VERSION ""

NS_ :

BS_:

BU_: RAD_RR RAD_RL RAD_FR RAD_FL RAD_FC CGW APA ADC

BO_ 425 APA_ECHO_DIRECT: 8 APA
 SG_ sens05De3Distance_APA m4 : 23|8@0+ (2,0) [0|500] "cm"  ADC
 SG_ sens08De2Quality_APA m7 : 35|4@0+ (10,0) [0|100] "%"  ADC
 SG_ deMsgChecksum_APA : 63|8@0+ (1,0) [0|255] ""  ADC
 SG_ sens03De2Quality_APA m2 : 35|4@0+ (10,0) [0|100] "%"  ADC
 SG_ sens12De2Distance_APA m11 : 15|8@0+ (2,0) [0|500] "cm"  ADC
 SG_ sens01De3Distance_APA m0 : 23|8@0+ (2,0) [0|500] "cm"  ADC
 SG_ sens02De1Quality_APA m1 : 39|4@0+ (10,0) [0|100] "%"  ADC
 SG_ sens07De3Quality_APA m6 : 47|4@0+ (10,0) [0|100] "%"  ADC
 SG_ sens05De1Quality_APA m4 : 39|4@0+ (10,0) [0|100] "%"  ADC
 SG_ sens10De2Distance_APA m9 : 15|8@0+ (2,0) [0|500] "cm"  ADC
 SG_ sens08De1Quality_APA m7 : 39|4@0+ (10,0) [0|100] "%"  ADC
 SG_ sens06De1Quality_APA m5 : 39|4@0+ (10,0) [0|100] "%"  ADC
 SG_ sens10De3Quality_APA m9 : 47|4@0+ (10,0) [0|100] "%"  ADC
 SG_ sens12De1Distance_APA m11 : 7|8@0+ (2,0) [0|500] "cm"  ADC
 SG_ sens11De1Quality_APA m10 : 39|4@0+ (10,0) [0|100] "%"  ADC
 SG_ sens11De2Distance_APA m10 : 15|8@0+ (2,0) [0|500] "cm"  ADC
 SG_ sens03De2Distance_APA m2 : 15|8@0+ (2,0) [0|500] "cm"  ADC
 SG_ sens12De3Distance_APA m11 : 23|8@0+ (2,0) [0|500] "cm"  ADC
 SG_ sens09De1Distance_APA m8 : 7|8@0+ (2,0) [0|500] "cm"  ADC
 SG_ sens04De1Quality_APA m3 : 39|4@0+ (10,0) [0|100] "%"  ADC
 SG_ sens01De2Distance_APA m0 : 15|8@0+ (2,0) [0|500] "cm"  ADC
 SG_ sens07De3Distance_APA m6 : 23|8@0+ (2,0) [0|500] "cm"  ADC
 SG_ sens07De2Quality_APA m6 : 35|4@0+ (10,0) [0|100] "%"  ADC
 SG_ sens04De1Distance_APA m3 : 7|8@0+ (2,0) [0|500] "cm"  ADC
 SG_ sens04De3Distance_APA m3 : 23|8@0+ (2,0) [0|500] "cm"  ADC
 SG_ sens04De2Distance_APA m3 : 15|8@0+ (2,0) [0|500] "cm"  ADC
 SG_ sens08De3Quality_APA m7 : 47|4@0+ (10,0) [0|100] "%"  ADC
 SG_ sens07De1Quality_APA m6 : 39|4@0+ (10,0) [0|100] "%"  ADC
 SG_ sens10De2Quality_APA m9 : 35|4@0+ (10,0) [0|100] "%"  ADC
 SG_ sens01De2Quality_APA m0 : 35|4@0+ (10,0) [0|100] "%"  ADC
 SG_ sens09De2Quality_APA m8 : 35|4@0+ (10,0) [0|100] "%"  ADC
 SG_ sens06De3Distance_APA m5 : 23|8@0+ (2,0) [0|500] "cm"  ADC
 SG_ sens09De1Quality_APA m8 : 39|4@0+ (10,0) [0|100] "%"  ADC
 SG_ sens06De1Distance_APA m5 : 7|8@0+ (2,0) [0|500] "cm"  ADC
 SG_ deMsgCounter_APA : 51|4@0+ (1,0) [0|15] ""  ADC
 SG_ sens07De2Distance_APA m6 : 15|8@0+ (2,0) [0|500] "cm"  ADC
 SG_ deMsgSensorIdx_APA M : 55|4@0+ (1,0) [0|11] ""  ADC
 SG_ sens12De2Quality_APA m11 : 35|4@0+ (10,0) [0|100] "%"  ADC
 SG_ sens10De1Quality_APA m9 : 39|4@0+ (10,0) [0|100] "%"  ADC
 SG_ sens04De3Quality_APA m3 : 47|4@0+ (10,0) [0|100] "%"  ADC
 SG_ sens11De3Quality_APA m10 : 47|4@0+ (10,0) [0|100] "%"  ADC
 SG_ sens03De1Quality_APA m2 : 39|4@0+ (10,0) [0|100] "%"  ADC
 SG_ sens12De1Quality_APA m11 : 39|4@0+ (10,0) [0|100] "%"  ADC
 SG_ sens09De3Quality_APA m8 : 47|4@0+ (10,0) [0|100] "%"  ADC
 SG_ sens05De2Quality_APA m4 : 35|4@0+ (10,0) [0|100] "%"  ADC
 SG_ sens06De3Quality_APA m5 : 47|4@0+ (10,0) [0|100] "%"  ADC
 SG_ sens01De3Quality_APA m0 : 47|4@0+ (10,0) [0|100] "%"  ADC
 SG_ sens09De2Distance_APA m8 : 15|8@0+ (2,0) [0|500] "cm"  ADC
 SG_ sens11De3Distance_APA m10 : 23|8@0+ (2,0) [0|500] "cm"  ADC
 SG_ sens02De2Distance_APA m1 : 15|8@0+ (2,0) [0|500] "cm"  ADC
 SG_ sens02De2Quality_APA m1 : 35|4@0+ (10,0) [0|100] "%"  ADC
 SG_ sens11De1Distance_APA m10 : 7|8@0+ (2,0) [0|500] "cm"  ADC
 SG_ sens02De1Distance_APA m1 : 7|8@0+ (2,0) [0|500] "cm"  ADC
 SG_ sens05De1Distance_APA m4 : 7|8@0+ (2,0) [0|500] "cm"  ADC
 SG_ sens03De3Quality_APA m2 : 47|4@0+ (10,0) [0|100] "%"  ADC
 SG_ sens08De2Distance_APA m7 : 15|8@0+ (2,0) [0|500] "cm"  ADC
 SG_ sens05De2Distance_APA m4 : 15|8@0+ (2,0) [0|500] "cm"  ADC
 SG_ sens06De2Distance_APA m5 : 15|8@0+ (2,0) [0|500] "cm"  ADC
 SG_ sens04De2Quality_APA m3 : 35|4@0+ (10,0) [0|100] "%"  ADC
 SG_ sens08De1Distance_APA m7 : 7|8@0+ (2,0) [0|500] "cm"  ADC
 SG_ sens10De3Distance_APA m9 : 23|8@0+ (2,0) [0|500] "cm"  ADC
 SG_ sens05De3Quality_APA m4 : 47|4@0+ (10,0) [0|100] "%"  ADC
 SG_ sens07De1Distance_APA m6 : 7|8@0+ (2,0) [0|500] "cm"  ADC
 SG_ sens10De1Distance_APA m9 : 7|8@0+ (2,0) [0|500] "cm"  ADC
 SG_ sens02De3Quality_APA m1 : 47|4@0+ (10,0) [0|100] "%"  ADC
 SG_ sens12De3Quality_APA m11 : 47|4@0+ (10,0) [0|100] "%"  ADC
 SG_ sens06De2Quality_APA m5 : 35|4@0+ (10,0) [0|100] "%"  ADC
 SG_ sens03De3Distance_APA m2 : 23|8@0+ (2,0) [0|500] "cm"  ADC
 SG_ sens09De3Distance_APA m8 : 23|8@0+ (2,0) [0|500] "cm"  ADC
 SG_ sens03De1Distance_APA m2 : 7|8@0+ (2,0) [0|500] "cm"  ADC
 SG_ sens11De2Quality_APA m10 : 35|4@0+ (10,0) [0|100] "%"  ADC
 SG_ sens01De1Quality_APA m0 : 39|4@0+ (10,0) [0|100] "%"  ADC
 SG_ sens08De3Distance_APA m7 : 23|8@0+ (2,0) [0|500] "cm"  ADC
 SG_ sens02De3Distance_APA m1 : 23|8@0+ (2,0) [0|500] "cm"  ADC
 SG_ sens01De1Distance_APA m0 : 7|8@0+ (2,0) [0|500] "cm"  ADC

BO_ 424 APA_ECHO_CROSS_RIGHT: 8 APA
 SG_ Sens06CeRgt3Quality m5 : 47|4@0+ (10,0) [0|100] "%"  ADC
 SG_ Sens08CeRgt1Distance m7 : 7|8@0+ (2,0) [0|500] "cm"  ADC
 SG_ Sens09CeRgt3Distance m8 : 23|8@0+ (2,0) [0|500] "cm"  ADC
 SG_ Sens06CeRgt1Distance m5 : 7|8@0+ (2,0) [0|500] "cm"  ADC
 SG_ Sens02CeRgt3Quality m1 : 47|4@0+ (10,0) [0|100] "%"  ADC
 SG_ Sens04CeRgt2Quality m3 : 35|4@0+ (10,0) [0|100] "%"  ADC
 SG_ Sens05CeRgt2Quality m4 : 35|4@0+ (10,0) [0|100] "%"  ADC
 SG_ Sens04CeRgt3Quality m3 : 47|4@0+ (10,0) [0|100] "%"  ADC
 SG_ CeRgtMsgSensorIdx M : 55|4@0+ (1,0) [0|11] ""  ADC
 SG_ Sens06CeRgt3Distance m5 : 23|8@0+ (2,0) [0|500] "cm"  ADC
 SG_ Sens10CeRgt3Distance m9 : 23|8@0+ (2,0) [0|500] "cm"  ADC
 SG_ Sens11CeRgt1Distance m10 : 7|8@0+ (2,0) [0|500] "cm"  ADC
 SG_ Sens05CeRgt3Quality m4 : 47|4@0+ (10,0) [0|100] "%"  ADC
 SG_ Sens06CeRgt1Quality m5 : 39|4@0+ (10,0) [0|100] "%"  ADC
 SG_ Sens11CeRgt1Quality m10 : 39|4@0+ (10,0) [0|100] "%"  ADC
 SG_ Sens01CeRgt1Quality m0 : 39|4@0+ (10,0) [0|100] "%"  ADC
 SG_ Sens04CeRgt2Distance m3 : 15|8@0+ (2,0) [0|500] "cm"  ADC
 SG_ Sens04CeRgt1Distance m3 : 7|8@0+ (2,0) [0|500] "cm"  ADC
 SG_ Sens11CeRgt2Distance m10 : 15|8@0+ (2,0) [0|500] "cm"  ADC
 SG_ Sens10CeRgt1Distance m9 : 7|8@0+ (2,0) [0|500] "cm"  ADC
 SG_ Sens12CeRgt3Quality m11 : 47|4@0+ (10,0) [0|100] "%"  ADC
 SG_ Sens12CeRgt3Distance m11 : 23|8@0+ (2,0) [0|500] "cm"  ADC
 SG_ Sens04CeRgt1Quality m3 : 39|4@0+ (10,0) [0|100] "%"  ADC
 SG_ Sens08CeRgt2Distance m7 : 15|8@0+ (2,0) [0|500] "cm"  ADC
 SG_ Sens03CeRgt1Quality m2 : 39|4@0+ (10,0) [0|100] "%"  ADC
 SG_ Sens12CeRgt1Distance m11 : 7|8@0+ (2,0) [0|500] "cm"  ADC
 SG_ Sens02CeRgt2Distance m1 : 15|8@0+ (2,0) [0|500] "cm"  ADC
 SG_ Sens08CeRgt1Quality m7 : 39|4@0+ (10,0) [0|100] "%"  ADC
 SG_ Sens08CeRgt3Distance m7 : 23|8@0+ (2,0) [0|500] "cm"  ADC
 SG_ Sens08CeRgt2Quality m7 : 35|4@0+ (10,0) [0|100] "%"  ADC
 SG_ Sens01CeRgt3Distance m0 : 23|8@0+ (2,0) [0|500] "cm"  ADC
 SG_ Sens09CeRgt1Distance m8 : 7|8@0+ (2,0) [0|500] "cm"  ADC
 SG_ Sens07CeRgt2Quality m6 : 35|4@0+ (10,0) [0|100] "%"  ADC
 SG_ Sens08CeRgt3Quality m7 : 47|4@0+ (10,0) [0|100] "%"  ADC
 SG_ Sens03CeRgt3Distance m2 : 23|8@0+ (2,0) [0|500] "cm"  ADC
 SG_ Sens05CeRgt1Quality m4 : 39|4@0+ (10,0) [0|100] "%"  ADC
 SG_ Sens07CeRgt2Distance m6 : 15|8@0+ (2,0) [0|500] "cm"  ADC
 SG_ Sens02CeRgt3Distance m1 : 23|8@0+ (2,0) [0|500] "cm"  ADC
 SG_ Sens02CeRgt1Quality m1 : 39|4@0+ (10,0) [0|100] "%"  ADC
 SG_ Sens07CeRgt3Distance m6 : 23|8@0+ (2,0) [0|500] "cm"  ADC
 SG_ Sens03CeRgt2Quality m2 : 35|4@0+ (10,0) [0|100] "%"  ADC
 SG_ Sens09CeRgt2Distance m8 : 15|8@0+ (2,0) [0|500] "cm"  ADC
 SG_ CeRgtMsgCounter : 51|4@0+ (1,0) [0|15] ""  ADC
 SG_ Sens01CeRgt2Quality m0 : 35|4@0+ (10,0) [0|100] "%"  ADC
 SG_ CeRgtMsgChecksum : 63|8@0+ (1,0) [0|255] ""  ADC
 SG_ Sens01CeRgt1Distance m0 : 7|8@0+ (2,0) [0|500] "cm"  ADC
 SG_ Sens05CeRgt3Distance m4 : 23|8@0+ (2,0) [0|500] "cm"  ADC
 SG_ Sens11CeRgt2Quality m10 : 35|4@0+ (10,0) [0|100] "%"  ADC
 SG_ Sens06CeRgt2Quality m5 : 35|4@0+ (10,0) [0|100] "%"  ADC
 SG_ Sens10CeRgt3Quality m9 : 47|4@0+ (10,0) [0|100] "%"  ADC
 SG_ Sens09CeRgt1Quality m8 : 39|4@0+ (10,0) [0|100] "%"  ADC
 SG_ Sens12CeRgt2Distance m11 : 15|8@0+ (2,0) [0|500] "cm"  ADC
 SG_ Sens11CeRgt3Quality m10 : 47|4@0+ (10,0) [0|100] "%"  ADC
 SG_ Sens05CeRgt1Distance m4 : 7|8@0+ (2,0) [0|500] "cm"  ADC
 SG_ Sens06CeRgt2Distance m5 : 15|8@0+ (2,0) [0|500] "cm"  ADC
 SG_ Sens01CeRgt2Distance m0 : 15|8@0+ (2,0) [0|500] "cm"  ADC
 SG_ Sens09CeRgt3Quality m8 : 47|4@0+ (10,0) [0|100] "%"  ADC
 SG_ Sens05CeRgt2Distance m4 : 15|8@0+ (2,0) [0|500] "cm"  ADC
 SG_ Sens07CeRgt1Distance m6 : 7|8@0+ (2,0) [0|500] "cm"  ADC
 SG_ Sens01CeRgt3Quality m0 : 47|4@0+ (10,0) [0|100] "%"  ADC
 SG_ Sens03CeRgt1Distance m2 : 7|8@0+ (2,0) [0|500] "cm"  ADC
 SG_ Sens02CeRgt2Quality m1 : 35|4@0+ (10,0) [0|100] "%"  ADC
 SG_ Sens12CeRgt2Quality m11 : 35|4@0+ (10,0) [0|100] "%"  ADC
 SG_ Sens10CeRgt2Quality m9 : 35|4@0+ (10,0) [0|100] "%"  ADC
 SG_ Sens10CeRgt2Distance m9 : 15|8@0+ (2,0) [0|500] "cm"  ADC
 SG_ Sens12CeRgt1Quality m11 : 39|4@0+ (10,0) [0|100] "%"  ADC
 SG_ Sens11CeRgt3Distance m10 : 23|8@0+ (2,0) [0|500] "cm"  ADC
 SG_ Sens02CeRgt1Distance m1 : 7|8@0+ (2,0) [0|500] "cm"  ADC
 SG_ Sens03CeRgt3Quality m2 : 47|4@0+ (10,0) [0|100] "%"  ADC
 SG_ Sens10CeRgt1Quality m9 : 39|4@0+ (10,0) [0|100] "%"  ADC
 SG_ Sens09CeRgt2Quality m8 : 35|4@0+ (10,0) [0|100] "%"  ADC
 SG_ Sens07CeRgt1Quality m6 : 39|4@0+ (10,0) [0|100] "%"  ADC
 SG_ Sens07CeRgt3Quality m6 : 47|4@0+ (10,0) [0|100] "%"  ADC
 SG_ Sens04CeRgt3Distance m3 : 23|8@0+ (2,0) [0|500] "cm"  ADC
 SG_ Sens03CeRgt2Distance m2 : 15|8@0+ (2,0) [0|500] "cm"  ADC

BO_ 423 APA_ECHO_CROSS_LEFT: 8 APA
 SG_ Sens03CeLft3Quality m2 : 47|4@0+ (10,0) [0|100] "%"  ADC
 SG_ Sens02CeLft1Distance m1 : 7|8@0+ (2,0) [0|500] "cm"  ADC
 SG_ Sens01CeLft1Distance m0 : 7|8@0+ (2,0) [0|500] "cm"  ADC
 SG_ Sens10CeLft1Quality m9 : 39|4@0+ (10,0) [0|100] "%"  ADC
 SG_ Sens04CeLft2Distance m3 : 15|8@0+ (2,0) [0|500] "cm"  ADC
 SG_ Sens05CeLft3Quality m4 : 47|4@0+ (10,0) [0|100] "%"  ADC
 SG_ Sens03CeLft2Quality m2 : 35|4@0+ (10,0) [0|100] "%"  ADC
 SG_ Sens03CeLft1Quality m2 : 39|4@0+ (10,0) [0|100] "%"  ADC
 SG_ Sens12CeLft2Quality m11 : 35|4@0+ (10,0) [0|100] "%"  ADC
 SG_ Sens01CeLft2Quality m0 : 35|4@0+ (10,0) [0|100] "%"  ADC
 SG_ Sens11CeLft2Quality m10 : 35|4@0+ (10,0) [0|100] "%"  ADC
 SG_ Sens05CeLft1Distance m4 : 7|8@0+ (2,0) [0|500] "cm"  ADC
 SG_ Sens06CeLft2Quality m5 : 35|4@0+ (10,0) [0|100] "%"  ADC
 SG_ Sens08CeLft1Distance m7 : 7|8@0+ (2,0) [0|500] "cm"  ADC
 SG_ Sens03CeLft2Distance m2 : 15|8@0+ (2,0) [0|500] "cm"  ADC
 SG_ Sens10CeLft1Distance m9 : 7|8@0+ (2,0) [0|500] "cm"  ADC
 SG_ Sens07CeLft3Distance m6 : 23|8@0+ (2,0) [0|500] "cm"  ADC
 SG_ Sens10CeLft2Distance m9 : 15|8@0+ (2,0) [0|500] "cm"  ADC
 SG_ Sens11CeLft3Distance m10 : 23|8@0+ (2,0) [0|500] "cm"  ADC
 SG_ Sens09CeLft1Distance m8 : 7|8@0+ (2,0) [0|500] "cm"  ADC
 SG_ Sens02CeLft3Quality m1 : 47|4@0+ (10,0) [0|100] "%"  ADC
 SG_ Sens06CeLft1Distance m5 : 7|8@0+ (2,0) [0|500] "cm"  ADC
 SG_ Sens04CeLft3Distance m3 : 23|8@0+ (2,0) [0|500] "cm"  ADC
 SG_ Sens08CeLft3Quality m7 : 47|4@0+ (10,0) [0|100] "%"  ADC
 SG_ CeLftMsgChecksum : 63|8@0+ (1,0) [0|255] ""  ADC
 SG_ Sens08CeLft2Quality m7 : 35|4@0+ (10,0) [0|100] "%"  ADC
 SG_ Sens04CeLft3Quality m3 : 47|4@0+ (10,0) [0|100] "%"  ADC
 SG_ Sens07CeLft3Quality m6 : 47|4@0+ (10,0) [0|100] "%"  ADC
 SG_ Sens09CeLft2Distance m8 : 15|8@0+ (2,0) [0|500] "cm"  ADC
 SG_ Sens11CeLft3Quality m10 : 47|4@0+ (10,0) [0|100] "%"  ADC
 SG_ Sens10CeLft3Distance m9 : 23|8@0+ (2,0) [0|500] "cm"  ADC
 SG_ CeLftMsgCounter : 51|4@0+ (1,0) [0|15] ""  ADC
 SG_ Sens08CeLft2Distance m7 : 15|8@0+ (2,0) [0|500] "cm"  ADC
 SG_ Sens06CeLft3Quality m5 : 47|4@0+ (10,0) [0|100] "%"  ADC
 SG_ Sens09CeLft3Distance m8 : 23|8@0+ (2,0) [0|500] "cm"  ADC
 SG_ Sens01CeLft1Quality m0 : 39|4@0+ (10,0) [0|100] "%"  ADC
 SG_ Sens09CeLft2Quality m8 : 35|4@0+ (10,0) [0|100] "%"  ADC
 SG_ Sens10CeLft3Quality m9 : 47|4@0+ (10,0) [0|100] "%"  ADC
 SG_ Sens05CeLft2Quality m4 : 35|4@0+ (10,0) [0|100] "%"  ADC
 SG_ Sens01CeLft3Quality m0 : 47|4@0+ (10,0) [0|100] "%"  ADC
 SG_ Sens06CeLft3Distance m5 : 23|8@0+ (2,0) [0|500] "cm"  ADC
 SG_ Sens07CeLft2Distance m6 : 15|8@0+ (2,0) [0|500] "cm"  ADC
 SG_ Sens02CeLft2Quality m1 : 35|4@0+ (10,0) [0|100] "%"  ADC
 SG_ Sens07CeLft1Distance m6 : 7|8@0+ (2,0) [0|500] "cm"  ADC
 SG_ Sens01CeLft2Distance m0 : 15|8@0+ (2,0) [0|500] "cm"  ADC
 SG_ Sens07CeLft1Quality m6 : 39|4@0+ (10,0) [0|100] "%"  ADC
 SG_ Sens12CeLft2Distance m11 : 15|8@0+ (2,0) [0|500] "cm"  ADC
 SG_ Sens11CeLft2Distance m10 : 15|8@0+ (2,0) [0|500] "cm"  ADC
 SG_ Sens09CeLft3Quality m8 : 47|4@0+ (10,0) [0|100] "%"  ADC
 SG_ Sens05CeLft2Distance m4 : 15|8@0+ (2,0) [0|500] "cm"  ADC
 SG_ Sens07CeLft2Quality m6 : 35|4@0+ (10,0) [0|100] "%"  ADC
 SG_ Sens03CeLft1Distance m2 : 7|8@0+ (2,0) [0|500] "cm"  ADC
 SG_ Sens03CeLft3Distance m2 : 23|8@0+ (2,0) [0|500] "cm"  ADC
 SG_ Sens01CeLft3Distance m0 : 23|8@0+ (2,0) [0|500] "cm"  ADC
 SG_ Sens04CeLft2Quality m3 : 35|4@0+ (10,0) [0|100] "%"  ADC
 SG_ Sens12CeLft1Quality m11 : 39|4@0+ (10,0) [0|100] "%"  ADC
 SG_ Sens04CeLft1Distance m3 : 7|8@0+ (2,0) [0|500] "cm"  ADC
 SG_ Sens02CeLft1Quality m1 : 39|4@0+ (10,0) [0|100] "%"  ADC
 SG_ Sens12CeLft3Distance m11 : 23|8@0+ (2,0) [0|500] "cm"  ADC
 SG_ Sens09CeLft1Quality m8 : 39|4@0+ (10,0) [0|100] "%"  ADC
 SG_ Sens06CeLft2Distance m5 : 15|8@0+ (2,0) [0|500] "cm"  ADC
 SG_ Sens11CeLft1Quality m10 : 39|4@0+ (10,0) [0|100] "%"  ADC
 SG_ Sens10CeLft2Quality m9 : 35|4@0+ (10,0) [0|100] "%"  ADC
 SG_ Sens12CeLft1Distance m11 : 7|8@0+ (2,0) [0|500] "cm"  ADC
 SG_ Sens11CeLft1Distance m10 : 7|8@0+ (2,0) [0|500] "cm"  ADC
 SG_ Sens05CeLft1Quality m4 : 39|4@0+ (10,0) [0|100] "%"  ADC
 SG_ CeLftMsgSensorIdx M : 55|4@0+ (1,0) [0|11] ""  ADC
 SG_ Sens06CeLft1Quality m5 : 39|4@0+ (10,0) [0|100] "%"  ADC
 SG_ Sens02CeLft2Distance m1 : 15|8@0+ (2,0) [0|500] "cm"  ADC
 SG_ Sens12CeLft3Quality m11 : 47|4@0+ (10,0) [0|100] "%"  ADC
 SG_ Sens08CeLft1Quality m7 : 39|4@0+ (10,0) [0|100] "%"  ADC
 SG_ Sens04CeLft1Quality m3 : 39|4@0+ (10,0) [0|100] "%"  ADC
 SG_ Sens05CeLft3Distance m4 : 23|8@0+ (2,0) [0|500] "cm"  ADC
 SG_ Sens02CeLft3Distance m1 : 23|8@0+ (2,0) [0|500] "cm"  ADC
 SG_ Sens08CeLft3Distance m7 : 23|8@0+ (2,0) [0|500] "cm"  ADC

BO_ 357 APA_ADC_10: 8 APA
 SG_ MapObj19P1Y m1 : 29|10@0+ (4,-2044) [-2044|2044] ""  ADC
 SG_ MapObj09Problty m0 : 63|3@0+ (16.666,0) [0|100] "%"  ADC
 SG_ MapObj09P1Y m0 : 29|10@0+ (4,-2044) [-2044|2044] ""  ADC
 SG_ MapObj09P1X m0 : 23|10@0+ (4,-2044) [-2044|2044] ""  ADC
 SG_ MapObj19Problty m1 : 63|3@0+ (16.666,0) [0|100] "%"  ADC
 SG_ MapObj09P2X m0 : 35|10@0+ (4,-2044) [-2044|2044] ""  ADC
 SG_ APA_ADC_10_MsgCntr : 15|2@0+ (1,0) [0|3] ""  ADC
 SG_ MapObj19P2X m1 : 35|10@0+ (4,-2044) [-2044|2044] ""  ADC
 SG_ MapObj19Typ m1 : 10|3@0+ (1,0) [0|7] ""  ADC
 SG_ MapObj09HeiProblty m0 : 60|3@0+ (16.666,0) [0|100] "%"  ADC
 SG_ MapObj09Hei m0 : 57|2@0+ (1,0) [0|3] ""  ADC
 SG_ MapObj09P2Y m0 : 41|10@0+ (4,-2044) [-2044|2044] ""  ADC
 SG_ MapObj09Typ m0 : 10|3@0+ (1,0) [0|7] ""  ADC
 SG_ MapObj19P2Y m1 : 41|10@0+ (4,-2044) [-2044|2044] ""  ADC
 SG_ MapObjX9Offs M : 13|3@0+ (1,0) [0|7] ""  ADC
 SG_ APA_ADC_10_CRC : 7|8@0+ (1,0) [0|255] ""  ADC
 SG_ MapObj19HeiProblty m1 : 60|3@0+ (16.666,0) [0|100] "%"  ADC
 SG_ MapObj19Hei m1 : 57|2@0+ (1,0) [0|3] ""  ADC
 SG_ MapObj19P1X m1 : 23|10@0+ (4,-2044) [-2044|2044] ""  ADC

BO_ 356 APA_ADC_09: 8 APA
 SG_ MapObj08P1X m0 : 23|10@0+ (4,-2044) [-2044|2044] ""  ADC
 SG_ MapObj08P2Y m0 : 41|10@0+ (4,-2044) [-2044|2044] ""  ADC
 SG_ APA_ADC_09_MsgCntr : 15|2@0+ (1,0) [0|3] ""  ADC
 SG_ MapObj08Hei m0 : 57|2@0+ (1,0) [0|3] ""  ADC
 SG_ MapObjX8Offs M : 13|3@0+ (1,0) [0|7] ""  ADC
 SG_ MapObj08HeiProblty m0 : 60|3@0+ (16.666,0) [0|100] "%"  ADC
 SG_ MapObj18Hei m1 : 57|2@0+ (1,0) [0|3] ""  ADC
 SG_ MapObj18P2X m1 : 35|10@0+ (4,-2044) [-2044|2044] ""  ADC
 SG_ MapObj08P2X m0 : 35|10@0+ (4,-2044) [-2044|2044] ""  ADC
 SG_ MapObj08P1Y m0 : 29|10@0+ (4,-2044) [-2044|2044] ""  ADC
 SG_ MapObj18HeiProblty m1 : 60|3@0+ (16.666,0) [0|100] "%"  ADC
 SG_ MapObj08Typ m0 : 10|3@0+ (1,0) [0|7] ""  ADC
 SG_ MapObj08Problty m0 : 63|3@0+ (16.666,0) [0|100] "%"  ADC
 SG_ MapObj18Typ m1 : 10|3@0+ (1,0) [0|7] ""  ADC
 SG_ MapObj18P1X m1 : 23|10@0+ (4,-2044) [-2044|2044] ""  ADC
 SG_ APA_ADC_09_CRC : 7|8@0+ (1,0) [0|255] ""  ADC
 SG_ MapObj18Problty m1 : 63|3@0+ (16.666,0) [0|100] "%"  ADC
 SG_ MapObj18P1Y m1 : 29|10@0+ (4,-2044) [-2044|2044] ""  ADC
 SG_ MapObj18P2Y m1 : 41|10@0+ (4,-2044) [-2044|2044] ""  ADC

BO_ 355 APA_ADC_08: 8 APA
 SG_ MapObj17HeiProblty m1 : 60|3@0+ (16.666,0) [0|100] "%"  ADC
 SG_ MapObj17Problty m1 : 63|3@0+ (16.666,0) [0|100] "%"  ADC
 SG_ MapObj07P2X m0 : 35|10@0+ (4,-2044) [-2044|2044] ""  ADC
 SG_ APA_ADC_08_CRC : 7|8@0+ (1,0) [0|255] ""  ADC
 SG_ MapObj07P1X m0 : 23|10@0+ (4,-2044) [-2044|2044] ""  ADC
 SG_ MapObj07P1Y m0 : 29|10@0+ (4,-2044) [-2044|2044] ""  ADC
 SG_ MapObj07Problty m0 : 63|3@0+ (16.666,0) [0|100] "%"  ADC
 SG_ APA_ADC_08_MsgCntr : 15|2@0+ (1,0) [0|3] ""  ADC
 SG_ MapObj07Typ m0 : 10|3@0+ (1,0) [0|7] ""  ADC
 SG_ MapObj17Typ m1 : 10|3@0+ (1,0) [0|7] ""  ADC
 SG_ MapObj07HeiProblty m0 : 60|3@0+ (16.666,0) [0|100] "%"  ADC
 SG_ MapObj07Hei m0 : 57|2@0+ (1,0) [0|3] ""  ADC
 SG_ MapObj17P2X m1 : 35|10@0+ (4,-2044) [-2044|2044] ""  ADC
 SG_ MapObj17P2Y m1 : 41|10@0+ (4,-2044) [-2044|2044] ""  ADC
 SG_ MapObj07P2Y m0 : 41|10@0+ (4,-2044) [-2044|2044] ""  ADC
 SG_ MapObjX7Offs M : 13|3@0+ (1,0) [0|7] ""  ADC
 SG_ MapObj17P1Y m1 : 29|10@0+ (4,-2044) [-2044|2044] ""  ADC
 SG_ MapObj17P1X m1 : 23|10@0+ (4,-2044) [-2044|2044] ""  ADC
 SG_ MapObj17Hei m1 : 57|2@0+ (1,0) [0|3] ""  ADC

BO_ 354 APA_ADC_07: 8 APA
 SG_ APA_ADC_07_MsgCntr : 15|2@0+ (1,0) [0|3] ""  ADC
 SG_ MapObj16P2X m1 : 35|10@0+ (4,-2044) [-2044|2044] ""  ADC
 SG_ MapObj06Typ m0 : 10|3@0+ (1,0) [0|7] ""  ADC
 SG_ MapObj06Hei m0 : 57|2@0+ (1,0) [0|3] ""  ADC
 SG_ MapObj16P2Y m1 : 41|10@0+ (4,-2044) [-2044|2044] ""  ADC
 SG_ MapObj16Problty m1 : 63|3@0+ (16.666,0) [0|100] "%"  ADC
 SG_ MapObj06P1Y m0 : 29|10@0+ (4,-2044) [-2044|2044] ""  ADC
 SG_ MapObj16P1Y m1 : 29|10@0+ (4,-2044) [-2044|2044] ""  ADC
 SG_ MapObj06HeiProblty m0 : 60|3@0+ (16.666,0) [0|100] "%"  ADC
 SG_ MapObj16Hei m1 : 57|2@0+ (1,0) [0|3] ""  ADC
 SG_ MapObj06Problty m0 : 63|3@0+ (16.666,0) [0|100] "%"  ADC
 SG_ MapObj06P1X m0 : 23|10@0+ (4,-2044) [-2044|2044] ""  ADC
 SG_ MapObj16P1X m1 : 23|10@0+ (4,-2044) [-2044|2044] ""  ADC
 SG_ MapObj06P2X m0 : 35|10@0+ (4,-2044) [-2044|2044] ""  ADC
 SG_ MapObj16Typ m1 : 10|3@0+ (1,0) [0|7] ""  ADC
 SG_ MapObj16HeiProblty m1 : 60|3@0+ (16.666,0) [0|100] "%"  ADC
 SG_ MapObjX6Offs M : 13|3@0+ (1,0) [0|7] ""  ADC
 SG_ APA_ADC_07_CRC : 7|8@0+ (1,0) [0|255] ""  ADC
 SG_ MapObj06P2Y m0 : 41|10@0+ (4,-2044) [-2044|2044] ""  ADC

BO_ 353 APA_ADC_06: 8 APA
 SG_ MapObjX5Offs M : 13|3@0+ (1,0) [0|7] ""  ADC
 SG_ MapObj15Hei m1 : 57|2@0+ (1,0) [0|3] ""  ADC
 SG_ MapObj15Problty m1 : 63|3@0+ (16.666,0) [0|100] "%"  ADC
 SG_ MapObj15Typ m1 : 10|3@0+ (1,0) [0|7] ""  ADC
 SG_ MapObj15HeiProblty m1 : 60|3@0+ (16.666,0) [0|100] "%"  ADC
 SG_ MapObj15P1Y m1 : 29|10@0+ (4,-2044) [-2044|2044] ""  ADC
 SG_ MapObj05P1Y m0 : 29|10@0+ (4,-2044) [-2044|2044] ""  ADC
 SG_ MapObj05P1X m0 : 23|10@0+ (4,-2044) [-2044|2044] ""  ADC
 SG_ MapObj05Typ m0 : 10|3@0+ (1,0) [0|7] ""  ADC
 SG_ APA_ADC_06_MsgCntr : 15|2@0+ (1,0) [0|3] ""  ADC
 SG_ MapObj05Problty m0 : 63|3@0+ (16.666,0) [0|100] "%"  ADC
 SG_ MapObj05Hei m0 : 57|2@0+ (1,0) [0|3] ""  ADC
 SG_ MapObj15P2Y m1 : 41|10@0+ (4,-2044) [-2044|2044] ""  ADC
 SG_ APA_ADC_06_CRC : 7|8@0+ (1,0) [0|255] ""  ADC
 SG_ MapObj15P2X m1 : 35|10@0+ (4,-2044) [-2044|2044] ""  ADC
 SG_ MapObj05P2X m0 : 35|10@0+ (4,-2044) [-2044|2044] ""  ADC
 SG_ MapObj15P1X m1 : 23|10@0+ (4,-2044) [-2044|2044] ""  ADC
 SG_ MapObj05P2Y m0 : 41|10@0+ (4,-2044) [-2044|2044] ""  ADC
 SG_ MapObj05HeiProblty m0 : 60|3@0+ (16.666,0) [0|100] "%"  ADC

BO_ 352 APA_ADC_05: 8 APA
 SG_ MapObj14Problty m1 : 63|3@0+ (16.666,0) [0|100] "%"  ADC
 SG_ MapObj04Problty m0 : 63|3@0+ (16.666,0) [0|100] "%"  ADC
 SG_ MapObj04P1Y m0 : 29|10@0+ (4,-2044) [-2044|2044] ""  ADC
 SG_ MapObj04Typ m0 : 10|3@0+ (1,0) [0|7] ""  ADC
 SG_ MapObj14P1Y m1 : 29|10@0+ (4,-2044) [-2044|2044] ""  ADC
 SG_ MapObj14Typ m1 : 10|3@0+ (1,0) [0|7] ""  ADC
 SG_ MapObj04Hei m0 : 57|2@0+ (1,0) [0|3] ""  ADC
 SG_ MapObj14P2Y m1 : 41|10@0+ (4,-2044) [-2044|2044] ""  ADC
 SG_ MapObj14P1X m1 : 23|10@0+ (4,-2044) [-2044|2044] ""  ADC
 SG_ MapObj04P1X m0 : 23|10@0+ (4,-2044) [-2044|2044] ""  ADC
 SG_ MapObj14P2X m1 : 35|10@0+ (4,-2044) [-2044|2044] ""  ADC
 SG_ APA_ADC_05_CRC : 7|8@0+ (1,0) [0|255] ""  ADC
 SG_ MapObjX4Offs M : 13|3@0+ (1,0) [0|7] ""  ADC
 SG_ MapObj14Hei m1 : 57|2@0+ (1,0) [0|3] ""  ADC
 SG_ APA_ADC_05_MsgCntr : 15|2@0+ (1,0) [0|3] ""  ADC
 SG_ MapObj04P2Y m0 : 41|10@0+ (4,-2044) [-2044|2044] ""  ADC
 SG_ MapObj04P2X m0 : 35|10@0+ (4,-2044) [-2044|2044] ""  ADC
 SG_ MapObj04HeiProblty m0 : 60|3@0+ (16.666,0) [0|100] "%"  ADC
 SG_ MapObj14HeiProblty m1 : 60|3@0+ (16.666,0) [0|100] "%"  ADC

BO_ 351 APA_ADC_04: 8 APA
 SG_ MapObj13P1X m1 : 23|10@0+ (4,-2044) [-2044|2044] ""  ADC
 SG_ MapObjX3Offs M : 13|3@0+ (1,0) [0|7] ""  ADC
 SG_ APA_ADC_04_CRC : 7|8@0+ (1,0) [0|255] ""  ADC
 SG_ MapObj13P1Y m1 : 29|10@0+ (4,-2044) [-2044|2044] ""  ADC
 SG_ MapObj13HeiProblty m1 : 60|3@0+ (16.666,0) [0|100] "%"  ADC
 SG_ MapObj03P2X m0 : 35|10@0+ (4,-2044) [-2044|2044] ""  ADC
 SG_ MapObj03P2Y m0 : 41|10@0+ (4,-2044) [-2044|2044] ""  ADC
 SG_ APA_ADC_04_MsgCntr : 15|2@0+ (1,0) [0|3] ""  ADC
 SG_ MapObj13Problty m1 : 63|3@0+ (16.666,0) [0|100] "%"  ADC
 SG_ MapObj03Problty m0 : 63|3@0+ (16.666,0) [0|100] "%"  ADC
 SG_ MapObj13Hei m1 : 57|2@0+ (1,0) [0|3] ""  ADC
 SG_ MapObj03P1Y m0 : 29|10@0+ (4,-2044) [-2044|2044] ""  ADC
 SG_ MapObj13Typ m1 : 10|3@0+ (1,0) [0|7] ""  ADC
 SG_ MapObj03P1X m0 : 23|10@0+ (4,-2044) [-2044|2044] ""  ADC
 SG_ MapObj13P2Y m1 : 41|10@0+ (4,-2044) [-2044|2044] ""  ADC
 SG_ MapObj03Hei m0 : 57|2@0+ (1,0) [0|3] ""  ADC
 SG_ MapObj13P2X m1 : 35|10@0+ (4,-2044) [-2044|2044] ""  ADC
 SG_ MapObj03Typ m0 : 10|3@0+ (1,0) [0|7] ""  ADC
 SG_ MapObj03HeiProblty m0 : 60|3@0+ (16.666,0) [0|100] "%"  ADC

BO_ 350 APA_ADC_03: 8 APA
 SG_ MapObj02P2Y m0 : 41|10@0+ (4,-2044) [-2044|2044] ""  ADC
 SG_ MapObj02Typ m0 : 10|3@0+ (1,0) [0|7] ""  ADC
 SG_ MapObj02P2X m0 : 35|10@0+ (4,-2044) [-2044|2044] ""  ADC
 SG_ MapObj12P2Y m1 : 41|10@0+ (4,-2044) [-2044|2044] ""  ADC
 SG_ MapObj12P2X m1 : 35|10@0+ (4,-2044) [-2044|2044] ""  ADC
 SG_ MapObj12Hei m1 : 57|2@0+ (1,0) [0|3] ""  ADC
 SG_ MapObj02HeiProblty m0 : 60|3@0+ (16.666,0) [0|100] "%"  ADC
 SG_ MapObj12P1Y m1 : 29|10@0+ (4,-2044) [-2044|2044] ""  ADC
 SG_ MapObj12Problty m1 : 63|3@0+ (16.666,0) [0|100] "%"  ADC
 SG_ MapObj02Problty m0 : 63|3@0+ (16.666,0) [0|100] "%"  ADC
 SG_ MapObj12HeiProblty m1 : 60|3@0+ (16.666,0) [0|100] "%"  ADC
 SG_ APA_ADC_03_CRC : 7|8@0+ (1,0) [0|255] ""  ADC
 SG_ MapObj02P1Y m0 : 29|10@0+ (4,-2044) [-2044|2044] ""  ADC
 SG_ MapObj02Hei m0 : 57|2@0+ (1,0) [0|3] ""  ADC
 SG_ MapObj02P1X m0 : 23|10@0+ (4,-2044) [-2044|2044] ""  ADC
 SG_ APA_ADC_03_MsgCntr : 15|2@0+ (1,0) [0|3] ""  ADC
 SG_ MapObj12P1X m1 : 23|10@0+ (4,-2044) [-2044|2044] ""  ADC
 SG_ MapObjX2Offs M : 13|3@0+ (1,0) [0|7] ""  ADC
 SG_ MapObj12Typ m1 : 10|3@0+ (1,0) [0|7] ""  ADC

BO_ 349 APA_ADC_02: 8 APA
 SG_ MapObj01Hei m0 : 57|2@0+ (1,0) [0|3] ""  ADC
 SG_ MapObj01P1Y m0 : 29|10@0+ (4,-2044) [-2044|2044] ""  ADC
 SG_ MapObj11P1Y m1 : 29|10@0+ (4,-2044) [-2044|2044] ""  ADC
 SG_ MapObj01P1X m0 : 23|10@0+ (4,-2044) [-2044|2044] ""  ADC
 SG_ MapObj11P2Y m1 : 41|10@0+ (4,-2044) [-2044|2044] ""  ADC
 SG_ MapObj11Hei m1 : 57|2@0+ (1,0) [0|3] ""  ADC
 SG_ MapObj11P1X m1 : 23|10@0+ (4,-2044) [-2044|2044] ""  ADC
 SG_ APA_ADC_02_MsgCntr : 15|2@0+ (1,0) [0|3] ""  ADC
 SG_ MapObj11Problty m1 : 63|3@0+ (16.666,0) [0|100] "%"  ADC
 SG_ APA_ADC_02_CRC : 7|8@0+ (1,0) [0|255] ""  ADC
 SG_ MapObj01Problty m0 : 63|3@0+ (16.666,0) [0|100] "%"  ADC
 SG_ MapObj11P2X m1 : 35|10@0+ (4,-2044) [-2044|2044] ""  ADC
 SG_ MapObj11Typ m1 : 10|3@0+ (1,0) [0|7] ""  ADC
 SG_ MapObj01HeiProblty m0 : 60|3@0+ (16.666,0) [0|100] "%"  ADC
 SG_ MapObjX1Offs M : 13|3@0+ (1,0) [0|7] ""  ADC
 SG_ MapObj11HeiProblty m1 : 60|3@0+ (16.666,0) [0|100] "%"  ADC
 SG_ MapObj01Typ m0 : 10|3@0+ (1,0) [0|7] ""  ADC
 SG_ MapObj01P2X m0 : 35|10@0+ (4,-2044) [-2044|2044] ""  ADC
 SG_ MapObj01P2Y m0 : 41|10@0+ (4,-2044) [-2044|2044] ""  ADC

BO_ 348 APA_ADC_01: 8 APA
 SG_ MapObj10P2Y m1 : 41|10@0+ (4,-2044) [-2044|2044] ""  ADC
 SG_ APA_ADC_01_MsgCntr : 15|2@0+ (1,0) [0|3] ""  ADC
 SG_ MapObj10Problty m1 : 63|3@0+ (16.666,0) [0|100] "%"  ADC
 SG_ MapObj00Problty m0 : 63|3@0+ (16.666,0) [0|100] "%"  ADC
 SG_ MapObj00P2X m0 : 35|10@0+ (4,-2044) [-2044|2044] ""  ADC
 SG_ MapObj10Typ m1 : 10|3@0+ (1,0) [0|7] ""  ADC
 SG_ MapObj00HeiProblty m0 : 60|3@0+ (16.666,0) [0|100] "%"  ADC
 SG_ APA_ADC_01_CRC : 7|8@0+ (1,0) [0|255] ""  ADC
 SG_ MapObj10P2X m1 : 35|10@0+ (4,-2044) [-2044|2044] ""  ADC
 SG_ MapObj00P1Y m0 : 29|10@0+ (4,-2044) [-2044|2044] ""  ADC
 SG_ MapObj10HeiProblty m1 : 60|3@0+ (16.666,0) [0|100] "%"  ADC
 SG_ MapObj00Typ m0 : 10|3@0+ (1,0) [0|7] ""  ADC
 SG_ MapObj10Hei m1 : 57|2@0+ (1,0) [0|3] ""  ADC
 SG_ MapObjX0Offs M : 13|3@0+ (1,0) [0|7] ""  ADC
 SG_ MapObj10P1Y m1 : 29|10@0+ (4,-2044) [-2044|2044] ""  ADC
 SG_ MapObj00P2Y m0 : 41|10@0+ (4,-2044) [-2044|2044] ""  ADC
 SG_ MapObj10P1X m1 : 23|10@0+ (4,-2044) [-2044|2044] ""  ADC
 SG_ MapObj00Hei m0 : 57|2@0+ (1,0) [0|3] ""  ADC
 SG_ MapObj00P1X m0 : 23|10@0+ (4,-2044) [-2044|2044] ""  ADC

BO_ 648 APA_07: 8 APA
 SG_ ApaPscSlotCrossRiVehY m3 : 23|11@0+ (2,-2048) [-2048|2046] "cm"  CGW,ADC
 SG_ ApaXSlotYVehX m7 : 2|11@0+ (2,-2048) [-2048|2046] "cm"  CGW,ADC
 SG_ ApaPocSlotParallelRiVehY m5 : 23|11@0+ (2,-2048) [-2048|2046] "cm"  CGW,ADC
 SG_ ApaPocSlotParallelLeSizeY m4 : 63|8@0+ (4,0) [0|1020] "cm"  ADC,CGW
 SG_ ApaPscSlotCrossLeVehX m2 : 2|11@0+ (2,-2048) [-2048|2046] "cm"  CGW,ADC
 SG_ ApaXSlotYSizeX m7 : 55|8@0+ (4,0) [0|1020] "cm"  ADC,CGW
 SG_ ApaPscSlotCrossRiVehPsi m3 : 28|13@0+ (0.0009765625,0) [0|7.9990234375] "radians"  CGW,ADC
 SG_ ApaPocSlotParallelRiVehPsi m5 : 28|13@0+ (0.0009765625,0) [0|7.9990234375] "radians"  ADC,CGW
 SG_ ApaPocSlotParallelRiSizeX m5 : 55|8@0+ (4,0) [0|1020] "cm"  ADC,CGW
 SG_ ApaPocSlotParallelRiSizeY m5 : 63|8@0+ (4,0) [0|1020] "cm"  ADC,CGW
 SG_ ApaPscSlotCrossRiSizeY m3 : 63|8@0+ (4,0) [0|1020] "cm"  CGW,ADC
 SG_ ApaPscSlotParallelRiVehX m1 : 2|11@0+ (2,-2048) [-2048|2046] "cm"  ADC,CGW
 SG_ ApaPscSlotParallelLeVehPsi m0 : 28|13@0+ (0.0009765625,0) [0|7.9990234375] "radians"  ADC,CGW
 SG_ ApaPocSlotParallelLeVehY m4 : 23|11@0+ (2,-2048) [-2048|2046] "cm"  CGW,ADC
 SG_ ApaXSlotYSizeY m7 : 63|8@0+ (4,0) [0|1020] "cm"  CGW,ADC
 SG_ ApaXSlotYVehPsi m7 : 28|13@0+ (0.0009765625,0) [0|7.9990234375] "radians"  ADC,CGW
 SG_ ApaPscSlotParallelRiSizeX m1 : 55|8@0+ (4,0) [0|1020] "cm"  ADC,CGW
 SG_ ApaPscSlotParallelLeVehY m0 : 23|11@0+ (2,-2048) [-2048|2046] "cm"  ADC,CGW
 SG_ ApaPscSlotParallelLeSizeX m0 : 55|8@0+ (4,0) [0|1020] "cm"  CGW,ADC
 SG_ ApaPocSlotParallelLeVehPsi m4 : 28|13@0+ (0.0009765625,0) [0|7.9990234375] "radians"  ADC,CGW
 SG_ ApaPscSlotParallelRiSizeY m1 : 63|8@0+ (4,0) [0|1020] "cm"  ADC,CGW
 SG_ ApaPocSlotParallelLeSizeX m4 : 55|8@0+ (4,0) [0|1020] "cm"  CGW,ADC
 SG_ ApaPscSlotCrossLeVehPsi m2 : 28|13@0+ (0.0009765625,0) [0|7.9990234375] "radians"  CGW,ADC
 SG_ ApaPscSlotCrossRiVehX m3 : 2|11@0+ (2,-2048) [-2048|2046] "cm"  ADC,CGW
 SG_ ApaPscVehSlotTyp M : 7|3@0+ (1,0) [0|7] ""  ADC,CGW
 SG_ ApaPocSlotParallelLeVehX m4 : 2|11@0+ (2,-2048) [-2048|2046] "cm"  CGW,ADC
 SG_ ApaPscSlotCrossLeSizeX m2 : 55|8@0+ (4,0) [0|1020] "cm"  ADC,CGW
 SG_ ApaPscSlotParallelLeSizeY m0 : 63|8@0+ (4,0) [0|1020] "cm"  ADC,CGW
 SG_ ApaPscSlotParallelLeVehX m0 : 2|11@0+ (2,-2048) [-2048|2046] "cm"  ADC,CGW
 SG_ ApaPscSlotParallelRiVehPsi m1 : 28|13@0+ (0.0009765625,0) [0|7.9990234375] "radians"  ADC,CGW
 SG_ ApaXSlotYVehY m7 : 23|11@0+ (2,-2048) [-2048|2046] "cm"  ADC,CGW
 SG_ ApaPscSlotParallelRiVehY m1 : 23|11@0+ (2,-2048) [-2048|2046] "cm"  ADC,CGW
 SG_ ApaPscSlotCrossRiSizeX m3 : 55|8@0+ (4,0) [0|1020] "cm"  CGW,ADC
 SG_ ApaPscSlotCrossLeVehY m2 : 23|11@0+ (2,-2048) [-2048|2046] "cm"  ADC,CGW
 SG_ ApaPocSlotParallelRiVehX m5 : 2|11@0+ (2,-2048) [-2048|2046] "cm"  CGW,ADC
 SG_ ApaPscSlotCrossLeSizeY m2 : 63|8@0+ (4,0) [0|1020] "cm"  ADC,CGW

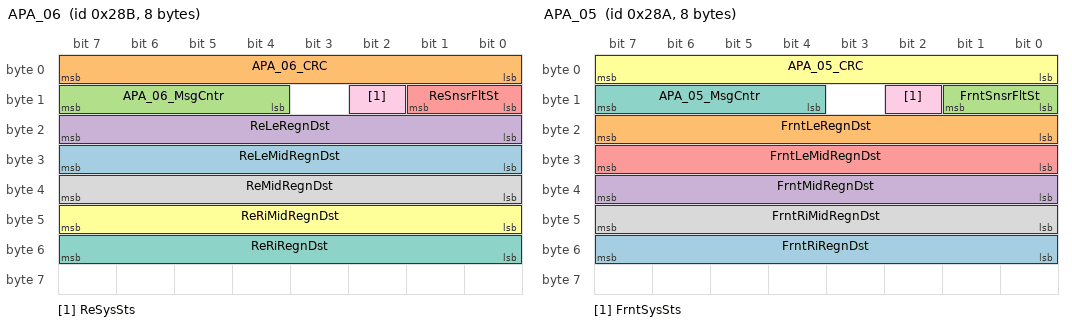
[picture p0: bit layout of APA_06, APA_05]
BO_ 651 APA_06: 8 APA
 SG_ ReLeMidRegnDst : 31|8@0+ (1,0) [0|255] "cm"  ADC,CGW
 SG_ APA_06_CRC : 7|8@0+ (1,0) [0|255] ""  CGW,ADC
 SG_ APA_06_MsgCntr : 15|4@0+ (1,0) [0|15] ""  ADC,CGW
 SG_ ReLeRegnDst : 23|8@0+ (1,0) [0|255] "cm"  CGW,ADC
 SG_ ReSnsrFltSt : 9|2@0+ (1,0) [0|3] ""  ADC,CGW
 SG_ ReRiMidRegnDst : 47|8@0+ (1,0) [0|255] "cm"  CGW,ADC
 SG_ ReRiRegnDst : 55|8@0+ (1,0) [0|255] "cm"  ADC,CGW
 SG_ ReMidRegnDst : 39|8@0+ (1,0) [0|255] "cm"  ADC,CGW
 SG_ ReSysSts : 10|1@0+ (1,0) [0|1] ""  CGW,ADC

BO_ 650 APA_05: 8 APA
 SG_ FrntRiRegnDst : 55|8@0+ (1,0) [0|255] "cm"  ADC,CGW
 SG_ FrntLeRegnDst : 23|8@0+ (1,0) [0|255] "cm"  ADC,CGW
 SG_ FrntSnsrFltSt : 9|2@0+ (1,0) [0|3] ""  CGW,ADC
 SG_ FrntMidRegnDst : 39|8@0+ (1,0) [0|255] "cm"  CGW,ADC
 SG_ FrntLeMidRegnDst : 31|8@0+ (1,0) [0|255] "cm"  ADC,CGW
 SG_ APA_05_CRC : 7|8@0+ (1,0) [0|255] ""  CGW,ADC
 SG_ APA_05_MsgCntr : 15|4@0+ (1,0) [0|15] ""  CGW,ADC
 SG_ FrntRiMidRegnDst : 47|8@0+ (1,0) [0|255] "cm"  CGW,ADC
 SG_ FrntSysSts : 10|1@0+ (1,0) [0|1] ""  CGW,ADC

BO_ 646 APA_04: 8 APA
 SG_ ApaPscSlotCrossRiObj2Alpha m3 : 62|7@0+ (2,-128) [-128|126] "deg"  CGW,ADC
 SG_ ApaXSlotYObj1Y m7 : 9|11@0+ (2,-2048) [-2048|2046] "cm"  ADC,CGW
 SG_ ApaXSlotYObj2Y m7 : 41|11@0+ (2,-2048) [-2048|2046] "cm"  ADC,CGW
 SG_ ApaXSlotYObj2Alpha m7 : 62|7@0+ (2,-128) [-128|126] "deg"  ADC,CGW
 SG_ ApaPocSlotParallelLeObj1Y m4 : 9|11@0+ (2,-2048) [-2048|2046] "cm"  ADC,CGW
 SG_ ApaPscSlotParallelRiObj2Alpha m1 : 62|7@0+ (2,-128) [-128|126] "deg"  ADC,CGW
 SG_ ApaPscSlotCrossRiObj1Y m3 : 9|11@0+ (2,-2048) [-2048|2046] "cm"  CGW,ADC
 SG_ ApaPscSlotParallelRiObj2X m1 : 36|11@0+ (2,-2048) [-2048|2046] "cm"  ADC,CGW
 SG_ ApaPscSlotParallelLeObj2X m0 : 36|11@0+ (2,-2048) [-2048|2046] "cm"  ADC,CGW
 SG_ ApaPocSlotParallelRiObj1X m5 : 4|11@0+ (2,-2048) [-2048|2046] "cm"  CGW,ADC
 SG_ ApaPocSlotParallelLeObj2Alpha m4 : 62|7@0+ (2,-128) [-128|126] "deg"  ADC,CGW
 SG_ ApaPocSlotParallelRiObj1Alpha m5 : 30|7@0+ (2,-128) [-128|126] "deg"  ADC,CGW
 SG_ ApaPscSlotCrossLeObj2Alpha m2 : 62|7@0+ (2,-128) [-128|126] "deg"  ADC,CGW
 SG_ ApaPscSlotParallelLeObj1X m0 : 4|11@0+ (2,-2048) [-2048|2046] "cm"  ADC,CGW
 SG_ ApaPscSlotCrossLeObj2Y m2 : 41|11@0+ (2,-2048) [-2048|2046] "cm"  ADC,CGW
 SG_ ApaPscSlotCrossRiObj1Alpha m3 : 30|7@0+ (2,-128) [-128|126] "deg"  ADC,CGW
 SG_ ApaPscSlotCrossRiObj1X m3 : 4|11@0+ (2,-2048) [-2048|2046] "cm"  ADC,CGW
 SG_ ApaPscSlotParallelLeObj1Y m0 : 9|11@0+ (2,-2048) [-2048|2046] "cm"  CGW,ADC
 SG_ ApaPocSlotParallelRiObj1Y m5 : 9|11@0+ (2,-2048) [-2048|2046] "cm"  CGW,ADC
 SG_ ApaPocSlotParallelRiObj2Alpha m5 : 62|7@0+ (2,-128) [-128|126] "deg"  CGW,ADC
 SG_ ApaPscSlotParallelRiObj1X m1 : 4|11@0+ (2,-2048) [-2048|2046] "cm"  ADC,CGW
 SG_ ApaPscSlotParallelRiObj1Alpha m1 : 30|7@0+ (2,-128) [-128|126] "deg"  CGW,ADC
 SG_ ApaPocSlotParallelLeObj2X m4 : 36|11@0+ (2,-2048) [-2048|2046] "cm"  CGW,ADC
 SG_ ApaPscSlotParallelRiObj1Y m1 : 9|11@0+ (2,-2048) [-2048|2046] "cm"  ADC,CGW
 SG_ ApaXSlotYObj1Alpha m7 : 30|7@0+ (2,-128) [-128|126] "deg"  ADC,CGW
 SG_ ApaPscSlotParallelLeObj1Alpha m0 : 30|7@0+ (2,-128) [-128|126] "deg"  ADC,CGW
 SG_ ApaPocSlotParallelRiObj2Y m5 : 41|11@0+ (2,-2048) [-2048|2046] "cm"  CGW,ADC
 SG_ ApaPscSlotCrossLeObj1Alpha m2 : 30|7@0+ (2,-128) [-128|126] "deg"  CGW,ADC
 SG_ ApaXSlotYObj2X m7 : 36|11@0+ (2,-2048) [-2048|2046] "cm"  CGW,ADC
 SG_ ApaPscSlotCrossLeObj2X m2 : 36|11@0+ (2,-2048) [-2048|2046] "cm"  CGW,ADC
 SG_ ApaPocSlotParallelRiObj2X m5 : 36|11@0+ (2,-2048) [-2048|2046] "cm"  CGW,ADC
 SG_ ApaPocSlotParallelLeObj1X m4 : 4|11@0+ (2,-2048) [-2048|2046] "cm"  ADC,CGW
 SG_ ApaPscSlotCrossLeObj1Y m2 : 9|11@0+ (2,-2048) [-2048|2046] "cm"  ADC,CGW
 SG_ ApaPscSlotParallelLeObj2Alpha m0 : 62|7@0+ (2,-128) [-128|126] "deg"  ADC,CGW
 SG_ ApaPscEnvSlotTyp M : 7|3@0+ (1,0) [0|7] ""  CGW,ADC
 SG_ ApaPscSlotParallelLeObj2Y m0 : 41|11@0+ (2,-2048) [-2048|2046] "cm"  ADC,CGW
 SG_ ApaXSlotYObj1X m7 : 4|11@0+ (2,-2048) [-2048|2046] "cm"  CGW,ADC
 SG_ ApaPscSlotParallelRiObj2Y m1 : 41|11@0+ (2,-2048) [-2048|2046] "cm"  CGW,ADC
 SG_ ApaPscSlotCrossRiObj2X m3 : 36|11@0+ (2,-2048) [-2048|2046] "cm"  CGW,ADC
 SG_ ApaPocSlotParallelLeObj1Alpha m4 : 30|7@0+ (2,-128) [-128|126] "deg"  ADC,CGW
 SG_ ApaPscSlotCrossLeObj1X m2 : 4|11@0+ (2,-2048) [-2048|2046] "cm"  ADC,CGW
 SG_ ApaPocSlotParallelLeObj2Y m4 : 41|11@0+ (2,-2048) [-2048|2046] "cm"  CGW,ADC
 SG_ ApaPscSlotCrossRiObj2Y m3 : 41|11@0+ (2,-2048) [-2048|2046] "cm"  ADC,CGW

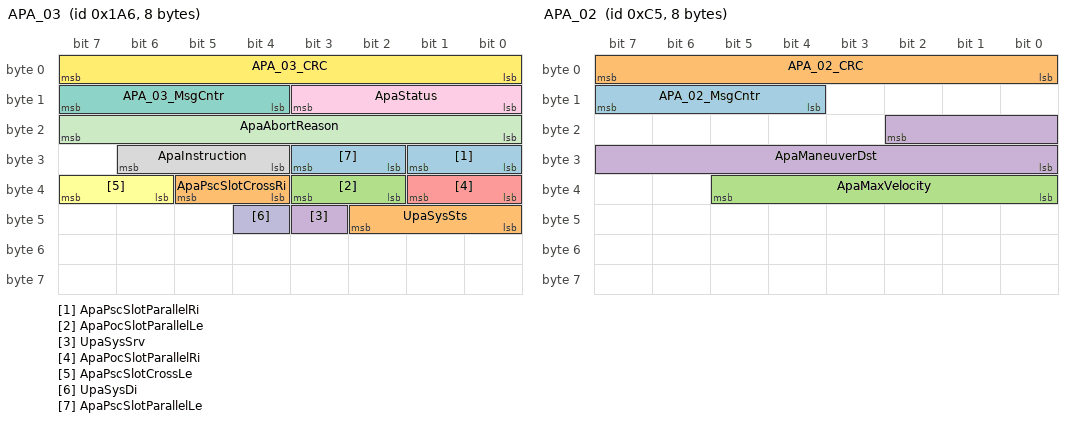
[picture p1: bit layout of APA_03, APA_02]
BO_ 422 APA_03: 8 APA
 SG_ ApaPscSlotParallelRi : 25|2@0+ (1,0) [0|3] ""  ADC,CGW
 SG_ UpaSysSts : 42|3@0+ (1,0) [0|7] ""  CGW,ADC
 SG_ ApaPocSlotParallelLe : 35|2@0+ (1,0) [0|3] ""  ADC,CGW
 SG_ UpaSysSrv : 43|1@0+ (1,0) [0|1] ""  ADC,CGW
 SG_ ApaPocSlotParallelRi : 33|2@0+ (1,0) [0|3] ""  ADC,CGW
 SG_ ApaPscSlotCrossLe : 39|2@0+ (1,0) [0|3] ""  ADC,CGW
 SG_ APA_03_MsgCntr : 15|4@0+ (1,0) [0|15] ""  ADC,CGW
 SG_ ApaInstruction : 30|3@0+ (1,0) [0|7] ""  CGW,ADC
 SG_ ApaStatus : 11|4@0+ (1,0) [0|15] ""  CGW,ADC
 SG_ UpaSysDi : 44|1@0+ (1,0) [0|1] ""  CGW,ADC
 SG_ ApaAbortReason : 23|8@0+ (1,0) [0|255] ""  CGW,ADC
 SG_ APA_03_CRC : 7|8@0+ (1,0) [0|255] ""  ADC,CGW
 SG_ ApaPscSlotParallelLe : 27|2@0+ (1,0) [0|3] ""  ADC,CGW
 SG_ ApaPscSlotCrossRi : 37|2@0+ (1,0) [0|3] ""  ADC,CGW

BO_ 197 APA_02: 8 APA
 SG_ APA_02_MsgCntr : 15|4@0+ (1,0) [0|15] ""  ADC,CGW
 SG_ APA_02_CRC : 7|8@0+ (1,0) [0|255] ""  ADC,CGW
 SG_ ApaMaxVelocity : 37|6@0+ (0.1,0) [0|6.3] "kph"  CGW,ADC
 SG_ ApaManeuverDst : 18|11@0+ (1,0) [0|2047] "cm"  ADC,CGW

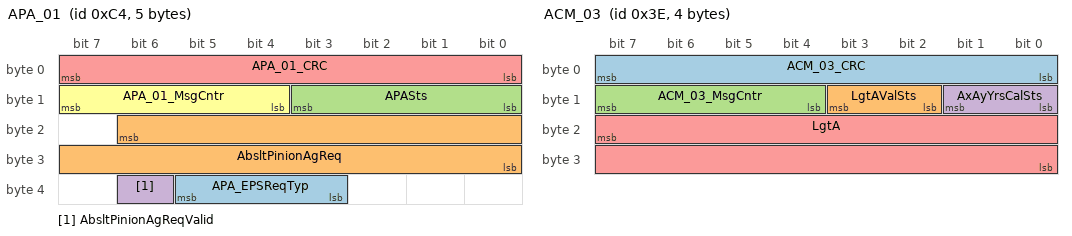
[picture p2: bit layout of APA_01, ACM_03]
BO_ 196 APA_01: 5 APA
 SG_ APA_EPSReqTyp : 37|3@0+ (1,0) [0|7] ""  CGW,ADC
 SG_ AbsltPinionAgReq : 22|15@0+ (0.1,-1638.4) [-1638.4|1638.2] "Deg"  CGW,ADC
 SG_ APASts : 11|4@0+ (1,0) [0|15] ""  CGW,ADC
 SG_ AbsltPinionAgReqValid : 38|1@0+ (1,0) [0|1] ""  ADC,CGW
 SG_ APA_01_CRC : 7|8@0+ (1,0) [0|255] ""  CGW,ADC
 SG_ APA_01_MsgCntr : 15|4@0+ (1,0) [0|15] ""  ADC,CGW

BO_ 556 ADC_VCU_01: 8 ADC
 SG_ ADCVoltWakeupReq : 9|2@0+ (1,0) [0|3] ""  CGW

BO_ 62 ACM_03: 4 CGW
 SG_ ACM_03_CRC : 7|8@0+ (1,0) [0|255] ""  RAD_RR,RAD_FR,RAD_FL,RAD_RL,APA,RAD_FC
 SG_ LgtAValSts : 11|2@0+ (1,0) [0|3] ""  RAD_RR,RAD_FC,RAD_FL,APA,RAD_FR,RAD_RL
 SG_ ACM_03_MsgCntr : 15|4@0+ (1,0) [0|15] ""  RAD_RL,RAD_FL,RAD_FC,RAD_RR,RAD_FR,APA
 SG_ AxAyYrsCalSts : 9|2@0+ (1,0) [0|3] "" Vector__XXX
 SG_ LgtA : 23|16@0+ (0.001,-2) [-2|2] "g"  RAD_RL,APA,RAD_FR,RAD_FL,RAD_RR,RAD_FC

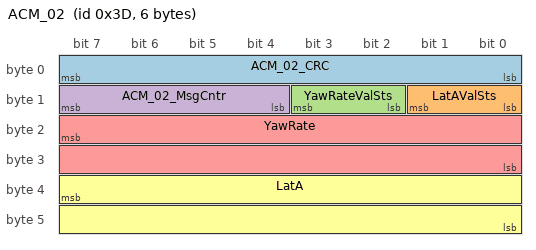
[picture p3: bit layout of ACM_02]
BO_ 61 ACM_02: 6 CGW
 SG_ ACM_02_CRC : 7|8@0+ (1,0) [0|255] ""  APA,RAD_FC,RAD_FL,RAD_FR,RAD_RL,RAD_RR
 SG_ LatAValSts : 9|2@0+ (1,0) [0|3] ""  RAD_FC,RAD_FR,RAD_RR,RAD_FL,RAD_RL,APA
 SG_ YawRateValSts : 11|2@0+ (1,0) [0|3] ""  RAD_FC,APA,RAD_FR,RAD_FL,RAD_RL,RAD_RR
 SG_ ACM_02_MsgCntr : 15|4@0+ (1,0) [0|15] ""  APA,RAD_FC,RAD_RR,RAD_RL,RAD_FR,RAD_FL
 SG_ YawRate : 23|16@0+ (0.01,-180) [-180|180] "Deg/sec"  RAD_FL,RAD_RR,RAD_FC,RAD_FR,APA,RAD_RL
 SG_ LatA : 39|16@0+ (0.001,-2) [-2|2] "g"  RAD_FC,RAD_FR,APA,RAD_FL,RAD_RR,RAD_RL

CM_ SG_ 425 sens05De3Distance_APA "Distance of the Direct Echo";
CM_ SG_ 425 sens08De2Quality_APA "Quality of the Direct Echo";
CM_ SG_ 425 deMsgChecksum_APA "SAE J1850 8-bit Checksum";
CM_ SG_ 425 sens03De2Quality_APA "Quality of the Direct Echo";
CM_ SG_ 425 sens12De2Distance_APA "Distance of the Direct Echo";
CM_ SG_ 425 sens01De3Distance_APA "Distance of the Direct Echo";
CM_ SG_ 425 sens02De1Quality_APA "Quality of the Direct Echo";
CM_ SG_ 425 sens07De3Quality_APA "Quality of the Direct Echo";
CM_ SG_ 425 sens05De1Quality_APA "Quality of the Direct Echo";
CM_ SG_ 425 sens10De2Distance_APA "Distance of the Direct Echo";
CM_ SG_ 425 sens08De1Quality_APA "Quality of the Direct Echo";
CM_ SG_ 425 sens06De1Quality_APA "Quality of the Direct Echo";
CM_ SG_ 425 sens10De3Quality_APA "Quality of the Direct Echo";
CM_ SG_ 425 sens12De1Distance_APA "Distance of the Direct Echo";
CM_ SG_ 425 sens11De1Quality_APA "Quality of the Direct Echo";
CM_ SG_ 425 sens11De2Distance_APA "Distance of the Direct Echo";
CM_ SG_ 425 sens03De2Distance_APA "Distance of the Direct Echo";
CM_ SG_ 425 sens12De3Distance_APA "Distance of the Direct Echo";
CM_ SG_ 425 sens09De1Distance_APA "Distance of the Direct Echo";
CM_ SG_ 425 sens04De1Quality_APA "Quality of the Direct Echo";
CM_ SG_ 425 sens01De2Distance_APA "Distance of the Direct Echo";
CM_ SG_ 425 sens07De3Distance_APA "Distance of the Direct Echo";
CM_ SG_ 425 sens07De2Quality_APA "Quality of the Direct Echo";
CM_ SG_ 425 sens04De1Distance_APA "Distance of the Direct Echo";
CM_ SG_ 425 sens04De3Distance_APA "Distance of the Direct Echo";
CM_ SG_ 425 sens04De2Distance_APA "Distance of the Direct Echo";
CM_ SG_ 425 sens08De3Quality_APA "Quality of the Direct Echo";
CM_ SG_ 425 sens07De1Quality_APA "Quality of the Direct Echo";
CM_ SG_ 425 sens10De2Quality_APA "Quality of the Direct Echo";
CM_ SG_ 425 sens01De2Quality_APA "Quality of the Direct Echo";
CM_ SG_ 425 sens09De2Quality_APA "Quality of the Direct Echo";
CM_ SG_ 425 sens06De3Distance_APA "Distance of the Direct Echo";
CM_ SG_ 425 sens09De1Quality_APA "Quality of the Direct Echo";
CM_ SG_ 425 sens06De1Distance_APA "Distance of the Direct Echo";
CM_ SG_ 425 deMsgCounter_APA "4-bit Counter";
CM_ SG_ 425 sens07De2Distance_APA "Distance of the Direct Echo";
CM_ SG_ 425 deMsgSensorIdx_APA "Direct Echo Attributes for Sensor # ( # = 1 + Index)";
CM_ SG_ 425 sens12De2Quality_APA "Quality of the Direct Echo";
CM_ SG_ 425 sens10De1Quality_APA "Quality of the Direct Echo";
CM_ SG_ 425 sens04De3Quality_APA "Quality of the Direct Echo";
CM_ SG_ 425 sens11De3Quality_APA "Quality of the Direct Echo";
CM_ SG_ 425 sens03De1Quality_APA "Quality of the Direct Echo";
CM_ SG_ 425 sens12De1Quality_APA "Quality of the Direct Echo";
CM_ SG_ 425 sens09De3Quality_APA "Quality of the Direct Echo";
CM_ SG_ 425 sens05De2Quality_APA "Quality of the Direct Echo";
CM_ SG_ 425 sens06De3Quality_APA "Quality of the Direct Echo";
CM_ SG_ 425 sens01De3Quality_APA "Quality of the Direct Echo";
CM_ SG_ 425 sens09De2Distance_APA "Distance of the Direct Echo";
CM_ SG_ 425 sens11De3Distance_APA "Distance of the Direct Echo";
CM_ SG_ 425 sens02De2Distance_APA "Distance of the Direct Echo";
CM_ SG_ 425 sens02De2Quality_APA "Quality of the Direct Echo";
CM_ SG_ 425 sens11De1Distance_APA "Distance of the Direct Echo";
CM_ SG_ 425 sens02De1Distance_APA "Distance of the Direct Echo";
CM_ SG_ 425 sens05De1Distance_APA "Distance of the Direct Echo";
CM_ SG_ 425 sens03De3Quality_APA "Quality of the Direct Echo";
CM_ SG_ 425 sens08De2Distance_APA "Distance of the Direct Echo";
CM_ SG_ 425 sens05De2Distance_APA "Distance of the Direct Echo";
CM_ SG_ 425 sens06De2Distance_APA "Distance of the Direct Echo";
CM_ SG_ 425 sens04De2Quality_APA "Quality of the Direct Echo";
CM_ SG_ 425 sens08De1Distance_APA "Distance of the Direct Echo";
CM_ SG_ 425 sens10De3Distance_APA "Distance of the Direct Echo";
CM_ SG_ 425 sens05De3Quality_APA "Quality of the Direct Echo";
CM_ SG_ 425 sens07De1Distance_APA "Distance of the Direct Echo";
CM_ SG_ 425 sens10De1Distance_APA "Distance of the Direct Echo";
CM_ SG_ 425 sens02De3Quality_APA "Quality of the Direct Echo";
CM_ SG_ 425 sens12De3Quality_APA "Quality of the Direct Echo";
CM_ SG_ 425 sens06De2Quality_APA "Quality of the Direct Echo";
CM_ SG_ 425 sens03De3Distance_APA "Distance of the Direct Echo";
CM_ SG_ 425 sens09De3Distance_APA "Distance of the Direct Echo";
CM_ SG_ 425 sens03De1Distance_APA "Distance of the Direct Echo";
CM_ SG_ 425 sens11De2Quality_APA "Quality of the Direct Echo";
CM_ SG_ 425 sens01De1Quality_APA "Quality of the Direct Echo";
CM_ SG_ 425 sens08De3Distance_APA "Distance of the Direct Echo";
CM_ SG_ 425 sens02De3Distance_APA "Distance of the Direct Echo";
CM_ SG_ 425 sens01De1Distance_APA "Distance of the Direct Echo";
CM_ SG_ 424 Sens06CeRgt3Quality "Quality of the Cross Echo";
CM_ SG_ 424 Sens08CeRgt1Distance "Distance of the Cross Echo";
CM_ SG_ 424 Sens09CeRgt3Distance "Distance of the Cross Echo";
CM_ SG_ 424 Sens06CeRgt1Distance "Distance of the Cross Echo";
CM_ SG_ 424 Sens02CeRgt3Quality "Quality of the Cross Echo";
CM_ SG_ 424 Sens04CeRgt2Quality "Quality of the Cross Echo";
CM_ SG_ 424 Sens05CeRgt2Quality "Quality of the Cross Echo";
CM_ SG_ 424 Sens04CeRgt3Quality "Quality of the Cross Echo";
CM_ SG_ 424 CeRgtMsgSensorIdx "Cross Echo Attributes for Sensor # ( # = 1 + Index)";
CM_ SG_ 424 Sens06CeRgt3Distance "Distance of the Cross Echo";
CM_ SG_ 424 Sens10CeRgt3Distance "Distance of the Cross Echo";
CM_ SG_ 424 Sens11CeRgt1Distance "Distance of the Cross Echo";
CM_ SG_ 424 Sens05CeRgt3Quality "Quality of the Cross Echo";
CM_ SG_ 424 Sens06CeRgt1Quality "Quality of the Cross Echo";
CM_ SG_ 424 Sens11CeRgt1Quality "Quality of the Cross Echo";
CM_ SG_ 424 Sens01CeRgt1Quality "Quality of the Cross Echo";
CM_ SG_ 424 Sens04CeRgt2Distance "Distance of the Cross Echo";
CM_ SG_ 424 Sens04CeRgt1Distance "Distance of the Cross Echo";
CM_ SG_ 424 Sens11CeRgt2Distance "Distance of the Cross Echo";
CM_ SG_ 424 Sens10CeRgt1Distance "Distance of the Cross Echo";
CM_ SG_ 424 Sens12CeRgt3Quality "Quality of the Cross Echo";
CM_ SG_ 424 Sens12CeRgt3Distance "Distance of the Cross Echo";
CM_ SG_ 424 Sens04CeRgt1Quality "Quality of the Cross Echo";
CM_ SG_ 424 Sens08CeRgt2Distance "Distance of the Cross Echo";
CM_ SG_ 424 Sens03CeRgt1Quality "Quality of the Cross Echo";
CM_ SG_ 424 Sens12CeRgt1Distance "Distance of the Cross Echo";
CM_ SG_ 424 Sens02CeRgt2Distance "Distance of the Cross Echo";
CM_ SG_ 424 Sens08CeRgt1Quality "Quality of the Cross Echo";
CM_ SG_ 424 Sens08CeRgt3Distance "Distance of the Cross Echo";
CM_ SG_ 424 Sens08CeRgt2Quality "Quality of the Cross Echo";
CM_ SG_ 424 Sens01CeRgt3Distance "Distance of the Cross Echo";
CM_ SG_ 424 Sens09CeRgt1Distance "Distance of the Cross Echo";
CM_ SG_ 424 Sens07CeRgt2Quality "Quality of the Cross Echo";
CM_ SG_ 424 Sens08CeRgt3Quality "Quality of the Cross Echo";
CM_ SG_ 424 Sens03CeRgt3Distance "Distance of the Cross Echo";
CM_ SG_ 424 Sens05CeRgt1Quality "Quality of the Cross Echo";
CM_ SG_ 424 Sens07CeRgt2Distance "Distance of the Cross Echo";
CM_ SG_ 424 Sens02CeRgt3Distance "Distance of the Cross Echo";
CM_ SG_ 424 Sens02CeRgt1Quality "Quality of the Cross Echo";
CM_ SG_ 424 Sens07CeRgt3Distance "Distance of the Cross Echo";
CM_ SG_ 424 Sens03CeRgt2Quality "Quality of the Cross Echo";
CM_ SG_ 424 Sens09CeRgt2Distance "Distance of the Cross Echo";
CM_ SG_ 424 CeRgtMsgCounter "4-bit Counter";
CM_ SG_ 424 Sens01CeRgt2Quality "Quality of the Cross Echo";
CM_ SG_ 424 CeRgtMsgChecksum "SAE J1850 8-bit Checksum";
CM_ SG_ 424 Sens01CeRgt1Distance "Distance of the Cross Echo";
CM_ SG_ 424 Sens05CeRgt3Distance "Distance of the Cross Echo";
CM_ SG_ 424 Sens11CeRgt2Quality "Quality of the Cross Echo";
CM_ SG_ 424 Sens06CeRgt2Quality "Quality of the Cross Echo";
CM_ SG_ 424 Sens10CeRgt3Quality "Quality of the Cross Echo";
CM_ SG_ 424 Sens09CeRgt1Quality "Quality of the Cross Echo";
CM_ SG_ 424 Sens12CeRgt2Distance "Distance of the Cross Echo";
CM_ SG_ 424 Sens11CeRgt3Quality "Quality of the Cross Echo";
CM_ SG_ 424 Sens05CeRgt1Distance "Distance of the Cross Echo";
CM_ SG_ 424 Sens06CeRgt2Distance "Distance of the Cross Echo";
CM_ SG_ 424 Sens01CeRgt2Distance "Distance of the Cross Echo";
CM_ SG_ 424 Sens09CeRgt3Quality "Quality of the Cross Echo";
CM_ SG_ 424 Sens05CeRgt2Distance "Distance of the Cross Echo";
CM_ SG_ 424 Sens07CeRgt1Distance "Distance of the Cross Echo";
CM_ SG_ 424 Sens01CeRgt3Quality "Quality of the Cross Echo";
CM_ SG_ 424 Sens03CeRgt1Distance "Distance of the Cross Echo";
CM_ SG_ 424 Sens02CeRgt2Quality "Quality of the Cross Echo";
CM_ SG_ 424 Sens12CeRgt2Quality "Quality of the Cross Echo";
CM_ SG_ 424 Sens10CeRgt2Quality "Quality of the Cross Echo";
CM_ SG_ 424 Sens10CeRgt2Distance "Distance of the Cross Echo";
CM_ SG_ 424 Sens12CeRgt1Quality "Quality of the Cross Echo";
CM_ SG_ 424 Sens11CeRgt3Distance "Distance of the Cross Echo";
CM_ SG_ 424 Sens02CeRgt1Distance "Distance of the Cross Echo";
CM_ SG_ 424 Sens03CeRgt3Quality "Quality of the Cross Echo";
CM_ SG_ 424 Sens10CeRgt1Quality "Quality of the Cross Echo";
CM_ SG_ 424 Sens09CeRgt2Quality "Quality of the Cross Echo";
CM_ SG_ 424 Sens07CeRgt1Quality "Quality of the Cross Echo";
CM_ SG_ 424 Sens07CeRgt3Quality "Quality of the Cross Echo";
CM_ SG_ 424 Sens04CeRgt3Distance "Distance of the Cross Echo";
CM_ SG_ 424 Sens03CeRgt2Distance "Distance of the Cross Echo";
CM_ SG_ 423 Sens03CeLft3Quality "Quality of the Cross Echo";
CM_ SG_ 423 Sens02CeLft1Distance "Distance of the Cross Echo";
CM_ SG_ 423 Sens01CeLft1Distance "Distance of the Cross Echo";
CM_ SG_ 423 Sens10CeLft1Quality "Quality of the Cross Echo";
CM_ SG_ 423 Sens04CeLft2Distance "Distance of the Cross Echo";
CM_ SG_ 423 Sens05CeLft3Quality "Quality of the Cross Echo";
CM_ SG_ 423 Sens03CeLft2Quality "Quality of the Cross Echo";
CM_ SG_ 423 Sens03CeLft1Quality "Quality of the Cross Echo";
CM_ SG_ 423 Sens12CeLft2Quality "Quality of the Cross Echo";
CM_ SG_ 423 Sens01CeLft2Quality "Quality of the Cross Echo";
CM_ SG_ 423 Sens11CeLft2Quality "Quality of the Cross Echo";
CM_ SG_ 423 Sens05CeLft1Distance "Distance of the Cross Echo";
CM_ SG_ 423 Sens06CeLft2Quality "Quality of the Cross Echo";
CM_ SG_ 423 Sens08CeLft1Distance "Distance of the Cross Echo";
CM_ SG_ 423 Sens03CeLft2Distance "Distance of the Cross Echo";
CM_ SG_ 423 Sens10CeLft1Distance "Distance of the Cross Echo";
CM_ SG_ 423 Sens07CeLft3Distance "Distance of the Cross Echo";
CM_ SG_ 423 Sens10CeLft2Distance "Distance of the Cross Echo";
CM_ SG_ 423 Sens11CeLft3Distance "Distance of the Cross Echo";
CM_ SG_ 423 Sens09CeLft1Distance "Distance of the Cross Echo";
CM_ SG_ 423 Sens02CeLft3Quality "Quality of the Cross Echo";
CM_ SG_ 423 Sens06CeLft1Distance "Distance of the Cross Echo";
CM_ SG_ 423 Sens04CeLft3Distance "Distance of the Cross Echo";
CM_ SG_ 423 Sens08CeLft3Quality "Quality of the Cross Echo";
CM_ SG_ 423 CeLftMsgChecksum "SAE J1850 8-bit Checksum";
CM_ SG_ 423 Sens08CeLft2Quality "Quality of the Cross Echo";
CM_ SG_ 423 Sens04CeLft3Quality "Quality of the Cross Echo";
CM_ SG_ 423 Sens07CeLft3Quality "Quality of the Cross Echo";
CM_ SG_ 423 Sens09CeLft2Distance "Distance of the Cross Echo";
CM_ SG_ 423 Sens11CeLft3Quality "Quality of the Cross Echo";
CM_ SG_ 423 Sens10CeLft3Distance "Distance of the Cross Echo";
CM_ SG_ 423 CeLftMsgCounter "4-bit Counter";
CM_ SG_ 423 Sens08CeLft2Distance "Distance of the Cross Echo";
CM_ SG_ 423 Sens06CeLft3Quality "Quality of the Cross Echo";
CM_ SG_ 423 Sens09CeLft3Distance "Distance of the Cross Echo";
CM_ SG_ 423 Sens01CeLft1Quality "Quality of the Cross Echo";
CM_ SG_ 423 Sens09CeLft2Quality "Quality of the Cross Echo";
CM_ SG_ 423 Sens10CeLft3Quality "Quality of the Cross Echo";
CM_ SG_ 423 Sens05CeLft2Quality "Quality of the Cross Echo";
CM_ SG_ 423 Sens01CeLft3Quality "Quality of the Cross Echo";
CM_ SG_ 423 Sens06CeLft3Distance "Distance of the Cross Echo";
CM_ SG_ 423 Sens07CeLft2Distance "Distance of the Cross Echo";
CM_ SG_ 423 Sens02CeLft2Quality "Quality of the Cross Echo";
CM_ SG_ 423 Sens07CeLft1Distance "Distance of the Cross Echo";
CM_ SG_ 423 Sens01CeLft2Distance "Distance of the Cross Echo";
CM_ SG_ 423 Sens07CeLft1Quality "Quality of the Cross Echo";
CM_ SG_ 423 Sens12CeLft2Distance "Distance of the Cross Echo";
CM_ SG_ 423 Sens11CeLft2Distance "Distance of the Cross Echo";
CM_ SG_ 423 Sens09CeLft3Quality "Quality of the Cross Echo";
CM_ SG_ 423 Sens05CeLft2Distance "Distance of the Cross Echo";
CM_ SG_ 423 Sens07CeLft2Quality "Quality of the Cross Echo";
CM_ SG_ 423 Sens03CeLft1Distance "Distance of the Cross Echo";
CM_ SG_ 423 Sens03CeLft3Distance "Distance of the Cross Echo";
CM_ SG_ 423 Sens01CeLft3Distance "Distance of the Cross Echo";
CM_ SG_ 423 Sens04CeLft2Quality "Quality of the Cross Echo";
CM_ SG_ 423 Sens12CeLft1Quality "Quality of the Cross Echo";
CM_ SG_ 423 Sens04CeLft1Distance "Distance of the Cross Echo";
CM_ SG_ 423 Sens02CeLft1Quality "Quality of the Cross Echo";
CM_ SG_ 423 Sens12CeLft3Distance "Distance of the Cross Echo";
CM_ SG_ 423 Sens09CeLft1Quality "Quality of the Cross Echo";
CM_ SG_ 423 Sens06CeLft2Distance "Distance of the Cross Echo";
CM_ SG_ 423 Sens11CeLft1Quality "Quality of the Cross Echo";
CM_ SG_ 423 Sens10CeLft2Quality "Quality of the Cross Echo";
CM_ SG_ 423 Sens12CeLft1Distance "Distance of the Cross Echo";
CM_ SG_ 423 Sens11CeLft1Distance "Distance of the Cross Echo";
CM_ SG_ 423 Sens05CeLft1Quality "Quality of the Cross Echo";
CM_ SG_ 423 CeLftMsgSensorIdx "Cross Echo Attributes for Sensor # ( # = 1 + Index)";
CM_ SG_ 423 Sens06CeLft1Quality "Quality of the Cross Echo";
CM_ SG_ 423 Sens02CeLft2Distance "Distance of the Cross Echo";
CM_ SG_ 423 Sens12CeLft3Quality "Quality of the Cross Echo";
CM_ SG_ 423 Sens08CeLft1Quality "Quality of the Cross Echo";
CM_ SG_ 423 Sens04CeLft1Quality "Quality of the Cross Echo";
CM_ SG_ 423 Sens05CeLft3Distance "Distance of the Cross Echo";
CM_ SG_ 423 Sens02CeLft3Distance "Distance of the Cross Echo";
CM_ SG_ 423 Sens08CeLft3Distance "Distance of the Cross Echo";
CM_ SG_ 357 MapObj19P1Y "Point 1 y-axis of MAP Object";
CM_ SG_ 357 MapObj09Problty "Probability that MAP Object is a 'Real' object";
CM_ SG_ 357 MapObj09P1Y "Point 1 y-axis of MAP Object";
CM_ SG_ 357 MapObj09P1X "Point 1 x-axis of MAP Object";
CM_ SG_ 357 MapObj19Problty "Probability that MAP Object is a 'Real' object";
CM_ SG_ 357 MapObj09P2X "Point 2 x-axis of MAP Object";
CM_ SG_ 357 APA_ADC_10_MsgCntr "2-bit Counter";
CM_ SG_ 357 MapObj19P2X "Point 2 x-axis of MAP Object";
CM_ SG_ 357 MapObj19Typ "Type Classification of MAP Object";
CM_ SG_ 357 MapObj09HeiProblty "Probability that MAP Object is a 'High' object";
CM_ SG_ 357 MapObj09Hei "Height Classification of MAP Object";
CM_ SG_ 357 MapObj09P2Y "Point 2 y-axis of MAP Object";
CM_ SG_ 357 MapObj09Typ "Type Classification of MAP Object";
CM_ SG_ 357 MapObj19P2Y "Point 2 y-axis of MAP Object";
CM_ SG_ 357 MapObjX9Offs "Attributes for Map Object# (# = 9 + Offset * 10)";
CM_ SG_ 357 APA_ADC_10_CRC "SAE J1850 8-bit Checksum";
CM_ SG_ 357 MapObj19HeiProblty "Probability that MAP Object is a 'High' object";
CM_ SG_ 357 MapObj19Hei "Height Classification of MAP Object";
CM_ SG_ 357 MapObj19P1X "Point 1 x-axis of MAP Object";
CM_ SG_ 356 MapObj08P1X "Point 1 x-axis of MAP Object";
CM_ SG_ 356 MapObj08P2Y "Point 2 y-axis of MAP Object";
CM_ SG_ 356 APA_ADC_09_MsgCntr "2-bit Counter";
CM_ SG_ 356 MapObj08Hei "Height Classification of MAP Object";
CM_ SG_ 356 MapObjX8Offs "Attributes for Map Object# (# = 8 + Offset * 10)";
CM_ SG_ 356 MapObj08HeiProblty "Probability that MAP Object is a 'High' object";
CM_ SG_ 356 MapObj18Hei "Height Classification of MAP Object";
CM_ SG_ 356 MapObj18P2X "Point 2 x-axis of MAP Object";
CM_ SG_ 356 MapObj08P2X "Point 2 x-axis of MAP Object";
CM_ SG_ 356 MapObj08P1Y "Point 1 y-axis of MAP Object";
CM_ SG_ 356 MapObj18HeiProblty "Probability that MAP Object is a 'High' object";
CM_ SG_ 356 MapObj08Typ "Type Classification of MAP Object";
CM_ SG_ 356 MapObj08Problty "Probability that MAP Object is a 'Real' object";
CM_ SG_ 356 MapObj18Typ "Type Classification of MAP Object";
CM_ SG_ 356 MapObj18P1X "Point 1 x-axis of MAP Object";
CM_ SG_ 356 APA_ADC_09_CRC "SAE J1850 8-bit Checksum";
CM_ SG_ 356 MapObj18Problty "Probability that MAP Object is a 'Real' object";
CM_ SG_ 356 MapObj18P1Y "Point 1 y-axis of MAP Object";
CM_ SG_ 356 MapObj18P2Y "Point 2 y-axis of MAP Object";
CM_ SG_ 355 MapObj17HeiProblty "Probability that MAP Object is a 'High' object";
CM_ SG_ 355 MapObj17Problty "Probability that MAP Object is a 'Real' object";
CM_ SG_ 355 MapObj07P2X "Point 2 x-axis of MAP Object";
CM_ SG_ 355 APA_ADC_08_CRC "SAE J1850 8-bit Checksum";
CM_ SG_ 355 MapObj07P1X "Point 1 x-axis of MAP Object";
CM_ SG_ 355 MapObj07P1Y "Point 1 y-axis of MAP Object";
CM_ SG_ 355 MapObj07Problty "Probability that MAP Object is a 'Real' object";
CM_ SG_ 355 APA_ADC_08_MsgCntr "2-bit Counter";
CM_ SG_ 355 MapObj07Typ "Type Classification of MAP Object";
CM_ SG_ 355 MapObj17Typ "Type Classification of MAP Object";
CM_ SG_ 355 MapObj07HeiProblty "Probability that MAP Object is a 'High' object";
CM_ SG_ 355 MapObj07Hei "Height Classification of MAP Object";
CM_ SG_ 355 MapObj17P2X "Point 2 x-axis of MAP Object";
CM_ SG_ 355 MapObj17P2Y "Point 2 y-axis of MAP Object";
CM_ SG_ 355 MapObj07P2Y "Point 2 y-axis of MAP Object";
CM_ SG_ 355 MapObjX7Offs "Attributes for Map Object# (# = 7 + Offset * 10)";
CM_ SG_ 355 MapObj17P1Y "Point 1 y-axis of MAP Object";
CM_ SG_ 355 MapObj17P1X "Point 1 x-axis of MAP Object";
CM_ SG_ 355 MapObj17Hei "Height Classification of MAP Object";
CM_ SG_ 354 APA_ADC_07_MsgCntr "2-bit Counter";
CM_ SG_ 354 MapObj16P2X "Point 2 x-axis of MAP Object";
CM_ SG_ 354 MapObj06Typ "Type Classification of MAP Object";
CM_ SG_ 354 MapObj06Hei "Height Classification of MAP Object";
CM_ SG_ 354 MapObj16P2Y "Point 2 y-axis of MAP Object";
CM_ SG_ 354 MapObj16Problty "Probability that MAP Object is a 'Real' object";
CM_ SG_ 354 MapObj06P1Y "Point 1 y-axis of MAP Object";
CM_ SG_ 354 MapObj16P1Y "Point 1 y-axis of MAP Object";
CM_ SG_ 354 MapObj06HeiProblty "Probability that MAP Object is a 'High' object";
CM_ SG_ 354 MapObj16Hei "Height Classification of MAP Object";
CM_ SG_ 354 MapObj06Problty "Probability that MAP Object is a 'Real' object";
CM_ SG_ 354 MapObj06P1X "Point 1 x-axis of MAP Object";
CM_ SG_ 354 MapObj16P1X "Point 1 x-axis of MAP Object";
CM_ SG_ 354 MapObj06P2X "Point 2 x-axis of MAP Object";
CM_ SG_ 354 MapObj16Typ "Type Classification of MAP Object";
CM_ SG_ 354 MapObj16HeiProblty "Probability that MAP Object is a 'High' object";
CM_ SG_ 354 MapObjX6Offs "Attributes for Map Object# (# = 6 + Offset * 10)";
CM_ SG_ 354 APA_ADC_07_CRC "SAE J1850 8-bit Checksum";
CM_ SG_ 354 MapObj06P2Y "Point 2 y-axis of MAP Object";
CM_ SG_ 353 MapObjX5Offs "Attributes for Map Object# (# = 5 + Offset * 10)";
CM_ SG_ 353 MapObj15Hei "Height Classification of MAP Object";
CM_ SG_ 353 MapObj15Problty "Probability that MAP Object is a 'Real' object";
CM_ SG_ 353 MapObj15Typ "Type Classification of MAP Object";
CM_ SG_ 353 MapObj15HeiProblty "Probability that MAP Object is a 'High' object";
CM_ SG_ 353 MapObj15P1Y "Point 1 y-axis of MAP Object";
CM_ SG_ 353 MapObj05P1Y "Point 1 y-axis of MAP Object";
CM_ SG_ 353 MapObj05P1X "Point 1 x-axis of MAP Object";
CM_ SG_ 353 MapObj05Typ "Type Classification of MAP Object";
CM_ SG_ 353 APA_ADC_06_MsgCntr "2-bit Counter";
CM_ SG_ 353 MapObj05Problty "Probability that MAP Object is a 'Real' object";
CM_ SG_ 353 MapObj05Hei "Height Classification of MAP Object";
CM_ SG_ 353 MapObj15P2Y "Point 2 y-axis of MAP Object";
CM_ SG_ 353 APA_ADC_06_CRC "SAE J1850 8-bit Checksum";
CM_ SG_ 353 MapObj15P2X "Point 2 x-axis of MAP Object";
CM_ SG_ 353 MapObj05P2X "Point 2 x-axis of MAP Object";
CM_ SG_ 353 MapObj15P1X "Point 1 x-axis of MAP Object";
CM_ SG_ 353 MapObj05P2Y "Point 2 y-axis of MAP Object";
CM_ SG_ 353 MapObj05HeiProblty "Probability that MAP Object is a 'High' object";
CM_ SG_ 352 MapObj14Problty "Probability that MAP Object is a 'Real' object";
CM_ SG_ 352 MapObj04Problty "Probability that MAP Object is a 'Real' object";
CM_ SG_ 352 MapObj04P1Y "Point 1 y-axis of MAP Object";
CM_ SG_ 352 MapObj04Typ "Type Classification of MAP Object";
CM_ SG_ 352 MapObj14P1Y "Point 1 y-axis of MAP Object";
CM_ SG_ 352 MapObj14Typ "Type Classification of MAP Object";
CM_ SG_ 352 MapObj04Hei "Height Classification of MAP Object";
CM_ SG_ 352 MapObj14P2Y "Point 2 y-axis of MAP Object";
CM_ SG_ 352 MapObj14P1X "Point 1 x-axis of MAP Object";
CM_ SG_ 352 MapObj04P1X "Point 1 x-axis of MAP Object";
CM_ SG_ 352 MapObj14P2X "Point 2 x-axis of MAP Object";
CM_ SG_ 352 APA_ADC_05_CRC "SAE J1850 8-bit Checksum";
CM_ SG_ 352 MapObjX4Offs "Attributes for Map Object# (# = 4 + Offset * 10)";
CM_ SG_ 352 MapObj14Hei "Height Classification of MAP Object";
CM_ SG_ 352 APA_ADC_05_MsgCntr "2-bit Counter";
CM_ SG_ 352 MapObj04P2Y "Point 2 y-axis of MAP Object";
CM_ SG_ 352 MapObj04P2X "Point 2 x-axis of MAP Object";
CM_ SG_ 352 MapObj04HeiProblty "Probability that MAP Object is a 'High' object";
CM_ SG_ 352 MapObj14HeiProblty "Probability that MAP Object is a 'High' object";
CM_ SG_ 351 MapObj13P1X "Point 1 x-axis of MAP Object";
CM_ SG_ 351 MapObjX3Offs "Attributes for Map Object# (# = 3 + Offset * 10)";
CM_ SG_ 351 APA_ADC_04_CRC "SAE J1850 8-bit Checksum";
CM_ SG_ 351 MapObj13P1Y "Point 1 y-axis of MAP Object";
CM_ SG_ 351 MapObj13HeiProblty "Probability that MAP Object is a 'High' object";
CM_ SG_ 351 MapObj03P2X "Point 2 x-axis of MAP Object";
CM_ SG_ 351 MapObj03P2Y "Point 2 y-axis of MAP Object";
CM_ SG_ 351 APA_ADC_04_MsgCntr "2-bit Counter";
CM_ SG_ 351 MapObj13Problty "Probability that MAP Object is a 'Real' object";
CM_ SG_ 351 MapObj03Problty "Probability that MAP Object is a 'Real' object";
CM_ SG_ 351 MapObj13Hei "Height Classification of MAP Object";
CM_ SG_ 351 MapObj03P1Y "Point 1 y-axis of MAP Object";
CM_ SG_ 351 MapObj13Typ "Type Classification of MAP Object";
CM_ SG_ 351 MapObj03P1X "Point 1 x-axis of MAP Object";
CM_ SG_ 351 MapObj13P2Y "Point 2 y-axis of MAP Object";
CM_ SG_ 351 MapObj03Hei "Height Classification of MAP Object";
CM_ SG_ 351 MapObj13P2X "Point 2 x-axis of MAP Object";
CM_ SG_ 351 MapObj03Typ "Type Classification of MAP Object";
CM_ SG_ 351 MapObj03HeiProblty "Probability that MAP Object is a 'High' object";
CM_ SG_ 350 MapObj02P2Y "Point 2 y-axis of MAP Object";
CM_ SG_ 350 MapObj02Typ "Type Classification of MAP Object";
CM_ SG_ 350 MapObj02P2X "Point 2 x-axis of MAP Object";
CM_ SG_ 350 MapObj12P2Y "Point 2 y-axis of MAP Object";
CM_ SG_ 350 MapObj12P2X "Point 2 x-axis of MAP Object";
CM_ SG_ 350 MapObj12Hei "Height Classification of MAP Object";
CM_ SG_ 350 MapObj02HeiProblty "Probability that MAP Object is a 'High' object";
CM_ SG_ 350 MapObj12P1Y "Point 1 y-axis of MAP Object";
CM_ SG_ 350 MapObj12Problty "Probability that MAP Object is a 'Real' object";
CM_ SG_ 350 MapObj02Problty "Probability that MAP Object is a 'Real' object";
CM_ SG_ 350 MapObj12HeiProblty "Probability that MAP Object is a 'High' object";
CM_ SG_ 350 APA_ADC_03_CRC "SAE J1850 8-bit Checksum";
CM_ SG_ 350 MapObj02P1Y "Point 1 y-axis of MAP Object";
CM_ SG_ 350 MapObj02Hei "Height Classification of MAP Object";
CM_ SG_ 350 MapObj02P1X "Point 1 x-axis of MAP Object";
CM_ SG_ 350 APA_ADC_03_MsgCntr "2-bit Counter";
CM_ SG_ 350 MapObj12P1X "Point 1 x-axis of MAP Object";
CM_ SG_ 350 MapObjX2Offs "Attributes for Map Object# (# = 2 + Offset * 10)";
CM_ SG_ 350 MapObj12Typ "Type Classification of MAP Object";
CM_ SG_ 349 MapObj01Hei "Height Classification of MAP Object";
CM_ SG_ 349 MapObj01P1Y "Point 1 y-axis of MAP Object";
CM_ SG_ 349 MapObj11P1Y "Point 1 y-axis of MAP Object";
CM_ SG_ 349 MapObj01P1X "Point 1 x-axis of MAP Object";
CM_ SG_ 349 MapObj11P2Y "Point 2 y-axis of MAP Object";
CM_ SG_ 349 MapObj11Hei "Height Classification of MAP Object";
CM_ SG_ 349 MapObj11P1X "Point 1 x-axis of MAP Object";
CM_ SG_ 349 APA_ADC_02_MsgCntr "2-bit Counter";
CM_ SG_ 349 MapObj11Problty "Probability that MAP Object is a 'Real' object";
CM_ SG_ 349 APA_ADC_02_CRC "SAE J1850 8-bit Checksum";
CM_ SG_ 349 MapObj01Problty "Probability that MAP Object is a 'Real' object";
CM_ SG_ 349 MapObj11P2X "Point 2 x-axis of MAP Object";
CM_ SG_ 349 MapObj11Typ "Type Classification of MAP Object";
CM_ SG_ 349 MapObj01HeiProblty "Probability that MAP Object is a 'High' object";
CM_ SG_ 349 MapObjX1Offs "Attributes for Map Object# (# = 1 + Offset * 10)";
CM_ SG_ 349 MapObj11HeiProblty "Probability that MAP Object is a 'High' object";
CM_ SG_ 349 MapObj01Typ "Type Classification of MAP Object";
CM_ SG_ 349 MapObj01P2X "Point 2 x-axis of MAP Object";
CM_ SG_ 349 MapObj01P2Y "Point 2 y-axis of MAP Object";
CM_ SG_ 348 MapObj10P2Y "Point 2 y-axis of MAP Object";
CM_ SG_ 348 APA_ADC_01_MsgCntr "2-bit Counter";
CM_ SG_ 348 MapObj10Problty "Probability that MAP Object is a 'Real' object";
CM_ SG_ 348 MapObj00Problty "Probability that MAP Object is a 'Real' object";
CM_ SG_ 348 MapObj00P2X "Point 2 x-axis of MAP Object";
CM_ SG_ 348 MapObj10Typ "Type Classification of MAP Object";
CM_ SG_ 348 MapObj00HeiProblty "Probability that MAP Object is a 'High' object";
CM_ SG_ 348 APA_ADC_01_CRC "SAE J1850 8-bit Checksum";
CM_ SG_ 348 MapObj10P2X "Point 2 x-axis of MAP Object";
CM_ SG_ 348 MapObj00P1Y "Point 1 y-axis of MAP Object";
CM_ SG_ 348 MapObj10HeiProblty "Probability that MAP Object is a 'High' object";
CM_ SG_ 348 MapObj00Typ "Type Classification of MAP Object";
CM_ SG_ 348 MapObj10Hei "Height Classification of MAP Object";
CM_ SG_ 348 MapObjX0Offs "Attributes for Map Object# (# = 0 + Offset * 10)";
CM_ SG_ 348 MapObj10P1Y "Point 1 y-axis of MAP Object";
CM_ SG_ 348 MapObj00P2Y "Point 2 y-axis of MAP Object";
CM_ SG_ 348 MapObj10P1X "Point 1 x-axis of MAP Object";
CM_ SG_ 348 MapObj00Hei "Height Classification of MAP Object";
CM_ SG_ 348 MapObj00P1X "Point 1 x-axis of MAP Object";
CM_ SG_ 648 ApaPscSlotCrossRiVehY "The y component of the vector from the center of the vehicle's rear axle to the rear street side corner of the lead vehicle forming the parking slot. Set to NO_SPACE until status = pre-guidance.";
CM_ SG_ 648 ApaXSlotYVehX "The x component of the vector from the center of the vehicle's rear axle to the rear street side corner of the lead vehicle forming the parking slot. Set to NO_SPACE until status = pre-guidance.";
CM_ SG_ 648 ApaPocSlotParallelRiVehY "The y component of the vector from the center of the vehicle's rear axle to the rear street side corner of the lead vehicle forming the parking slot. Set to NO_SPACE until status = pre-guidance.";
CM_ SG_ 648 ApaPocSlotParallelLeSizeY "The y axis dimension of the space (y axis is along the width of the vehicle)";
CM_ SG_ 648 ApaPscSlotCrossLeVehX "The x component of the vector from the center of the vehicle's rear axle to the rear street side corner of the lead vehicle forming the parking slot. Set to NO_SPACE until status = pre-guidance.";
CM_ SG_ 648 ApaXSlotYSizeX "The x axis dimension of the space (x axis is along the length of the vehicle)";
CM_ SG_ 648 ApaPscSlotCrossRiVehPsi "Angle of car with respect to the front target vehicle. Set to NO_SPACE until status = pre-guidance.";
CM_ SG_ 648 ApaPocSlotParallelRiVehPsi "Angle of car with respect to the front target vehicle. Set to NO_SPACE until status = pre-guidance.";
CM_ SG_ 648 ApaPocSlotParallelRiSizeX "The x axis dimension of the space (x axis is along the length of the vehicle)";
CM_ SG_ 648 ApaPocSlotParallelRiSizeY "The y axis dimension of the space (y axis is along the width of the vehicle)";
CM_ SG_ 648 ApaPscSlotCrossRiSizeY "The y axis dimension of the space (y axis is along the width of the vehicle)";
CM_ SG_ 648 ApaPscSlotParallelRiVehX "The x component of the vector from the center of the vehicle's rear axle to the rear street side corner of the lead vehicle forming the parking slot. Set to NO_SPACE until status = pre-guidance.";
CM_ SG_ 648 ApaPscSlotParallelLeVehPsi "Angle of car with respect to the front target vehicle. Set to NO_SPACE until status = pre-guidance.";
CM_ SG_ 648 ApaPocSlotParallelLeVehY "The y component of the vector from the center of the vehicle's rear axle to the rear street side corner of the lead vehicle forming the parking slot. Set to NO_SPACE until status = pre-guidance.";
CM_ SG_ 648 ApaXSlotYSizeY "The y axis dimension of the space (y axis is along the width of the vehicle)";
CM_ SG_ 648 ApaXSlotYVehPsi "Angle of car with respect to the front target vehicle. Set to NO_SPACE until status = pre-guidance.";
CM_ SG_ 648 ApaPscSlotParallelRiSizeX "The x axis dimension of the space (x axis is along the length of the vehicle)";
CM_ SG_ 648 ApaPscSlotParallelLeVehY "The y component of the vector from the center of the vehicle's rear axle to the rear street side corner of the lead vehicle forming the parking slot. Set to NO_SPACE until status = pre-guidance.";
CM_ SG_ 648 ApaPscSlotParallelLeSizeX "The x axis dimension of the space (x axis is along the length of the vehicle)";
CM_ SG_ 648 ApaPocSlotParallelLeVehPsi "Angle of car with respect to the front target vehicle. Set to NO_SPACE until status = pre-guidance.";
CM_ SG_ 648 ApaPscSlotParallelRiSizeY "The y axis dimension of the space (y axis is along the width of the vehicle)";
CM_ SG_ 648 ApaPocSlotParallelLeSizeX "The x axis dimension of the space (x axis is along the length of the vehicle)";
CM_ SG_ 648 ApaPscSlotCrossLeVehPsi "Angle of car with respect to the front target vehicle. Set to NO_SPACE until status = pre-guidance.";
CM_ SG_ 648 ApaPscSlotCrossRiVehX "The x component of the vector from the center of the vehicle's rear axle to the rear street side corner of the lead vehicle forming the parking slot. Set to NO_SPACE until status = pre-guidance.";
CM_ SG_ 648 ApaPscVehSlotTyp "Multiplexor for the current parking slot type";
CM_ SG_ 648 ApaPocSlotParallelLeVehX "The x component of the vector from the center of the vehicle's rear axle to the rear street side corner of the lead vehicle forming the parking slot. Set to NO_SPACE until status = pre-guidance.";
CM_ SG_ 648 ApaPscSlotCrossLeSizeX "The x axis dimension of the space (x axis is along the length of the vehicle)";
CM_ SG_ 648 ApaPscSlotParallelLeSizeY "The y axis dimension of the space (y axis is along the width of the vehicle)";
CM_ SG_ 648 ApaPscSlotParallelLeVehX "The x component of the vector from the center of the vehicle's rear axle to the rear street side corner of the lead vehicle forming the parking slot. Set to NO_SPACE until status = pre-guidance.";
CM_ SG_ 648 ApaPscSlotParallelRiVehPsi "Angle of car with respect to the front target vehicle. Set to NO_SPACE until status = pre-guidance.";
CM_ SG_ 648 ApaXSlotYVehY "The y component of the vector from the center of the vehicle's rear axle to the rear street side corner of the lead vehicle forming the parking slot. Set to NO_SPACE until status = pre-guidance.";
CM_ SG_ 648 ApaPscSlotParallelRiVehY "The y component of the vector from the center of the vehicle's rear axle to the rear street side corner of the lead vehicle forming the parking slot. Set to NO_SPACE until status = pre-guidance.";
CM_ SG_ 648 ApaPscSlotCrossRiSizeX "The x axis dimension of the space (x axis is along the length of the vehicle)";
CM_ SG_ 648 ApaPscSlotCrossLeVehY "The y component of the vector from the center of the vehicle's rear axle to the rear street side corner of the lead vehicle forming the parking slot. Set to NO_SPACE until status = pre-guidance.";
CM_ SG_ 648 ApaPocSlotParallelRiVehX "The x component of the vector from the center of the vehicle's rear axle to the rear street side corner of the lead vehicle forming the parking slot. Set to NO_SPACE until status = pre-guidance.";
CM_ SG_ 648 ApaPscSlotCrossLeSizeY "The y axis dimension of the space (y axis is along the width of the vehicle)";
CM_ SG_ 651 ReLeMidRegnDst "Distance to the closest object in the UPA Rear Left Middle Region.";
CM_ SG_ 651 APA_06_CRC "SAE J1850 8-bit Checksum Checksum";
CM_ SG_ 651 APA_06_MsgCntr "4-bit Counter";
CM_ SG_ 651 ReLeRegnDst "Distance to the closest object in the UPA Rear Left Region.";
CM_ SG_ 651 ReSnsrFltSt "Rear UPA degradation status (dependent on most severe active fault).";
CM_ SG_ 651 ReRiMidRegnDst "Distance to the closest object in the UPA Rear Right Middle Region.";
CM_ SG_ 651 ReRiRegnDst "Distance to the closest object in the UPA Rear Right Region.";
CM_ SG_ 651 ReMidRegnDst "Distance to the closest object in the UPA Rear Middle Region.";
CM_ SG_ 651 ReSysSts "UPA is active and the rear sensors are firing.";
CM_ SG_ 650 FrntRiRegnDst "Distance to the closest object in the UPA Front Right Region.";
CM_ SG_ 650 FrntLeRegnDst "Distance to the closest object in the UPA Front Left Region.";
CM_ SG_ 650 FrntSnsrFltSt "Front UPA degradation status (dependent on most severe active fault).";
CM_ SG_ 650 FrntMidRegnDst "Distance to the closest object in the UPA Front Middle Region.";
CM_ SG_ 650 FrntLeMidRegnDst "Distance to the closest object in the UPA Front Left Middle Region.";
CM_ SG_ 650 APA_05_CRC "SAE J1850 8-bit Checksum Checksum";
CM_ SG_ 650 APA_05_MsgCntr "4-bit Counter";
CM_ SG_ 650 FrntRiMidRegnDst "Distance to the closest object in the UPA Front Right Middle Region.";
CM_ SG_ 650 FrntSysSts "UPA is active and the front sensors are firing.";
CM_ SG_ 646 ApaPscSlotCrossRiObj2Alpha "The angle of the lead object, always zero for parallel clockwise negative for perpendicular";
CM_ SG_ 646 ApaXSlotYObj1Y "The y coordinate of the forward left corner of the parking slot based on border as defined by lead object";
CM_ SG_ 646 ApaXSlotYObj2Y "The y coordinate of the backward left corner of the parking slot based on border as defined by following object";
CM_ SG_ 646 ApaXSlotYObj2Alpha "The angle of the lead object, always zero for parallel clockwise negative for perpendicular";
CM_ SG_ 646 ApaPocSlotParallelLeObj1Y "The y coordinate of the forward left corner of the parking slot based on border as defined by lead object";
CM_ SG_ 646 ApaPscSlotParallelRiObj2Alpha "The angle of the lead object, always zero for parallel clockwise negative for perpendicular";
CM_ SG_ 646 ApaPscSlotCrossRiObj1Y "The y coordinate of the forward left corner of the parking slot based on border as defined by lead object";
CM_ SG_ 646 ApaPscSlotParallelRiObj2X "The x coordinate of the backward left corner of the parking slot based on border as defined by following object";
CM_ SG_ 646 ApaPscSlotParallelLeObj2X "The x coordinate of the backward left corner of the parking slot based on border as defined by following object";
CM_ SG_ 646 ApaPocSlotParallelRiObj1X "The x coordinate of the forward left corner of the parking slot based on border as defined by lead object";
CM_ SG_ 646 ApaPocSlotParallelLeObj2Alpha "The angle of the lead object, always zero for parallel clockwise negative for perpendicular";
CM_ SG_ 646 ApaPocSlotParallelRiObj1Alpha "The angle of the lead object, always zero for parallel clockwise negative for perpendicular";
CM_ SG_ 646 ApaPscSlotCrossLeObj2Alpha "The angle of the lead object, always zero for parallel clockwise negative for perpendicular";
CM_ SG_ 646 ApaPscSlotParallelLeObj1X "The x coordinate of the forward left corner of the parking slot based on border as defined by lead object";
CM_ SG_ 646 ApaPscSlotCrossLeObj2Y "The y coordinate of the backward left corner of the parking slot based on border as defined by following object";
CM_ SG_ 646 ApaPscSlotCrossRiObj1Alpha "The angle of the lead object, always zero for parallel clockwise negative for perpendicular";
CM_ SG_ 646 ApaPscSlotCrossRiObj1X "The x coordinate of the forward left corner of the parking slot based on border as defined by lead object";
CM_ SG_ 646 ApaPscSlotParallelLeObj1Y "The y coordinate of the forward left corner of the parking slot based on border as defined by lead object";
CM_ SG_ 646 ApaPocSlotParallelRiObj1Y "The y coordinate of the forward left corner of the parking slot based on border as defined by lead object";
CM_ SG_ 646 ApaPocSlotParallelRiObj2Alpha "The angle of the lead object, always zero for parallel clockwise negative for perpendicular";
CM_ SG_ 646 ApaPscSlotParallelRiObj1X "The x coordinate of the forward left corner of the parking slot based on border as defined by lead object";
CM_ SG_ 646 ApaPscSlotParallelRiObj1Alpha "The angle of the lead object, always zero for parallel clockwise negative for perpendicular";
CM_ SG_ 646 ApaPocSlotParallelLeObj2X "The x coordinate of the backward left corner of the parking slot based on border as defined by following object";
CM_ SG_ 646 ApaPscSlotParallelRiObj1Y "The y coordinate of the forward left corner of the parking slot based on border as defined by lead object";
CM_ SG_ 646 ApaXSlotYObj1Alpha "The angle of the lead object, always zero for parallel clockwise negative for perpendicular";
CM_ SG_ 646 ApaPscSlotParallelLeObj1Alpha "The angle of the lead object, always zero for parallel clockwise negative for perpendicular";
CM_ SG_ 646 ApaPocSlotParallelRiObj2Y "The y coordinate of the backward left corner of the parking slot based on border as defined by following object";
CM_ SG_ 646 ApaPscSlotCrossLeObj1Alpha "The angle of the lead object, always zero for parallel clockwise negative for perpendicular";
CM_ SG_ 646 ApaXSlotYObj2X "The x coordinate of the backward left corner of the parking slot based on border as defined by following object";
CM_ SG_ 646 ApaPscSlotCrossLeObj2X "The x coordinate of the backward left corner of the parking slot based on border as defined by following object";
CM_ SG_ 646 ApaPocSlotParallelRiObj2X "The x coordinate of the backward left corner of the parking slot based on border as defined by following object";
CM_ SG_ 646 ApaPocSlotParallelLeObj1X "The x coordinate of the forward left corner of the parking slot based on border as defined by lead object";
CM_ SG_ 646 ApaPscSlotCrossLeObj1Y "The y coordinate of the forward left corner of the parking slot based on border as defined by lead object";
CM_ SG_ 646 ApaPscSlotParallelLeObj2Alpha "The angle of the lead object, always zero for parallel clockwise negative for perpendicular";
CM_ SG_ 646 ApaPscEnvSlotTyp "Multiplexor for the current parking slot type";
CM_ SG_ 646 ApaPscSlotParallelLeObj2Y "The y coordinate of the backward left corner of the parking slot based on border as defined by following object";
CM_ SG_ 646 ApaXSlotYObj1X "The x coordinate of the forward left corner of the parking slot based on border as defined by lead object";
CM_ SG_ 646 ApaPscSlotParallelRiObj2Y "The y coordinate of the backward left corner of the parking slot based on border as defined by following object";
CM_ SG_ 646 ApaPscSlotCrossRiObj2X "The x coordinate of the backward left corner of the parking slot based on border as defined by following object";
CM_ SG_ 646 ApaPocSlotParallelLeObj1Alpha "The angle of the lead object, always zero for parallel clockwise negative for perpendicular";
CM_ SG_ 646 ApaPscSlotCrossLeObj1X "The x coordinate of the forward left corner of the parking slot based on border as defined by lead object";
CM_ SG_ 646 ApaPocSlotParallelLeObj2Y "The y coordinate of the backward left corner of the parking slot based on border as defined by following object";
CM_ SG_ 646 ApaPscSlotCrossRiObj2Y "The y coordinate of the backward left corner of the parking slot based on border as defined by following object";
CM_ SG_ 422 ApaPscSlotParallelRi "Parkable status of the parking slot";
CM_ SG_ 422 UpaSysSts "Current UPA operating mode.";
CM_ SG_ 422 ApaPocSlotParallelLe "Status on whether can unpark to the left";
CM_ SG_ 422 UpaSysSrv "Service PPM because of:
- ECU Hardware Failure
- Permanent Ultrasonic Sensor Failures (Sensor Supply Voltage errors, etc...)";
CM_ SG_ 422 ApaPocSlotParallelRi "Status on whether can unpark to the right";
CM_ SG_ 422 ApaPscSlotCrossLe "Parkable status of the parking slot";
CM_ SG_ 422 APA_03_MsgCntr "4-bit Counter";
CM_ SG_ 422 ApaInstruction "Current APA Guidance Instruction";
CM_ SG_ 422 ApaStatus "Current APA operating mode.";
CM_ SG_ 422 UpaSysDi "PPM disabled due to external interfaces:
- ECU Supply Voltage Failure
- Comm Based Failures (CAN Bus Off / LOC / Invalid Data)";
CM_ SG_ 422 ApaAbortReason "The reason for aborting APA";
CM_ SG_ 422 APA_03_CRC "SAE J1850 8-bit Checksum Checksum";
CM_ SG_ 422 ApaPscSlotParallelLe "Parkable status of the parking slot";
CM_ SG_ 422 ApaPscSlotCrossRi "Parkable status of the parking slot";
CM_ SG_ 197 APA_02_MsgCntr "4-bit Counter";
CM_ SG_ 197 APA_02_CRC "SAE J1850 8-bit Checksum Checksum";
CM_ SG_ 197 ApaMaxVelocity "Maximum vehicle velocity allowed for current manuever";
CM_ SG_ 197 ApaManeuverDst "Distance remaining to the target position";
CM_ SG_ 196 APA_EPSReqTyp "Steering wheel angle request active     ";
CM_ SG_ 196 AbsltPinionAgReq "Absolute pinion angle angle request(Invalid value 0x7FFF )
Clock-Wise = Right = Minus
Counter Clock-Wise = Left = Plus";
CM_ SG_ 196 APASts "Advanced Park Assist (APA)  Status     ";
CM_ SG_ 196 AbsltPinionAgReqValid "Absolute pinion angle request validity ";
CM_ SG_ 196 APA_01_CRC "APA_01 CRC     ";
CM_ SG_ 196 APA_01_MsgCntr "APA_01 Message Counter     ";
CM_ SG_ 556 ADCVoltWakeupReq "ADC voltage wakeup request";
CM_ SG_ 62 ACM_03_CRC "ACM_03 CRC    ";
CM_ SG_ 62 LgtAValSts "Longitudinal acceleration value status    ";
CM_ SG_ 62 ACM_03_MsgCntr "ACM_03 Message counter    ";
CM_ SG_ 62 AxAyYrsCalSts "Ax Ay yaw rate sensor calibrated status";
CM_ SG_ 62 LgtA "Longitudinal acceleration 
Invalid values FA1 - 0xFFFF   ";
CM_ SG_ 61 ACM_02_CRC "ACM_02 CRC    ";
CM_ SG_ 61 LatAValSts "Lateral acceleration value status    ";
CM_ SG_ 61 YawRateValSts "Yaw rate value staus    ";
CM_ SG_ 61 ACM_02_MsgCntr "ACM_02 Message counter    ";
CM_ SG_ 61 YawRate "Yaw rate
Invalid value 0x8CA1 - 0xFFFF    ";
CM_ SG_ 61 LatA "Lateral acceleration
Invalid values FA1 - 0xFFFF   ";
BA_DEF_ BO_  "GenMsgCycleTime" INT 0 0;
BA_DEF_ BO_  "GenMsgSendType" ENUM  "Cyclic","NotUsed","NotUsed","NotUsed","NotUsed","NotUsed","NotUsed","IfActive","NoMsgSendType","NotUsed";
BA_DEF_ SG_  "GenSigStartValue" INT 0 0;
BA_DEF_ SG_  "GenSigCycleTimeActive" INT 0 0;
BA_DEF_ SG_  "GenSigCycleTime" INT 0 0;
BA_DEF_ SG_  "GenSigSendType" ENUM  "Cyclic","OnWrite","OnWriteWithRepetition","OnChange","OnChangeWithRepetition","IfActive","IfActiveWithRepetition","NoSigSendType","NotUsed","NotUsed","NotUsed","NotUsed","NotUsed";
BA_DEF_ SG_  "GenSigTimeoutValue" INT 0 65535;
BA_DEF_ BO_  "GenMsgILSupport" ENUM  "no","yes";
BA_DEF_ BO_  "DiagState" ENUM  "no","yes";
BA_DEF_ BO_  "DiagResponse" ENUM  "no","yes";
BA_DEF_ BO_  "DiagRequest" ENUM  "no","yes";
BA_DEF_REL_ BU_SG_REL_  "GenSigTimeoutTime" INT 0 65535;
BA_DEF_DEF_  "GenMsgCycleTime" 0;
BA_DEF_DEF_  "GenMsgSendType" "Cyclic";
BA_DEF_DEF_  "GenSigStartValue" 0;
BA_DEF_DEF_  "GenSigCycleTimeActive" 0;
BA_DEF_DEF_  "GenSigCycleTime" 0;
BA_DEF_DEF_  "GenSigSendType" "Cyclic";
BA_DEF_DEF_  "GenSigTimeoutValue" 0;
BA_DEF_DEF_  "GenMsgILSupport" "no";
BA_DEF_DEF_  "DiagState" "no";
BA_DEF_DEF_  "DiagResponse" "no";
BA_DEF_DEF_  "DiagRequest" "no";
BA_DEF_DEF_REL_ "GenSigTimeoutTime" 0;
BA_ "GenMsgILSupport" BO_ 425 1;
BA_ "GenMsgCycleTime" BO_ 425 10;
BA_ "GenMsgILSupport" BO_ 424 1;
BA_ "GenMsgCycleTime" BO_ 424 10;
BA_ "GenMsgILSupport" BO_ 423 1;
BA_ "GenMsgCycleTime" BO_ 423 10;
BA_ "GenMsgILSupport" BO_ 357 1;
BA_ "GenMsgCycleTime" BO_ 357 20;
BA_ "GenMsgILSupport" BO_ 356 1;
BA_ "GenMsgCycleTime" BO_ 356 20;
BA_ "GenMsgILSupport" BO_ 355 1;
BA_ "GenMsgCycleTime" BO_ 355 20;
BA_ "GenMsgILSupport" BO_ 354 1;
BA_ "GenMsgCycleTime" BO_ 354 20;
BA_ "GenMsgILSupport" BO_ 353 1;
BA_ "GenMsgCycleTime" BO_ 353 20;
BA_ "GenMsgILSupport" BO_ 352 1;
BA_ "GenMsgCycleTime" BO_ 352 20;
BA_ "GenMsgILSupport" BO_ 351 1;
BA_ "GenMsgCycleTime" BO_ 351 20;
BA_ "GenMsgILSupport" BO_ 350 1;
BA_ "GenMsgCycleTime" BO_ 350 20;
BA_ "GenMsgILSupport" BO_ 349 1;
BA_ "GenMsgCycleTime" BO_ 349 20;
BA_ "GenMsgILSupport" BO_ 348 1;
BA_ "GenMsgCycleTime" BO_ 348 20;
BA_ "GenMsgILSupport" BO_ 648 1;
BA_ "GenMsgCycleTime" BO_ 648 100;
BA_ "GenMsgILSupport" BO_ 651 1;
BA_ "GenMsgCycleTime" BO_ 651 250;
BA_ "GenMsgILSupport" BO_ 650 1;
BA_ "GenMsgCycleTime" BO_ 650 250;
BA_ "GenMsgILSupport" BO_ 646 1;
BA_ "GenMsgCycleTime" BO_ 646 100;
BA_ "GenMsgILSupport" BO_ 422 1;
BA_ "GenMsgCycleTime" BO_ 422 100;
BA_ "GenMsgILSupport" BO_ 197 1;
BA_ "GenMsgCycleTime" BO_ 197 20;
BA_ "GenMsgILSupport" BO_ 196 1;
BA_ "GenMsgCycleTime" BO_ 196 20;
BA_ "GenMsgILSupport" BO_ 556 1;
BA_ "GenMsgCycleTime" BO_ 556 100;
BA_ "GenMsgILSupport" BO_ 62 1;
BA_ "GenMsgCycleTime" BO_ 62 20;
BA_ "GenMsgILSupport" BO_ 61 1;
BA_ "GenMsgCycleTime" BO_ 61 20;
BA_ "GenSigStartValue" SG_ 357 MapObj19P1Y 511;
BA_ "GenSigStartValue" SG_ 357 MapObj09P1Y 511;
BA_ "GenSigStartValue" SG_ 357 MapObj09P1X 511;
BA_ "GenSigStartValue" SG_ 357 MapObj09P2X 511;
BA_ "GenSigStartValue" SG_ 357 MapObj19P2X 511;
BA_ "GenSigStartValue" SG_ 357 MapObj09P2Y 511;
BA_ "GenSigStartValue" SG_ 357 MapObj19P2Y 511;
BA_ "GenSigStartValue" SG_ 357 MapObj19P1X 511;
BA_ "GenSigStartValue" SG_ 356 MapObj08P1X 511;
BA_ "GenSigStartValue" SG_ 356 MapObj08P2Y 511;
BA_ "GenSigStartValue" SG_ 356 MapObj18P2X 511;
BA_ "GenSigStartValue" SG_ 356 MapObj08P2X 511;
BA_ "GenSigStartValue" SG_ 356 MapObj08P1Y 511;
BA_ "GenSigStartValue" SG_ 356 MapObj18P1X 511;
BA_ "GenSigStartValue" SG_ 356 MapObj18P1Y 511;
BA_ "GenSigStartValue" SG_ 356 MapObj18P2Y 511;
BA_ "GenSigStartValue" SG_ 355 MapObj07P2X 511;
BA_ "GenSigStartValue" SG_ 355 MapObj07P1X 511;
BA_ "GenSigStartValue" SG_ 355 MapObj07P1Y 511;
BA_ "GenSigStartValue" SG_ 355 MapObj17P2X 511;
BA_ "GenSigStartValue" SG_ 355 MapObj17P2Y 511;
BA_ "GenSigStartValue" SG_ 355 MapObj07P2Y 511;
BA_ "GenSigStartValue" SG_ 355 MapObj17P1Y 511;
BA_ "GenSigStartValue" SG_ 355 MapObj17P1X 511;
BA_ "GenSigStartValue" SG_ 354 MapObj16P2X 511;
BA_ "GenSigStartValue" SG_ 354 MapObj16P2Y 511;
BA_ "GenSigStartValue" SG_ 354 MapObj06P1Y 511;
BA_ "GenSigStartValue" SG_ 354 MapObj16P1Y 511;
BA_ "GenSigStartValue" SG_ 354 MapObj06P1X 511;
BA_ "GenSigStartValue" SG_ 354 MapObj16P1X 511;
BA_ "GenSigStartValue" SG_ 354 MapObj06P2X 511;
BA_ "GenSigStartValue" SG_ 354 MapObj06P2Y 511;
BA_ "GenSigStartValue" SG_ 353 MapObj15P1Y 511;
BA_ "GenSigStartValue" SG_ 353 MapObj05P1Y 511;
BA_ "GenSigStartValue" SG_ 353 MapObj05P1X 511;
BA_ "GenSigStartValue" SG_ 353 MapObj15P2Y 511;
BA_ "GenSigStartValue" SG_ 353 MapObj15P2X 511;
BA_ "GenSigStartValue" SG_ 353 MapObj05P2X 511;
BA_ "GenSigStartValue" SG_ 353 MapObj15P1X 511;
BA_ "GenSigStartValue" SG_ 353 MapObj05P2Y 511;
BA_ "GenSigStartValue" SG_ 352 MapObj04P1Y 511;
BA_ "GenSigStartValue" SG_ 352 MapObj14P1Y 511;
BA_ "GenSigStartValue" SG_ 352 MapObj14P2Y 511;
BA_ "GenSigStartValue" SG_ 352 MapObj14P1X 511;
BA_ "GenSigStartValue" SG_ 352 MapObj04P1X 511;
BA_ "GenSigStartValue" SG_ 352 MapObj14P2X 511;
BA_ "GenSigStartValue" SG_ 352 MapObj04P2Y 511;
BA_ "GenSigStartValue" SG_ 352 MapObj04P2X 511;
BA_ "GenSigStartValue" SG_ 351 MapObj13P1X 511;
BA_ "GenSigStartValue" SG_ 351 MapObj13P1Y 511;
BA_ "GenSigStartValue" SG_ 351 MapObj03P2X 511;
BA_ "GenSigStartValue" SG_ 351 MapObj03P2Y 511;
BA_ "GenSigStartValue" SG_ 351 MapObj03P1Y 511;
BA_ "GenSigStartValue" SG_ 351 MapObj03P1X 511;
BA_ "GenSigStartValue" SG_ 351 MapObj13P2Y 511;
BA_ "GenSigStartValue" SG_ 351 MapObj13P2X 511;
BA_ "GenSigStartValue" SG_ 350 MapObj02P2Y 511;
BA_ "GenSigStartValue" SG_ 350 MapObj02P2X 511;
BA_ "GenSigStartValue" SG_ 350 MapObj12P2Y 511;
BA_ "GenSigStartValue" SG_ 350 MapObj12P2X 511;
BA_ "GenSigStartValue" SG_ 350 MapObj12P1Y 511;
BA_ "GenSigStartValue" SG_ 350 MapObj02P1Y 511;
BA_ "GenSigStartValue" SG_ 350 MapObj02P1X 511;
BA_ "GenSigStartValue" SG_ 350 MapObj12P1X 511;
BA_ "GenSigStartValue" SG_ 349 MapObj01P1Y 511;
BA_ "GenSigStartValue" SG_ 349 MapObj11P1Y 511;
BA_ "GenSigStartValue" SG_ 349 MapObj01P1X 511;
BA_ "GenSigStartValue" SG_ 349 MapObj11P2Y 511;
BA_ "GenSigStartValue" SG_ 349 MapObj11P1X 511;
BA_ "GenSigStartValue" SG_ 349 MapObj11P2X 511;
BA_ "GenSigStartValue" SG_ 349 MapObj01P2X 511;
BA_ "GenSigStartValue" SG_ 349 MapObj01P2Y 511;
BA_ "GenSigStartValue" SG_ 348 MapObj10P2Y 511;
BA_ "GenSigStartValue" SG_ 348 MapObj00P2X 511;
BA_ "GenSigStartValue" SG_ 348 MapObj10P2X 511;
BA_ "GenSigStartValue" SG_ 348 MapObj00P1Y 511;
BA_ "GenSigStartValue" SG_ 348 MapObj10P1Y 511;
BA_ "GenSigStartValue" SG_ 348 MapObj00P2Y 511;
BA_ "GenSigStartValue" SG_ 348 MapObj10P1X 511;
BA_ "GenSigStartValue" SG_ 348 MapObj00P1X 511;
BA_ "GenSigSendType" SG_ 422 ApaPscSlotParallelRi 3;
BA_ "GenSigSendType" SG_ 422 UpaSysSts 3;
BA_ "GenSigSendType" SG_ 422 ApaPocSlotParallelLe 3;
BA_ "GenSigSendType" SG_ 422 UpaSysSrv 3;
BA_ "GenSigSendType" SG_ 422 ApaPocSlotParallelRi 3;
BA_ "GenSigSendType" SG_ 422 ApaPscSlotCrossLe 3;
BA_ "GenSigSendType" SG_ 422 ApaInstruction 3;
BA_ "GenSigSendType" SG_ 422 ApaStatus 3;
BA_ "GenSigSendType" SG_ 422 UpaSysDi 3;
BA_ "GenSigSendType" SG_ 422 ApaAbortReason 3;
BA_ "GenSigSendType" SG_ 422 ApaPscSlotParallelLe 3;
BA_ "GenSigSendType" SG_ 422 ApaPscSlotCrossRi 3;
BA_ "GenSigStartValue" SG_ 196 AbsltPinionAgReq 16384;
BA_ "GenSigStartValue" SG_ 62 LgtAValSts 3;
BA_ "GenSigStartValue" SG_ 62 AxAyYrsCalSts 3;
BA_ "GenSigStartValue" SG_ 62 LgtA 2000;
BA_ "GenSigStartValue" SG_ 61 LatAValSts 3;
BA_ "GenSigStartValue" SG_ 61 YawRateValSts 3;
BA_ "GenSigStartValue" SG_ 61 YawRate 18000;
BA_ "GenSigStartValue" SG_ 61 LatA 2000;
BA_REL_ "GenSigTimeoutTime" BU_SG_REL_ ADC SG_ 425 sens05De3Distance_APA 150;
BA_REL_ "GenSigTimeoutTime" BU_SG_REL_ ADC SG_ 425 sens08De2Quality_APA 150;
BA_REL_ "GenSigTimeoutTime" BU_SG_REL_ ADC SG_ 425 deMsgChecksum_APA 150;
BA_REL_ "GenSigTimeoutTime" BU_SG_REL_ ADC SG_ 425 sens03De2Quality_APA 150;
BA_REL_ "GenSigTimeoutTime" BU_SG_REL_ ADC SG_ 425 sens12De2Distance_APA 150;
BA_REL_ "GenSigTimeoutTime" BU_SG_REL_ ADC SG_ 425 sens01De3Distance_APA 150;
BA_REL_ "GenSigTimeoutTime" BU_SG_REL_ ADC SG_ 425 sens02De1Quality_APA 150;
BA_REL_ "GenSigTimeoutTime" BU_SG_REL_ ADC SG_ 425 sens07De3Quality_APA 150;
BA_REL_ "GenSigTimeoutTime" BU_SG_REL_ ADC SG_ 425 sens05De1Quality_APA 150;
BA_REL_ "GenSigTimeoutTime" BU_SG_REL_ ADC SG_ 425 sens10De2Distance_APA 150;
BA_REL_ "GenSigTimeoutTime" BU_SG_REL_ ADC SG_ 425 sens08De1Quality_APA 150;
BA_REL_ "GenSigTimeoutTime" BU_SG_REL_ ADC SG_ 425 sens06De1Quality_APA 150;
BA_REL_ "GenSigTimeoutTime" BU_SG_REL_ ADC SG_ 425 sens10De3Quality_APA 150;
BA_REL_ "GenSigTimeoutTime" BU_SG_REL_ ADC SG_ 425 sens12De1Distance_APA 150;
BA_REL_ "GenSigTimeoutTime" BU_SG_REL_ ADC SG_ 425 sens11De1Quality_APA 150;
BA_REL_ "GenSigTimeoutTime" BU_SG_REL_ ADC SG_ 425 sens11De2Distance_APA 150;
BA_REL_ "GenSigTimeoutTime" BU_SG_REL_ ADC SG_ 425 sens03De2Distance_APA 150;
BA_REL_ "GenSigTimeoutTime" BU_SG_REL_ ADC SG_ 425 sens12De3Distance_APA 150;
BA_REL_ "GenSigTimeoutTime" BU_SG_REL_ ADC SG_ 425 sens09De1Distance_APA 150;
BA_REL_ "GenSigTimeoutTime" BU_SG_REL_ ADC SG_ 425 sens04De1Quality_APA 150;
BA_REL_ "GenSigTimeoutTime" BU_SG_REL_ ADC SG_ 425 sens01De2Distance_APA 150;
BA_REL_ "GenSigTimeoutTime" BU_SG_REL_ ADC SG_ 425 sens07De3Distance_APA 150;
BA_REL_ "GenSigTimeoutTime" BU_SG_REL_ ADC SG_ 425 sens07De2Quality_APA 150;
BA_REL_ "GenSigTimeoutTime" BU_SG_REL_ ADC SG_ 425 sens04De1Distance_APA 150;
BA_REL_ "GenSigTimeoutTime" BU_SG_REL_ ADC SG_ 425 sens04De3Distance_APA 150;
BA_REL_ "GenSigTimeoutTime" BU_SG_REL_ ADC SG_ 425 sens04De2Distance_APA 150;
BA_REL_ "GenSigTimeoutTime" BU_SG_REL_ ADC SG_ 425 sens08De3Quality_APA 150;
BA_REL_ "GenSigTimeoutTime" BU_SG_REL_ ADC SG_ 425 sens07De1Quality_APA 150;
BA_REL_ "GenSigTimeoutTime" BU_SG_REL_ ADC SG_ 425 sens10De2Quality_APA 150;
BA_REL_ "GenSigTimeoutTime" BU_SG_REL_ ADC SG_ 425 sens01De2Quality_APA 150;
BA_REL_ "GenSigTimeoutTime" BU_SG_REL_ ADC SG_ 425 sens09De2Quality_APA 150;
BA_REL_ "GenSigTimeoutTime" BU_SG_REL_ ADC SG_ 425 sens06De3Distance_APA 150;
BA_REL_ "GenSigTimeoutTime" BU_SG_REL_ ADC SG_ 425 sens09De1Quality_APA 150;
BA_REL_ "GenSigTimeoutTime" BU_SG_REL_ ADC SG_ 425 sens06De1Distance_APA 150;
BA_REL_ "GenSigTimeoutTime" BU_SG_REL_ ADC SG_ 425 deMsgCounter_APA 150;
BA_REL_ "GenSigTimeoutTime" BU_SG_REL_ ADC SG_ 425 sens07De2Distance_APA 150;
BA_REL_ "GenSigTimeoutTime" BU_SG_REL_ ADC SG_ 425 deMsgSensorIdx_APA 150;
BA_REL_ "GenSigTimeoutTime" BU_SG_REL_ ADC SG_ 425 sens12De2Quality_APA 150;
BA_REL_ "GenSigTimeoutTime" BU_SG_REL_ ADC SG_ 425 sens10De1Quality_APA 150;
BA_REL_ "GenSigTimeoutTime" BU_SG_REL_ ADC SG_ 425 sens04De3Quality_APA 150;
BA_REL_ "GenSigTimeoutTime" BU_SG_REL_ ADC SG_ 425 sens11De3Quality_APA 150;
BA_REL_ "GenSigTimeoutTime" BU_SG_REL_ ADC SG_ 425 sens03De1Quality_APA 150;
BA_REL_ "GenSigTimeoutTime" BU_SG_REL_ ADC SG_ 425 sens12De1Quality_APA 150;
BA_REL_ "GenSigTimeoutTime" BU_SG_REL_ ADC SG_ 425 sens09De3Quality_APA 150;
BA_REL_ "GenSigTimeoutTime" BU_SG_REL_ ADC SG_ 425 sens05De2Quality_APA 150;
BA_REL_ "GenSigTimeoutTime" BU_SG_REL_ ADC SG_ 425 sens06De3Quality_APA 150;
BA_REL_ "GenSigTimeoutTime" BU_SG_REL_ ADC SG_ 425 sens01De3Quality_APA 150;
BA_REL_ "GenSigTimeoutTime" BU_SG_REL_ ADC SG_ 425 sens09De2Distance_APA 150;
BA_REL_ "GenSigTimeoutTime" BU_SG_REL_ ADC SG_ 425 sens11De3Distance_APA 150;
BA_REL_ "GenSigTimeoutTime" BU_SG_REL_ ADC SG_ 425 sens02De2Distance_APA 150;
BA_REL_ "GenSigTimeoutTime" BU_SG_REL_ ADC SG_ 425 sens02De2Quality_APA 150;
BA_REL_ "GenSigTimeoutTime" BU_SG_REL_ ADC SG_ 425 sens11De1Distance_APA 150;
BA_REL_ "GenSigTimeoutTime" BU_SG_REL_ ADC SG_ 425 sens02De1Distance_APA 150;
BA_REL_ "GenSigTimeoutTime" BU_SG_REL_ ADC SG_ 425 sens05De1Distance_APA 150;
BA_REL_ "GenSigTimeoutTime" BU_SG_REL_ ADC SG_ 425 sens03De3Quality_APA 150;
BA_REL_ "GenSigTimeoutTime" BU_SG_REL_ ADC SG_ 425 sens08De2Distance_APA 150;
BA_REL_ "GenSigTimeoutTime" BU_SG_REL_ ADC SG_ 425 sens05De2Distance_APA 150;
BA_REL_ "GenSigTimeoutTime" BU_SG_REL_ ADC SG_ 425 sens06De2Distance_APA 150;
BA_REL_ "GenSigTimeoutTime" BU_SG_REL_ ADC SG_ 425 sens04De2Quality_APA 150;
BA_REL_ "GenSigTimeoutTime" BU_SG_REL_ ADC SG_ 425 sens08De1Distance_APA 150;
BA_REL_ "GenSigTimeoutTime" BU_SG_REL_ ADC SG_ 425 sens10De3Distance_APA 150;
BA_REL_ "GenSigTimeoutTime" BU_SG_REL_ ADC SG_ 425 sens05De3Quality_APA 150;
BA_REL_ "GenSigTimeoutTime" BU_SG_REL_ ADC SG_ 425 sens07De1Distance_APA 150;
BA_REL_ "GenSigTimeoutTime" BU_SG_REL_ ADC SG_ 425 sens10De1Distance_APA 150;
BA_REL_ "GenSigTimeoutTime" BU_SG_REL_ ADC SG_ 425 sens02De3Quality_APA 150;
BA_REL_ "GenSigTimeoutTime" BU_SG_REL_ ADC SG_ 425 sens12De3Quality_APA 150;
BA_REL_ "GenSigTimeoutTime" BU_SG_REL_ ADC SG_ 425 sens06De2Quality_APA 150;
BA_REL_ "GenSigTimeoutTime" BU_SG_REL_ ADC SG_ 425 sens03De3Distance_APA 150;
BA_REL_ "GenSigTimeoutTime" BU_SG_REL_ ADC SG_ 425 sens09De3Distance_APA 150;
BA_REL_ "GenSigTimeoutTime" BU_SG_REL_ ADC SG_ 425 sens03De1Distance_APA 150;
BA_REL_ "GenSigTimeoutTime" BU_SG_REL_ ADC SG_ 425 sens11De2Quality_APA 150;
BA_REL_ "GenSigTimeoutTime" BU_SG_REL_ ADC SG_ 425 sens01De1Quality_APA 150;
BA_REL_ "GenSigTimeoutTime" BU_SG_REL_ ADC SG_ 425 sens08De3Distance_APA 150;
BA_REL_ "GenSigTimeoutTime" BU_SG_REL_ ADC SG_ 425 sens02De3Distance_APA 150;
BA_REL_ "GenSigTimeoutTime" BU_SG_REL_ ADC SG_ 425 sens01De1Distance_APA 150;
BA_REL_ "GenSigTimeoutTime" BU_SG_REL_ ADC SG_ 424 Sens06CeRgt3Quality 150;
BA_REL_ "GenSigTimeoutTime" BU_SG_REL_ ADC SG_ 424 Sens08CeRgt1Distance 150;
BA_REL_ "GenSigTimeoutTime" BU_SG_REL_ ADC SG_ 424 Sens09CeRgt3Distance 150;
BA_REL_ "GenSigTimeoutTime" BU_SG_REL_ ADC SG_ 424 Sens06CeRgt1Distance 150;
BA_REL_ "GenSigTimeoutTime" BU_SG_REL_ ADC SG_ 424 Sens02CeRgt3Quality 150;
BA_REL_ "GenSigTimeoutTime" BU_SG_REL_ ADC SG_ 424 Sens04CeRgt2Quality 150;
BA_REL_ "GenSigTimeoutTime" BU_SG_REL_ ADC SG_ 424 Sens05CeRgt2Quality 150;
BA_REL_ "GenSigTimeoutTime" BU_SG_REL_ ADC SG_ 424 Sens04CeRgt3Quality 150;
BA_REL_ "GenSigTimeoutTime" BU_SG_REL_ ADC SG_ 424 CeRgtMsgSensorIdx 150;
BA_REL_ "GenSigTimeoutTime" BU_SG_REL_ ADC SG_ 424 Sens06CeRgt3Distance 150;
BA_REL_ "GenSigTimeoutTime" BU_SG_REL_ ADC SG_ 424 Sens10CeRgt3Distance 150;
BA_REL_ "GenSigTimeoutTime" BU_SG_REL_ ADC SG_ 424 Sens11CeRgt1Distance 150;
BA_REL_ "GenSigTimeoutTime" BU_SG_REL_ ADC SG_ 424 Sens05CeRgt3Quality 150;
BA_REL_ "GenSigTimeoutTime" BU_SG_REL_ ADC SG_ 424 Sens06CeRgt1Quality 150;
BA_REL_ "GenSigTimeoutTime" BU_SG_REL_ ADC SG_ 424 Sens11CeRgt1Quality 150;
BA_REL_ "GenSigTimeoutTime" BU_SG_REL_ ADC SG_ 424 Sens01CeRgt1Quality 150;
BA_REL_ "GenSigTimeoutTime" BU_SG_REL_ ADC SG_ 424 Sens04CeRgt2Distance 150;
BA_REL_ "GenSigTimeoutTime" BU_SG_REL_ ADC SG_ 424 Sens04CeRgt1Distance 150;
BA_REL_ "GenSigTimeoutTime" BU_SG_REL_ ADC SG_ 424 Sens11CeRgt2Distance 150;
BA_REL_ "GenSigTimeoutTime" BU_SG_REL_ ADC SG_ 424 Sens10CeRgt1Distance 150;
BA_REL_ "GenSigTimeoutTime" BU_SG_REL_ ADC SG_ 424 Sens12CeRgt3Quality 150;
BA_REL_ "GenSigTimeoutTime" BU_SG_REL_ ADC SG_ 424 Sens12CeRgt3Distance 150;
BA_REL_ "GenSigTimeoutTime" BU_SG_REL_ ADC SG_ 424 Sens04CeRgt1Quality 150;
BA_REL_ "GenSigTimeoutTime" BU_SG_REL_ ADC SG_ 424 Sens08CeRgt2Distance 150;
BA_REL_ "GenSigTimeoutTime" BU_SG_REL_ ADC SG_ 424 Sens03CeRgt1Quality 150;
BA_REL_ "GenSigTimeoutTime" BU_SG_REL_ ADC SG_ 424 Sens12CeRgt1Distance 150;
BA_REL_ "GenSigTimeoutTime" BU_SG_REL_ ADC SG_ 424 Sens02CeRgt2Distance 150;
BA_REL_ "GenSigTimeoutTime" BU_SG_REL_ ADC SG_ 424 Sens08CeRgt1Quality 150;
BA_REL_ "GenSigTimeoutTime" BU_SG_REL_ ADC SG_ 424 Sens08CeRgt3Distance 150;
BA_REL_ "GenSigTimeoutTime" BU_SG_REL_ ADC SG_ 424 Sens08CeRgt2Quality 150;
BA_REL_ "GenSigTimeoutTime" BU_SG_REL_ ADC SG_ 424 Sens01CeRgt3Distance 150;
BA_REL_ "GenSigTimeoutTime" BU_SG_REL_ ADC SG_ 424 Sens09CeRgt1Distance 150;
BA_REL_ "GenSigTimeoutTime" BU_SG_REL_ ADC SG_ 424 Sens07CeRgt2Quality 150;
BA_REL_ "GenSigTimeoutTime" BU_SG_REL_ ADC SG_ 424 Sens08CeRgt3Quality 150;
BA_REL_ "GenSigTimeoutTime" BU_SG_REL_ ADC SG_ 424 Sens03CeRgt3Distance 150;
BA_REL_ "GenSigTimeoutTime" BU_SG_REL_ ADC SG_ 424 Sens05CeRgt1Quality 150;
BA_REL_ "GenSigTimeoutTime" BU_SG_REL_ ADC SG_ 424 Sens07CeRgt2Distance 150;
BA_REL_ "GenSigTimeoutTime" BU_SG_REL_ ADC SG_ 424 Sens02CeRgt3Distance 150;
BA_REL_ "GenSigTimeoutTime" BU_SG_REL_ ADC SG_ 424 Sens02CeRgt1Quality 150;
BA_REL_ "GenSigTimeoutTime" BU_SG_REL_ ADC SG_ 424 Sens07CeRgt3Distance 150;
BA_REL_ "GenSigTimeoutTime" BU_SG_REL_ ADC SG_ 424 Sens03CeRgt2Quality 150;
BA_REL_ "GenSigTimeoutTime" BU_SG_REL_ ADC SG_ 424 Sens09CeRgt2Distance 150;
BA_REL_ "GenSigTimeoutTime" BU_SG_REL_ ADC SG_ 424 CeRgtMsgCounter 150;
BA_REL_ "GenSigTimeoutTime" BU_SG_REL_ ADC SG_ 424 Sens01CeRgt2Quality 150;
BA_REL_ "GenSigTimeoutTime" BU_SG_REL_ ADC SG_ 424 CeRgtMsgChecksum 150;
BA_REL_ "GenSigTimeoutTime" BU_SG_REL_ ADC SG_ 424 Sens01CeRgt1Distance 150;
BA_REL_ "GenSigTimeoutTime" BU_SG_REL_ ADC SG_ 424 Sens05CeRgt3Distance 150;
BA_REL_ "GenSigTimeoutTime" BU_SG_REL_ ADC SG_ 424 Sens11CeRgt2Quality 150;
BA_REL_ "GenSigTimeoutTime" BU_SG_REL_ ADC SG_ 424 Sens06CeRgt2Quality 150;
BA_REL_ "GenSigTimeoutTime" BU_SG_REL_ ADC SG_ 424 Sens10CeRgt3Quality 150;
BA_REL_ "GenSigTimeoutTime" BU_SG_REL_ ADC SG_ 424 Sens09CeRgt1Quality 150;
BA_REL_ "GenSigTimeoutTime" BU_SG_REL_ ADC SG_ 424 Sens12CeRgt2Distance 150;
BA_REL_ "GenSigTimeoutTime" BU_SG_REL_ ADC SG_ 424 Sens11CeRgt3Quality 150;
BA_REL_ "GenSigTimeoutTime" BU_SG_REL_ ADC SG_ 424 Sens05CeRgt1Distance 150;
BA_REL_ "GenSigTimeoutTime" BU_SG_REL_ ADC SG_ 424 Sens06CeRgt2Distance 150;
BA_REL_ "GenSigTimeoutTime" BU_SG_REL_ ADC SG_ 424 Sens01CeRgt2Distance 150;
BA_REL_ "GenSigTimeoutTime" BU_SG_REL_ ADC SG_ 424 Sens09CeRgt3Quality 150;
BA_REL_ "GenSigTimeoutTime" BU_SG_REL_ ADC SG_ 424 Sens05CeRgt2Distance 150;
BA_REL_ "GenSigTimeoutTime" BU_SG_REL_ ADC SG_ 424 Sens07CeRgt1Distance 150;
BA_REL_ "GenSigTimeoutTime" BU_SG_REL_ ADC SG_ 424 Sens01CeRgt3Quality 150;
BA_REL_ "GenSigTimeoutTime" BU_SG_REL_ ADC SG_ 424 Sens03CeRgt1Distance 150;
BA_REL_ "GenSigTimeoutTime" BU_SG_REL_ ADC SG_ 424 Sens02CeRgt2Quality 150;
BA_REL_ "GenSigTimeoutTime" BU_SG_REL_ ADC SG_ 424 Sens12CeRgt2Quality 150;
BA_REL_ "GenSigTimeoutTime" BU_SG_REL_ ADC SG_ 424 Sens10CeRgt2Quality 150;
BA_REL_ "GenSigTimeoutTime" BU_SG_REL_ ADC SG_ 424 Sens10CeRgt2Distance 150;
BA_REL_ "GenSigTimeoutTime" BU_SG_REL_ ADC SG_ 424 Sens12CeRgt1Quality 150;
BA_REL_ "GenSigTimeoutTime" BU_SG_REL_ ADC SG_ 424 Sens11CeRgt3Distance 150;
BA_REL_ "GenSigTimeoutTime" BU_SG_REL_ ADC SG_ 424 Sens02CeRgt1Distance 150;
BA_REL_ "GenSigTimeoutTime" BU_SG_REL_ ADC SG_ 424 Sens03CeRgt3Quality 150;
BA_REL_ "GenSigTimeoutTime" BU_SG_REL_ ADC SG_ 424 Sens10CeRgt1Quality 150;
BA_REL_ "GenSigTimeoutTime" BU_SG_REL_ ADC SG_ 424 Sens09CeRgt2Quality 150;
BA_REL_ "GenSigTimeoutTime" BU_SG_REL_ ADC SG_ 424 Sens07CeRgt1Quality 150;
BA_REL_ "GenSigTimeoutTime" BU_SG_REL_ ADC SG_ 424 Sens07CeRgt3Quality 150;
BA_REL_ "GenSigTimeoutTime" BU_SG_REL_ ADC SG_ 424 Sens04CeRgt3Distance 150;
BA_REL_ "GenSigTimeoutTime" BU_SG_REL_ ADC SG_ 424 Sens03CeRgt2Distance 150;
BA_REL_ "GenSigTimeoutTime" BU_SG_REL_ ADC SG_ 423 Sens03CeLft3Quality 150;
BA_REL_ "GenSigTimeoutTime" BU_SG_REL_ ADC SG_ 423 Sens02CeLft1Distance 150;
BA_REL_ "GenSigTimeoutTime" BU_SG_REL_ ADC SG_ 423 Sens01CeLft1Distance 150;
BA_REL_ "GenSigTimeoutTime" BU_SG_REL_ ADC SG_ 423 Sens10CeLft1Quality 150;
BA_REL_ "GenSigTimeoutTime" BU_SG_REL_ ADC SG_ 423 Sens04CeLft2Distance 150;
BA_REL_ "GenSigTimeoutTime" BU_SG_REL_ ADC SG_ 423 Sens05CeLft3Quality 150;
BA_REL_ "GenSigTimeoutTime" BU_SG_REL_ ADC SG_ 423 Sens03CeLft2Quality 150;
BA_REL_ "GenSigTimeoutTime" BU_SG_REL_ ADC SG_ 423 Sens03CeLft1Quality 150;
BA_REL_ "GenSigTimeoutTime" BU_SG_REL_ ADC SG_ 423 Sens12CeLft2Quality 150;
BA_REL_ "GenSigTimeoutTime" BU_SG_REL_ ADC SG_ 423 Sens01CeLft2Quality 150;
BA_REL_ "GenSigTimeoutTime" BU_SG_REL_ ADC SG_ 423 Sens11CeLft2Quality 150;
BA_REL_ "GenSigTimeoutTime" BU_SG_REL_ ADC SG_ 423 Sens05CeLft1Distance 150;
BA_REL_ "GenSigTimeoutTime" BU_SG_REL_ ADC SG_ 423 Sens06CeLft2Quality 150;
BA_REL_ "GenSigTimeoutTime" BU_SG_REL_ ADC SG_ 423 Sens08CeLft1Distance 150;
BA_REL_ "GenSigTimeoutTime" BU_SG_REL_ ADC SG_ 423 Sens03CeLft2Distance 150;
BA_REL_ "GenSigTimeoutTime" BU_SG_REL_ ADC SG_ 423 Sens10CeLft1Distance 150;
BA_REL_ "GenSigTimeoutTime" BU_SG_REL_ ADC SG_ 423 Sens07CeLft3Distance 150;
BA_REL_ "GenSigTimeoutTime" BU_SG_REL_ ADC SG_ 423 Sens10CeLft2Distance 150;
BA_REL_ "GenSigTimeoutTime" BU_SG_REL_ ADC SG_ 423 Sens11CeLft3Distance 150;
BA_REL_ "GenSigTimeoutTime" BU_SG_REL_ ADC SG_ 423 Sens09CeLft1Distance 150;
BA_REL_ "GenSigTimeoutTime" BU_SG_REL_ ADC SG_ 423 Sens02CeLft3Quality 150;
BA_REL_ "GenSigTimeoutTime" BU_SG_REL_ ADC SG_ 423 Sens06CeLft1Distance 150;
BA_REL_ "GenSigTimeoutTime" BU_SG_REL_ ADC SG_ 423 Sens04CeLft3Distance 150;
BA_REL_ "GenSigTimeoutTime" BU_SG_REL_ ADC SG_ 423 Sens08CeLft3Quality 150;
BA_REL_ "GenSigTimeoutTime" BU_SG_REL_ ADC SG_ 423 CeLftMsgChecksum 150;
BA_REL_ "GenSigTimeoutTime" BU_SG_REL_ ADC SG_ 423 Sens08CeLft2Quality 150;
BA_REL_ "GenSigTimeoutTime" BU_SG_REL_ ADC SG_ 423 Sens04CeLft3Quality 150;
BA_REL_ "GenSigTimeoutTime" BU_SG_REL_ ADC SG_ 423 Sens07CeLft3Quality 150;
BA_REL_ "GenSigTimeoutTime" BU_SG_REL_ ADC SG_ 423 Sens09CeLft2Distance 150;
BA_REL_ "GenSigTimeoutTime" BU_SG_REL_ ADC SG_ 423 Sens11CeLft3Quality 150;
BA_REL_ "GenSigTimeoutTime" BU_SG_REL_ ADC SG_ 423 Sens10CeLft3Distance 150;
BA_REL_ "GenSigTimeoutTime" BU_SG_REL_ ADC SG_ 423 CeLftMsgCounter 150;
BA_REL_ "GenSigTimeoutTime" BU_SG_REL_ ADC SG_ 423 Sens08CeLft2Distance 150;
BA_REL_ "GenSigTimeoutTime" BU_SG_REL_ ADC SG_ 423 Sens06CeLft3Quality 150;
BA_REL_ "GenSigTimeoutTime" BU_SG_REL_ ADC SG_ 423 Sens09CeLft3Distance 150;
BA_REL_ "GenSigTimeoutTime" BU_SG_REL_ ADC SG_ 423 Sens01CeLft1Quality 150;
BA_REL_ "GenSigTimeoutTime" BU_SG_REL_ ADC SG_ 423 Sens09CeLft2Quality 150;
BA_REL_ "GenSigTimeoutTime" BU_SG_REL_ ADC SG_ 423 Sens10CeLft3Quality 150;
BA_REL_ "GenSigTimeoutTime" BU_SG_REL_ ADC SG_ 423 Sens05CeLft2Quality 150;
BA_REL_ "GenSigTimeoutTime" BU_SG_REL_ ADC SG_ 423 Sens01CeLft3Quality 150;
BA_REL_ "GenSigTimeoutTime" BU_SG_REL_ ADC SG_ 423 Sens06CeLft3Distance 150;
BA_REL_ "GenSigTimeoutTime" BU_SG_REL_ ADC SG_ 423 Sens07CeLft2Distance 150;
BA_REL_ "GenSigTimeoutTime" BU_SG_REL_ ADC SG_ 423 Sens02CeLft2Quality 150;
BA_REL_ "GenSigTimeoutTime" BU_SG_REL_ ADC SG_ 423 Sens07CeLft1Distance 150;
BA_REL_ "GenSigTimeoutTime" BU_SG_REL_ ADC SG_ 423 Sens01CeLft2Distance 150;
BA_REL_ "GenSigTimeoutTime" BU_SG_REL_ ADC SG_ 423 Sens07CeLft1Quality 150;
BA_REL_ "GenSigTimeoutTime" BU_SG_REL_ ADC SG_ 423 Sens12CeLft2Distance 150;
BA_REL_ "GenSigTimeoutTime" BU_SG_REL_ ADC SG_ 423 Sens11CeLft2Distance 150;
BA_REL_ "GenSigTimeoutTime" BU_SG_REL_ ADC SG_ 423 Sens09CeLft3Quality 150;
BA_REL_ "GenSigTimeoutTime" BU_SG_REL_ ADC SG_ 423 Sens05CeLft2Distance 150;
BA_REL_ "GenSigTimeoutTime" BU_SG_REL_ ADC SG_ 423 Sens07CeLft2Quality 150;
BA_REL_ "GenSigTimeoutTime" BU_SG_REL_ ADC SG_ 423 Sens03CeLft1Distance 150;
BA_REL_ "GenSigTimeoutTime" BU_SG_REL_ ADC SG_ 423 Sens03CeLft3Distance 150;
BA_REL_ "GenSigTimeoutTime" BU_SG_REL_ ADC SG_ 423 Sens01CeLft3Distance 150;
BA_REL_ "GenSigTimeoutTime" BU_SG_REL_ ADC SG_ 423 Sens04CeLft2Quality 150;
BA_REL_ "GenSigTimeoutTime" BU_SG_REL_ ADC SG_ 423 Sens12CeLft1Quality 150;
BA_REL_ "GenSigTimeoutTime" BU_SG_REL_ ADC SG_ 423 Sens04CeLft1Distance 150;
BA_REL_ "GenSigTimeoutTime" BU_SG_REL_ ADC SG_ 423 Sens02CeLft1Quality 150;
BA_REL_ "GenSigTimeoutTime" BU_SG_REL_ ADC SG_ 423 Sens12CeLft3Distance 150;
BA_REL_ "GenSigTimeoutTime" BU_SG_REL_ ADC SG_ 423 Sens09CeLft1Quality 150;
BA_REL_ "GenSigTimeoutTime" BU_SG_REL_ ADC SG_ 423 Sens06CeLft2Distance 150;
BA_REL_ "GenSigTimeoutTime" BU_SG_REL_ ADC SG_ 423 Sens11CeLft1Quality 150;
BA_REL_ "GenSigTimeoutTime" BU_SG_REL_ ADC SG_ 423 Sens10CeLft2Quality 150;
BA_REL_ "GenSigTimeoutTime" BU_SG_REL_ ADC SG_ 423 Sens12CeLft1Distance 150;
BA_REL_ "GenSigTimeoutTime" BU_SG_REL_ ADC SG_ 423 Sens11CeLft1Distance 150;
BA_REL_ "GenSigTimeoutTime" BU_SG_REL_ ADC SG_ 423 Sens05CeLft1Quality 150;
BA_REL_ "GenSigTimeoutTime" BU_SG_REL_ ADC SG_ 423 CeLftMsgSensorIdx 150;
BA_REL_ "GenSigTimeoutTime" BU_SG_REL_ ADC SG_ 423 Sens06CeLft1Quality 150;
BA_REL_ "GenSigTimeoutTime" BU_SG_REL_ ADC SG_ 423 Sens02CeLft2Distance 150;
BA_REL_ "GenSigTimeoutTime" BU_SG_REL_ ADC SG_ 423 Sens12CeLft3Quality 150;
BA_REL_ "GenSigTimeoutTime" BU_SG_REL_ ADC SG_ 423 Sens08CeLft1Quality 150;
BA_REL_ "GenSigTimeoutTime" BU_SG_REL_ ADC SG_ 423 Sens04CeLft1Quality 150;
BA_REL_ "GenSigTimeoutTime" BU_SG_REL_ ADC SG_ 423 Sens05CeLft3Distance 150;
BA_REL_ "GenSigTimeoutTime" BU_SG_REL_ ADC SG_ 423 Sens02CeLft3Distance 150;
BA_REL_ "GenSigTimeoutTime" BU_SG_REL_ ADC SG_ 423 Sens08CeLft3Distance 150;
BA_REL_ "GenSigTimeoutTime" BU_SG_REL_ ADC SG_ 357 MapObj19P1Y 150;
BA_REL_ "GenSigTimeoutTime" BU_SG_REL_ ADC SG_ 357 MapObj09Problty 150;
BA_REL_ "GenSigTimeoutTime" BU_SG_REL_ ADC SG_ 357 MapObj09P1Y 150;
BA_REL_ "GenSigTimeoutTime" BU_SG_REL_ ADC SG_ 357 MapObj09P1X 150;
BA_REL_ "GenSigTimeoutTime" BU_SG_REL_ ADC SG_ 357 MapObj19Problty 150;
BA_REL_ "GenSigTimeoutTime" BU_SG_REL_ ADC SG_ 357 MapObj09P2X 150;
BA_REL_ "GenSigTimeoutTime" BU_SG_REL_ ADC SG_ 357 APA_ADC_10_MsgCntr 150;
BA_REL_ "GenSigTimeoutTime" BU_SG_REL_ ADC SG_ 357 MapObj19P2X 150;
BA_REL_ "GenSigTimeoutTime" BU_SG_REL_ ADC SG_ 357 MapObj19Typ 150;
BA_REL_ "GenSigTimeoutTime" BU_SG_REL_ ADC SG_ 357 MapObj09HeiProblty 150;
BA_REL_ "GenSigTimeoutTime" BU_SG_REL_ ADC SG_ 357 MapObj09Hei 150;
BA_REL_ "GenSigTimeoutTime" BU_SG_REL_ ADC SG_ 357 MapObj09P2Y 150;
BA_REL_ "GenSigTimeoutTime" BU_SG_REL_ ADC SG_ 357 MapObj09Typ 150;
BA_REL_ "GenSigTimeoutTime" BU_SG_REL_ ADC SG_ 357 MapObj19P2Y 150;
BA_REL_ "GenSigTimeoutTime" BU_SG_REL_ ADC SG_ 357 MapObjX9Offs 150;
BA_REL_ "GenSigTimeoutTime" BU_SG_REL_ ADC SG_ 357 APA_ADC_10_CRC 150;
BA_REL_ "GenSigTimeoutTime" BU_SG_REL_ ADC SG_ 357 MapObj19HeiProblty 150;
BA_REL_ "GenSigTimeoutTime" BU_SG_REL_ ADC SG_ 357 MapObj19Hei 150;
BA_REL_ "GenSigTimeoutTime" BU_SG_REL_ ADC SG_ 357 MapObj19P1X 150;
BA_REL_ "GenSigTimeoutTime" BU_SG_REL_ ADC SG_ 356 MapObj08P1X 150;
BA_REL_ "GenSigTimeoutTime" BU_SG_REL_ ADC SG_ 356 MapObj08P2Y 150;
BA_REL_ "GenSigTimeoutTime" BU_SG_REL_ ADC SG_ 356 APA_ADC_09_MsgCntr 150;
BA_REL_ "GenSigTimeoutTime" BU_SG_REL_ ADC SG_ 356 MapObj08Hei 150;
BA_REL_ "GenSigTimeoutTime" BU_SG_REL_ ADC SG_ 356 MapObjX8Offs 150;
BA_REL_ "GenSigTimeoutTime" BU_SG_REL_ ADC SG_ 356 MapObj08HeiProblty 150;
BA_REL_ "GenSigTimeoutTime" BU_SG_REL_ ADC SG_ 356 MapObj18Hei 150;
BA_REL_ "GenSigTimeoutTime" BU_SG_REL_ ADC SG_ 356 MapObj18P2X 150;
BA_REL_ "GenSigTimeoutTime" BU_SG_REL_ ADC SG_ 356 MapObj08P2X 150;
BA_REL_ "GenSigTimeoutTime" BU_SG_REL_ ADC SG_ 356 MapObj08P1Y 150;
BA_REL_ "GenSigTimeoutTime" BU_SG_REL_ ADC SG_ 356 MapObj18HeiProblty 150;
BA_REL_ "GenSigTimeoutTime" BU_SG_REL_ ADC SG_ 356 MapObj08Typ 150;
BA_REL_ "GenSigTimeoutTime" BU_SG_REL_ ADC SG_ 356 MapObj08Problty 150;
BA_REL_ "GenSigTimeoutTime" BU_SG_REL_ ADC SG_ 356 MapObj18Typ 150;
BA_REL_ "GenSigTimeoutTime" BU_SG_REL_ ADC SG_ 356 MapObj18P1X 150;
BA_REL_ "GenSigTimeoutTime" BU_SG_REL_ ADC SG_ 356 APA_ADC_09_CRC 150;
BA_REL_ "GenSigTimeoutTime" BU_SG_REL_ ADC SG_ 356 MapObj18Problty 150;
BA_REL_ "GenSigTimeoutTime" BU_SG_REL_ ADC SG_ 356 MapObj18P1Y 150;
BA_REL_ "GenSigTimeoutTime" BU_SG_REL_ ADC SG_ 356 MapObj18P2Y 150;
BA_REL_ "GenSigTimeoutTime" BU_SG_REL_ ADC SG_ 355 MapObj17HeiProblty 150;
BA_REL_ "GenSigTimeoutTime" BU_SG_REL_ ADC SG_ 355 MapObj17Problty 150;
BA_REL_ "GenSigTimeoutTime" BU_SG_REL_ ADC SG_ 355 MapObj07P2X 150;
BA_REL_ "GenSigTimeoutTime" BU_SG_REL_ ADC SG_ 355 APA_ADC_08_CRC 150;
BA_REL_ "GenSigTimeoutTime" BU_SG_REL_ ADC SG_ 355 MapObj07P1X 150;
BA_REL_ "GenSigTimeoutTime" BU_SG_REL_ ADC SG_ 355 MapObj07P1Y 150;
BA_REL_ "GenSigTimeoutTime" BU_SG_REL_ ADC SG_ 355 MapObj07Problty 150;
BA_REL_ "GenSigTimeoutTime" BU_SG_REL_ ADC SG_ 355 APA_ADC_08_MsgCntr 150;
BA_REL_ "GenSigTimeoutTime" BU_SG_REL_ ADC SG_ 355 MapObj07Typ 150;
BA_REL_ "GenSigTimeoutTime" BU_SG_REL_ ADC SG_ 355 MapObj17Typ 150;
BA_REL_ "GenSigTimeoutTime" BU_SG_REL_ ADC SG_ 355 MapObj07HeiProblty 150;
BA_REL_ "GenSigTimeoutTime" BU_SG_REL_ ADC SG_ 355 MapObj07Hei 150;
BA_REL_ "GenSigTimeoutTime" BU_SG_REL_ ADC SG_ 355 MapObj17P2X 150;
BA_REL_ "GenSigTimeoutTime" BU_SG_REL_ ADC SG_ 355 MapObj17P2Y 150;
BA_REL_ "GenSigTimeoutTime" BU_SG_REL_ ADC SG_ 355 MapObj07P2Y 150;
BA_REL_ "GenSigTimeoutTime" BU_SG_REL_ ADC SG_ 355 MapObjX7Offs 150;
BA_REL_ "GenSigTimeoutTime" BU_SG_REL_ ADC SG_ 355 MapObj17P1Y 150;
BA_REL_ "GenSigTimeoutTime" BU_SG_REL_ ADC SG_ 355 MapObj17P1X 150;
BA_REL_ "GenSigTimeoutTime" BU_SG_REL_ ADC SG_ 355 MapObj17Hei 150;
BA_REL_ "GenSigTimeoutTime" BU_SG_REL_ ADC SG_ 354 APA_ADC_07_MsgCntr 150;
BA_REL_ "GenSigTimeoutTime" BU_SG_REL_ ADC SG_ 354 MapObj16P2X 150;
BA_REL_ "GenSigTimeoutTime" BU_SG_REL_ ADC SG_ 354 MapObj06Typ 150;
BA_REL_ "GenSigTimeoutTime" BU_SG_REL_ ADC SG_ 354 MapObj06Hei 150;
BA_REL_ "GenSigTimeoutTime" BU_SG_REL_ ADC SG_ 354 MapObj16P2Y 150;
BA_REL_ "GenSigTimeoutTime" BU_SG_REL_ ADC SG_ 354 MapObj16Problty 150;
BA_REL_ "GenSigTimeoutTime" BU_SG_REL_ ADC SG_ 354 MapObj06P1Y 150;
BA_REL_ "GenSigTimeoutTime" BU_SG_REL_ ADC SG_ 354 MapObj16P1Y 150;
BA_REL_ "GenSigTimeoutTime" BU_SG_REL_ ADC SG_ 354 MapObj06HeiProblty 150;
BA_REL_ "GenSigTimeoutTime" BU_SG_REL_ ADC SG_ 354 MapObj16Hei 150;
BA_REL_ "GenSigTimeoutTime" BU_SG_REL_ ADC SG_ 354 MapObj06Problty 150;
BA_REL_ "GenSigTimeoutTime" BU_SG_REL_ ADC SG_ 354 MapObj06P1X 150;
BA_REL_ "GenSigTimeoutTime" BU_SG_REL_ ADC SG_ 354 MapObj16P1X 150;
BA_REL_ "GenSigTimeoutTime" BU_SG_REL_ ADC SG_ 354 MapObj06P2X 150;
BA_REL_ "GenSigTimeoutTime" BU_SG_REL_ ADC SG_ 354 MapObj16Typ 150;
BA_REL_ "GenSigTimeoutTime" BU_SG_REL_ ADC SG_ 354 MapObj16HeiProblty 150;
BA_REL_ "GenSigTimeoutTime" BU_SG_REL_ ADC SG_ 354 MapObjX6Offs 150;
BA_REL_ "GenSigTimeoutTime" BU_SG_REL_ ADC SG_ 354 APA_ADC_07_CRC 150;
BA_REL_ "GenSigTimeoutTime" BU_SG_REL_ ADC SG_ 354 MapObj06P2Y 150;
BA_REL_ "GenSigTimeoutTime" BU_SG_REL_ ADC SG_ 353 MapObjX5Offs 150;
BA_REL_ "GenSigTimeoutTime" BU_SG_REL_ ADC SG_ 353 MapObj15Hei 150;
BA_REL_ "GenSigTimeoutTime" BU_SG_REL_ ADC SG_ 353 MapObj15Problty 150;
BA_REL_ "GenSigTimeoutTime" BU_SG_REL_ ADC SG_ 353 MapObj15Typ 150;
BA_REL_ "GenSigTimeoutTime" BU_SG_REL_ ADC SG_ 353 MapObj15HeiProblty 150;
BA_REL_ "GenSigTimeoutTime" BU_SG_REL_ ADC SG_ 353 MapObj15P1Y 150;
BA_REL_ "GenSigTimeoutTime" BU_SG_REL_ ADC SG_ 353 MapObj05P1Y 150;
BA_REL_ "GenSigTimeoutTime" BU_SG_REL_ ADC SG_ 353 MapObj05P1X 150;
BA_REL_ "GenSigTimeoutTime" BU_SG_REL_ ADC SG_ 353 MapObj05Typ 150;
BA_REL_ "GenSigTimeoutTime" BU_SG_REL_ ADC SG_ 353 APA_ADC_06_MsgCntr 150;
BA_REL_ "GenSigTimeoutTime" BU_SG_REL_ ADC SG_ 353 MapObj05Problty 150;
BA_REL_ "GenSigTimeoutTime" BU_SG_REL_ ADC SG_ 353 MapObj05Hei 150;
BA_REL_ "GenSigTimeoutTime" BU_SG_REL_ ADC SG_ 353 MapObj15P2Y 150;
BA_REL_ "GenSigTimeoutTime" BU_SG_REL_ ADC SG_ 353 APA_ADC_06_CRC 150;
BA_REL_ "GenSigTimeoutTime" BU_SG_REL_ ADC SG_ 353 MapObj15P2X 150;
BA_REL_ "GenSigTimeoutTime" BU_SG_REL_ ADC SG_ 353 MapObj05P2X 150;
BA_REL_ "GenSigTimeoutTime" BU_SG_REL_ ADC SG_ 353 MapObj15P1X 150;
BA_REL_ "GenSigTimeoutTime" BU_SG_REL_ ADC SG_ 353 MapObj05P2Y 150;
BA_REL_ "GenSigTimeoutTime" BU_SG_REL_ ADC SG_ 353 MapObj05HeiProblty 150;
BA_REL_ "GenSigTimeoutTime" BU_SG_REL_ ADC SG_ 352 MapObj14Problty 150;
BA_REL_ "GenSigTimeoutTime" BU_SG_REL_ ADC SG_ 352 MapObj04Problty 150;
BA_REL_ "GenSigTimeoutTime" BU_SG_REL_ ADC SG_ 352 MapObj04P1Y 150;
BA_REL_ "GenSigTimeoutTime" BU_SG_REL_ ADC SG_ 352 MapObj04Typ 150;
BA_REL_ "GenSigTimeoutTime" BU_SG_REL_ ADC SG_ 352 MapObj14P1Y 150;
BA_REL_ "GenSigTimeoutTime" BU_SG_REL_ ADC SG_ 352 MapObj14Typ 150;
BA_REL_ "GenSigTimeoutTime" BU_SG_REL_ ADC SG_ 352 MapObj04Hei 150;
BA_REL_ "GenSigTimeoutTime" BU_SG_REL_ ADC SG_ 352 MapObj14P2Y 150;
BA_REL_ "GenSigTimeoutTime" BU_SG_REL_ ADC SG_ 352 MapObj14P1X 150;
BA_REL_ "GenSigTimeoutTime" BU_SG_REL_ ADC SG_ 352 MapObj04P1X 150;
BA_REL_ "GenSigTimeoutTime" BU_SG_REL_ ADC SG_ 352 MapObj14P2X 150;
BA_REL_ "GenSigTimeoutTime" BU_SG_REL_ ADC SG_ 352 APA_ADC_05_CRC 150;
BA_REL_ "GenSigTimeoutTime" BU_SG_REL_ ADC SG_ 352 MapObjX4Offs 150;
BA_REL_ "GenSigTimeoutTime" BU_SG_REL_ ADC SG_ 352 MapObj14Hei 150;
BA_REL_ "GenSigTimeoutTime" BU_SG_REL_ ADC SG_ 352 APA_ADC_05_MsgCntr 150;
BA_REL_ "GenSigTimeoutTime" BU_SG_REL_ ADC SG_ 352 MapObj04P2Y 150;
BA_REL_ "GenSigTimeoutTime" BU_SG_REL_ ADC SG_ 352 MapObj04P2X 150;
BA_REL_ "GenSigTimeoutTime" BU_SG_REL_ ADC SG_ 352 MapObj04HeiProblty 150;
BA_REL_ "GenSigTimeoutTime" BU_SG_REL_ ADC SG_ 352 MapObj14HeiProblty 150;
BA_REL_ "GenSigTimeoutTime" BU_SG_REL_ ADC SG_ 351 MapObj13P1X 150;
BA_REL_ "GenSigTimeoutTime" BU_SG_REL_ ADC SG_ 351 MapObjX3Offs 150;
BA_REL_ "GenSigTimeoutTime" BU_SG_REL_ ADC SG_ 351 APA_ADC_04_CRC 150;
BA_REL_ "GenSigTimeoutTime" BU_SG_REL_ ADC SG_ 351 MapObj13P1Y 150;
BA_REL_ "GenSigTimeoutTime" BU_SG_REL_ ADC SG_ 351 MapObj13HeiProblty 150;
BA_REL_ "GenSigTimeoutTime" BU_SG_REL_ ADC SG_ 351 MapObj03P2X 150;
BA_REL_ "GenSigTimeoutTime" BU_SG_REL_ ADC SG_ 351 MapObj03P2Y 150;
BA_REL_ "GenSigTimeoutTime" BU_SG_REL_ ADC SG_ 351 APA_ADC_04_MsgCntr 150;
BA_REL_ "GenSigTimeoutTime" BU_SG_REL_ ADC SG_ 351 MapObj13Problty 150;
BA_REL_ "GenSigTimeoutTime" BU_SG_REL_ ADC SG_ 351 MapObj03Problty 150;
BA_REL_ "GenSigTimeoutTime" BU_SG_REL_ ADC SG_ 351 MapObj13Hei 150;
BA_REL_ "GenSigTimeoutTime" BU_SG_REL_ ADC SG_ 351 MapObj03P1Y 150;
BA_REL_ "GenSigTimeoutTime" BU_SG_REL_ ADC SG_ 351 MapObj13Typ 150;
BA_REL_ "GenSigTimeoutTime" BU_SG_REL_ ADC SG_ 351 MapObj03P1X 150;
BA_REL_ "GenSigTimeoutTime" BU_SG_REL_ ADC SG_ 351 MapObj13P2Y 150;
BA_REL_ "GenSigTimeoutTime" BU_SG_REL_ ADC SG_ 351 MapObj03Hei 150;
BA_REL_ "GenSigTimeoutTime" BU_SG_REL_ ADC SG_ 351 MapObj13P2X 150;
BA_REL_ "GenSigTimeoutTime" BU_SG_REL_ ADC SG_ 351 MapObj03Typ 150;
BA_REL_ "GenSigTimeoutTime" BU_SG_REL_ ADC SG_ 351 MapObj03HeiProblty 150;
BA_REL_ "GenSigTimeoutTime" BU_SG_REL_ ADC SG_ 350 MapObj02P2Y 150;
BA_REL_ "GenSigTimeoutTime" BU_SG_REL_ ADC SG_ 350 MapObj02Typ 150;
BA_REL_ "GenSigTimeoutTime" BU_SG_REL_ ADC SG_ 350 MapObj02P2X 150;
BA_REL_ "GenSigTimeoutTime" BU_SG_REL_ ADC SG_ 350 MapObj12P2Y 150;
BA_REL_ "GenSigTimeoutTime" BU_SG_REL_ ADC SG_ 350 MapObj12P2X 150;
BA_REL_ "GenSigTimeoutTime" BU_SG_REL_ ADC SG_ 350 MapObj12Hei 150;
BA_REL_ "GenSigTimeoutTime" BU_SG_REL_ ADC SG_ 350 MapObj02HeiProblty 150;
BA_REL_ "GenSigTimeoutTime" BU_SG_REL_ ADC SG_ 350 MapObj12P1Y 150;
BA_REL_ "GenSigTimeoutTime" BU_SG_REL_ ADC SG_ 350 MapObj12Problty 150;
BA_REL_ "GenSigTimeoutTime" BU_SG_REL_ ADC SG_ 350 MapObj02Problty 150;
BA_REL_ "GenSigTimeoutTime" BU_SG_REL_ ADC SG_ 350 MapObj12HeiProblty 150;
BA_REL_ "GenSigTimeoutTime" BU_SG_REL_ ADC SG_ 350 APA_ADC_03_CRC 150;
BA_REL_ "GenSigTimeoutTime" BU_SG_REL_ ADC SG_ 350 MapObj02P1Y 150;
BA_REL_ "GenSigTimeoutTime" BU_SG_REL_ ADC SG_ 350 MapObj02Hei 150;
BA_REL_ "GenSigTimeoutTime" BU_SG_REL_ ADC SG_ 350 MapObj02P1X 150;
BA_REL_ "GenSigTimeoutTime" BU_SG_REL_ ADC SG_ 350 APA_ADC_03_MsgCntr 150;
BA_REL_ "GenSigTimeoutTime" BU_SG_REL_ ADC SG_ 350 MapObj12P1X 150;
BA_REL_ "GenSigTimeoutTime" BU_SG_REL_ ADC SG_ 350 MapObjX2Offs 150;
BA_REL_ "GenSigTimeoutTime" BU_SG_REL_ ADC SG_ 350 MapObj12Typ 150;
BA_REL_ "GenSigTimeoutTime" BU_SG_REL_ ADC SG_ 349 MapObj01Hei 150;
BA_REL_ "GenSigTimeoutTime" BU_SG_REL_ ADC SG_ 349 MapObj01P1Y 150;
BA_REL_ "GenSigTimeoutTime" BU_SG_REL_ ADC SG_ 349 MapObj11P1Y 150;
BA_REL_ "GenSigTimeoutTime" BU_SG_REL_ ADC SG_ 349 MapObj01P1X 150;
BA_REL_ "GenSigTimeoutTime" BU_SG_REL_ ADC SG_ 349 MapObj11P2Y 150;
BA_REL_ "GenSigTimeoutTime" BU_SG_REL_ ADC SG_ 349 MapObj11Hei 150;
BA_REL_ "GenSigTimeoutTime" BU_SG_REL_ ADC SG_ 349 MapObj11P1X 150;
BA_REL_ "GenSigTimeoutTime" BU_SG_REL_ ADC SG_ 349 APA_ADC_02_MsgCntr 150;
BA_REL_ "GenSigTimeoutTime" BU_SG_REL_ ADC SG_ 349 MapObj11Problty 150;
BA_REL_ "GenSigTimeoutTime" BU_SG_REL_ ADC SG_ 349 APA_ADC_02_CRC 150;
BA_REL_ "GenSigTimeoutTime" BU_SG_REL_ ADC SG_ 349 MapObj01Problty 150;
BA_REL_ "GenSigTimeoutTime" BU_SG_REL_ ADC SG_ 349 MapObj11P2X 150;
BA_REL_ "GenSigTimeoutTime" BU_SG_REL_ ADC SG_ 349 MapObj11Typ 150;
BA_REL_ "GenSigTimeoutTime" BU_SG_REL_ ADC SG_ 349 MapObj01HeiProblty 150;
BA_REL_ "GenSigTimeoutTime" BU_SG_REL_ ADC SG_ 349 MapObjX1Offs 150;
BA_REL_ "GenSigTimeoutTime" BU_SG_REL_ ADC SG_ 349 MapObj11HeiProblty 150;
BA_REL_ "GenSigTimeoutTime" BU_SG_REL_ ADC SG_ 349 MapObj01Typ 150;
BA_REL_ "GenSigTimeoutTime" BU_SG_REL_ ADC SG_ 349 MapObj01P2X 150;
BA_REL_ "GenSigTimeoutTime" BU_SG_REL_ ADC SG_ 349 MapObj01P2Y 150;
BA_REL_ "GenSigTimeoutTime" BU_SG_REL_ ADC SG_ 348 MapObj10P2Y 150;
BA_REL_ "GenSigTimeoutTime" BU_SG_REL_ ADC SG_ 348 APA_ADC_01_MsgCntr 150;
BA_REL_ "GenSigTimeoutTime" BU_SG_REL_ ADC SG_ 348 MapObj10Problty 150;
BA_REL_ "GenSigTimeoutTime" BU_SG_REL_ ADC SG_ 348 MapObj00Problty 150;
BA_REL_ "GenSigTimeoutTime" BU_SG_REL_ ADC SG_ 348 MapObj00P2X 150;
BA_REL_ "GenSigTimeoutTime" BU_SG_REL_ ADC SG_ 348 MapObj10Typ 150;
BA_REL_ "GenSigTimeoutTime" BU_SG_REL_ ADC SG_ 348 MapObj00HeiProblty 150;
BA_REL_ "GenSigTimeoutTime" BU_SG_REL_ ADC SG_ 348 APA_ADC_01_CRC 150;
BA_REL_ "GenSigTimeoutTime" BU_SG_REL_ ADC SG_ 348 MapObj10P2X 150;
BA_REL_ "GenSigTimeoutTime" BU_SG_REL_ ADC SG_ 348 MapObj00P1Y 150;
BA_REL_ "GenSigTimeoutTime" BU_SG_REL_ ADC SG_ 348 MapObj10HeiProblty 150;
BA_REL_ "GenSigTimeoutTime" BU_SG_REL_ ADC SG_ 348 MapObj00Typ 150;
BA_REL_ "GenSigTimeoutTime" BU_SG_REL_ ADC SG_ 348 MapObj10Hei 150;
BA_REL_ "GenSigTimeoutTime" BU_SG_REL_ ADC SG_ 348 MapObjX0Offs 150;
BA_REL_ "GenSigTimeoutTime" BU_SG_REL_ ADC SG_ 348 MapObj10P1Y 150;
BA_REL_ "GenSigTimeoutTime" BU_SG_REL_ ADC SG_ 348 MapObj00P2Y 150;
BA_REL_ "GenSigTimeoutTime" BU_SG_REL_ ADC SG_ 348 MapObj10P1X 150;
BA_REL_ "GenSigTimeoutTime" BU_SG_REL_ ADC SG_ 348 MapObj00Hei 150;
BA_REL_ "GenSigTimeoutTime" BU_SG_REL_ ADC SG_ 348 MapObj00P1X 150;
BA_REL_ "GenSigTimeoutTime" BU_SG_REL_ CGW SG_ 648 ApaPscSlotCrossRiVehY 3500;
BA_REL_ "GenSigTimeoutTime" BU_SG_REL_ ADC SG_ 648 ApaPscSlotCrossRiVehY 500;
BA_REL_ "GenSigTimeoutTime" BU_SG_REL_ CGW SG_ 648 ApaXSlotYVehX 3500;
BA_REL_ "GenSigTimeoutTime" BU_SG_REL_ ADC SG_ 648 ApaXSlotYVehX 500;
BA_REL_ "GenSigTimeoutTime" BU_SG_REL_ CGW SG_ 648 ApaPocSlotParallelRiVehY 3500;
BA_REL_ "GenSigTimeoutTime" BU_SG_REL_ ADC SG_ 648 ApaPocSlotParallelRiVehY 500;
BA_REL_ "GenSigTimeoutTime" BU_SG_REL_ ADC SG_ 648 ApaPocSlotParallelLeSizeY 500;
BA_REL_ "GenSigTimeoutTime" BU_SG_REL_ CGW SG_ 648 ApaPocSlotParallelLeSizeY 3500;
BA_REL_ "GenSigTimeoutTime" BU_SG_REL_ CGW SG_ 648 ApaPscSlotCrossLeVehX 3500;
BA_REL_ "GenSigTimeoutTime" BU_SG_REL_ ADC SG_ 648 ApaPscSlotCrossLeVehX 500;
BA_REL_ "GenSigTimeoutTime" BU_SG_REL_ ADC SG_ 648 ApaXSlotYSizeX 500;
BA_REL_ "GenSigTimeoutTime" BU_SG_REL_ CGW SG_ 648 ApaXSlotYSizeX 3500;
BA_REL_ "GenSigTimeoutTime" BU_SG_REL_ CGW SG_ 648 ApaPscSlotCrossRiVehPsi 3500;
BA_REL_ "GenSigTimeoutTime" BU_SG_REL_ ADC SG_ 648 ApaPscSlotCrossRiVehPsi 500;
BA_REL_ "GenSigTimeoutTime" BU_SG_REL_ ADC SG_ 648 ApaPocSlotParallelRiVehPsi 500;
BA_REL_ "GenSigTimeoutTime" BU_SG_REL_ CGW SG_ 648 ApaPocSlotParallelRiVehPsi 3500;
BA_REL_ "GenSigTimeoutTime" BU_SG_REL_ ADC SG_ 648 ApaPocSlotParallelRiSizeX 500;
BA_REL_ "GenSigTimeoutTime" BU_SG_REL_ CGW SG_ 648 ApaPocSlotParallelRiSizeX 3500;
BA_REL_ "GenSigTimeoutTime" BU_SG_REL_ ADC SG_ 648 ApaPocSlotParallelRiSizeY 500;
BA_REL_ "GenSigTimeoutTime" BU_SG_REL_ CGW SG_ 648 ApaPocSlotParallelRiSizeY 3500;
BA_REL_ "GenSigTimeoutTime" BU_SG_REL_ CGW SG_ 648 ApaPscSlotCrossRiSizeY 3500;
BA_REL_ "GenSigTimeoutTime" BU_SG_REL_ ADC SG_ 648 ApaPscSlotCrossRiSizeY 500;
BA_REL_ "GenSigTimeoutTime" BU_SG_REL_ ADC SG_ 648 ApaPscSlotParallelRiVehX 500;
BA_REL_ "GenSigTimeoutTime" BU_SG_REL_ CGW SG_ 648 ApaPscSlotParallelRiVehX 3500;
BA_REL_ "GenSigTimeoutTime" BU_SG_REL_ ADC SG_ 648 ApaPscSlotParallelLeVehPsi 500;
BA_REL_ "GenSigTimeoutTime" BU_SG_REL_ CGW SG_ 648 ApaPscSlotParallelLeVehPsi 3500;
BA_REL_ "GenSigTimeoutTime" BU_SG_REL_ CGW SG_ 648 ApaPocSlotParallelLeVehY 3500;
BA_REL_ "GenSigTimeoutTime" BU_SG_REL_ ADC SG_ 648 ApaPocSlotParallelLeVehY 500;
BA_REL_ "GenSigTimeoutTime" BU_SG_REL_ CGW SG_ 648 ApaXSlotYSizeY 3500;
BA_REL_ "GenSigTimeoutTime" BU_SG_REL_ ADC SG_ 648 ApaXSlotYSizeY 500;
BA_REL_ "GenSigTimeoutTime" BU_SG_REL_ ADC SG_ 648 ApaXSlotYVehPsi 500;
BA_REL_ "GenSigTimeoutTime" BU_SG_REL_ CGW SG_ 648 ApaXSlotYVehPsi 3500;
BA_REL_ "GenSigTimeoutTime" BU_SG_REL_ ADC SG_ 648 ApaPscSlotParallelRiSizeX 500;
BA_REL_ "GenSigTimeoutTime" BU_SG_REL_ CGW SG_ 648 ApaPscSlotParallelRiSizeX 3500;
BA_REL_ "GenSigTimeoutTime" BU_SG_REL_ ADC SG_ 648 ApaPscSlotParallelLeVehY 500;
BA_REL_ "GenSigTimeoutTime" BU_SG_REL_ CGW SG_ 648 ApaPscSlotParallelLeVehY 3500;
BA_REL_ "GenSigTimeoutTime" BU_SG_REL_ CGW SG_ 648 ApaPscSlotParallelLeSizeX 3500;
BA_REL_ "GenSigTimeoutTime" BU_SG_REL_ ADC SG_ 648 ApaPscSlotParallelLeSizeX 500;
BA_REL_ "GenSigTimeoutTime" BU_SG_REL_ ADC SG_ 648 ApaPocSlotParallelLeVehPsi 500;
BA_REL_ "GenSigTimeoutTime" BU_SG_REL_ CGW SG_ 648 ApaPocSlotParallelLeVehPsi 3500;
BA_REL_ "GenSigTimeoutTime" BU_SG_REL_ ADC SG_ 648 ApaPscSlotParallelRiSizeY 500;
BA_REL_ "GenSigTimeoutTime" BU_SG_REL_ CGW SG_ 648 ApaPscSlotParallelRiSizeY 3500;
BA_REL_ "GenSigTimeoutTime" BU_SG_REL_ CGW SG_ 648 ApaPocSlotParallelLeSizeX 3500;
BA_REL_ "GenSigTimeoutTime" BU_SG_REL_ ADC SG_ 648 ApaPocSlotParallelLeSizeX 500;
BA_REL_ "GenSigTimeoutTime" BU_SG_REL_ CGW SG_ 648 ApaPscSlotCrossLeVehPsi 3500;
BA_REL_ "GenSigTimeoutTime" BU_SG_REL_ ADC SG_ 648 ApaPscSlotCrossLeVehPsi 500;
BA_REL_ "GenSigTimeoutTime" BU_SG_REL_ ADC SG_ 648 ApaPscSlotCrossRiVehX 500;
BA_REL_ "GenSigTimeoutTime" BU_SG_REL_ CGW SG_ 648 ApaPscSlotCrossRiVehX 3500;
BA_REL_ "GenSigTimeoutTime" BU_SG_REL_ ADC SG_ 648 ApaPscVehSlotTyp 500;
BA_REL_ "GenSigTimeoutTime" BU_SG_REL_ CGW SG_ 648 ApaPscVehSlotTyp 500;
BA_REL_ "GenSigTimeoutTime" BU_SG_REL_ CGW SG_ 648 ApaPocSlotParallelLeVehX 3500;
BA_REL_ "GenSigTimeoutTime" BU_SG_REL_ ADC SG_ 648 ApaPocSlotParallelLeVehX 500;
BA_REL_ "GenSigTimeoutTime" BU_SG_REL_ ADC SG_ 648 ApaPscSlotCrossLeSizeX 500;
BA_REL_ "GenSigTimeoutTime" BU_SG_REL_ CGW SG_ 648 ApaPscSlotCrossLeSizeX 3500;
BA_REL_ "GenSigTimeoutTime" BU_SG_REL_ ADC SG_ 648 ApaPscSlotParallelLeSizeY 500;
BA_REL_ "GenSigTimeoutTime" BU_SG_REL_ CGW SG_ 648 ApaPscSlotParallelLeSizeY 3500;
BA_REL_ "GenSigTimeoutTime" BU_SG_REL_ ADC SG_ 648 ApaPscSlotParallelLeVehX 500;
BA_REL_ "GenSigTimeoutTime" BU_SG_REL_ CGW SG_ 648 ApaPscSlotParallelLeVehX 3500;
BA_REL_ "GenSigTimeoutTime" BU_SG_REL_ ADC SG_ 648 ApaPscSlotParallelRiVehPsi 500;
BA_REL_ "GenSigTimeoutTime" BU_SG_REL_ CGW SG_ 648 ApaPscSlotParallelRiVehPsi 3500;
BA_REL_ "GenSigTimeoutTime" BU_SG_REL_ ADC SG_ 648 ApaXSlotYVehY 500;
BA_REL_ "GenSigTimeoutTime" BU_SG_REL_ CGW SG_ 648 ApaXSlotYVehY 3500;
BA_REL_ "GenSigTimeoutTime" BU_SG_REL_ ADC SG_ 648 ApaPscSlotParallelRiVehY 500;
BA_REL_ "GenSigTimeoutTime" BU_SG_REL_ CGW SG_ 648 ApaPscSlotParallelRiVehY 3500;
BA_REL_ "GenSigTimeoutTime" BU_SG_REL_ CGW SG_ 648 ApaPscSlotCrossRiSizeX 3500;
BA_REL_ "GenSigTimeoutTime" BU_SG_REL_ ADC SG_ 648 ApaPscSlotCrossRiSizeX 500;
BA_REL_ "GenSigTimeoutTime" BU_SG_REL_ ADC SG_ 648 ApaPscSlotCrossLeVehY 500;
BA_REL_ "GenSigTimeoutTime" BU_SG_REL_ CGW SG_ 648 ApaPscSlotCrossLeVehY 3500;
BA_REL_ "GenSigTimeoutTime" BU_SG_REL_ CGW SG_ 648 ApaPocSlotParallelRiVehX 3500;
BA_REL_ "GenSigTimeoutTime" BU_SG_REL_ ADC SG_ 648 ApaPocSlotParallelRiVehX 500;
BA_REL_ "GenSigTimeoutTime" BU_SG_REL_ ADC SG_ 648 ApaPscSlotCrossLeSizeY 500;
BA_REL_ "GenSigTimeoutTime" BU_SG_REL_ CGW SG_ 648 ApaPscSlotCrossLeSizeY 3500;
BA_REL_ "GenSigTimeoutTime" BU_SG_REL_ ADC SG_ 651 ReLeMidRegnDst 1250;
BA_REL_ "GenSigTimeoutTime" BU_SG_REL_ CGW SG_ 651 ReLeMidRegnDst 500;
BA_REL_ "GenSigTimeoutTime" BU_SG_REL_ CGW SG_ 651 APA_06_CRC 500;
BA_REL_ "GenSigTimeoutTime" BU_SG_REL_ ADC SG_ 651 APA_06_CRC 1250;
BA_REL_ "GenSigTimeoutTime" BU_SG_REL_ ADC SG_ 651 APA_06_MsgCntr 1250;
BA_REL_ "GenSigTimeoutTime" BU_SG_REL_ CGW SG_ 651 APA_06_MsgCntr 500;
BA_REL_ "GenSigTimeoutTime" BU_SG_REL_ CGW SG_ 651 ReLeRegnDst 500;
BA_REL_ "GenSigTimeoutTime" BU_SG_REL_ ADC SG_ 651 ReLeRegnDst 1250;
BA_REL_ "GenSigTimeoutTime" BU_SG_REL_ ADC SG_ 651 ReSnsrFltSt 1250;
BA_REL_ "GenSigTimeoutTime" BU_SG_REL_ CGW SG_ 651 ReSnsrFltSt 500;
BA_REL_ "GenSigTimeoutTime" BU_SG_REL_ CGW SG_ 651 ReRiMidRegnDst 500;
BA_REL_ "GenSigTimeoutTime" BU_SG_REL_ ADC SG_ 651 ReRiMidRegnDst 1250;
BA_REL_ "GenSigTimeoutTime" BU_SG_REL_ ADC SG_ 651 ReRiRegnDst 1250;
BA_REL_ "GenSigTimeoutTime" BU_SG_REL_ CGW SG_ 651 ReRiRegnDst 500;
BA_REL_ "GenSigTimeoutTime" BU_SG_REL_ ADC SG_ 651 ReMidRegnDst 1250;
BA_REL_ "GenSigTimeoutTime" BU_SG_REL_ CGW SG_ 651 ReMidRegnDst 500;
BA_REL_ "GenSigTimeoutTime" BU_SG_REL_ CGW SG_ 651 ReSysSts 500;
BA_REL_ "GenSigTimeoutTime" BU_SG_REL_ ADC SG_ 651 ReSysSts 1250;
BA_REL_ "GenSigTimeoutTime" BU_SG_REL_ ADC SG_ 650 FrntRiRegnDst 1250;
BA_REL_ "GenSigTimeoutTime" BU_SG_REL_ CGW SG_ 650 FrntRiRegnDst 500;
BA_REL_ "GenSigTimeoutTime" BU_SG_REL_ ADC SG_ 650 FrntLeRegnDst 1250;
BA_REL_ "GenSigTimeoutTime" BU_SG_REL_ CGW SG_ 650 FrntLeRegnDst 500;
BA_REL_ "GenSigTimeoutTime" BU_SG_REL_ CGW SG_ 650 FrntSnsrFltSt 500;
BA_REL_ "GenSigTimeoutTime" BU_SG_REL_ ADC SG_ 650 FrntSnsrFltSt 1250;
BA_REL_ "GenSigTimeoutTime" BU_SG_REL_ CGW SG_ 650 FrntMidRegnDst 500;
BA_REL_ "GenSigTimeoutTime" BU_SG_REL_ ADC SG_ 650 FrntMidRegnDst 1250;
BA_REL_ "GenSigTimeoutTime" BU_SG_REL_ ADC SG_ 650 FrntLeMidRegnDst 1250;
BA_REL_ "GenSigTimeoutTime" BU_SG_REL_ CGW SG_ 650 FrntLeMidRegnDst 500;
BA_REL_ "GenSigTimeoutTime" BU_SG_REL_ CGW SG_ 650 APA_05_CRC 500;
BA_REL_ "GenSigTimeoutTime" BU_SG_REL_ ADC SG_ 650 APA_05_CRC 1250;
BA_REL_ "GenSigTimeoutTime" BU_SG_REL_ CGW SG_ 650 APA_05_MsgCntr 500;
BA_REL_ "GenSigTimeoutTime" BU_SG_REL_ ADC SG_ 650 APA_05_MsgCntr 1250;
BA_REL_ "GenSigTimeoutTime" BU_SG_REL_ CGW SG_ 650 FrntRiMidRegnDst 500;
BA_REL_ "GenSigTimeoutTime" BU_SG_REL_ ADC SG_ 650 FrntRiMidRegnDst 1250;
BA_REL_ "GenSigTimeoutTime" BU_SG_REL_ CGW SG_ 650 FrntSysSts 500;
BA_REL_ "GenSigTimeoutTime" BU_SG_REL_ ADC SG_ 650 FrntSysSts 1250;
BA_REL_ "GenSigTimeoutTime" BU_SG_REL_ CGW SG_ 646 ApaPscSlotCrossRiObj2Alpha 3500;
BA_REL_ "GenSigTimeoutTime" BU_SG_REL_ ADC SG_ 646 ApaPscSlotCrossRiObj2Alpha 500;
BA_REL_ "GenSigTimeoutTime" BU_SG_REL_ ADC SG_ 646 ApaXSlotYObj1Y 500;
BA_REL_ "GenSigTimeoutTime" BU_SG_REL_ CGW SG_ 646 ApaXSlotYObj1Y 3500;
BA_REL_ "GenSigTimeoutTime" BU_SG_REL_ ADC SG_ 646 ApaXSlotYObj2Y 500;
BA_REL_ "GenSigTimeoutTime" BU_SG_REL_ CGW SG_ 646 ApaXSlotYObj2Y 3500;
BA_REL_ "GenSigTimeoutTime" BU_SG_REL_ ADC SG_ 646 ApaXSlotYObj2Alpha 500;
BA_REL_ "GenSigTimeoutTime" BU_SG_REL_ CGW SG_ 646 ApaXSlotYObj2Alpha 3500;
BA_REL_ "GenSigTimeoutTime" BU_SG_REL_ ADC SG_ 646 ApaPocSlotParallelLeObj1Y 500;
BA_REL_ "GenSigTimeoutTime" BU_SG_REL_ CGW SG_ 646 ApaPocSlotParallelLeObj1Y 3500;
BA_REL_ "GenSigTimeoutTime" BU_SG_REL_ ADC SG_ 646 ApaPscSlotParallelRiObj2Alpha 500;
BA_REL_ "GenSigTimeoutTime" BU_SG_REL_ CGW SG_ 646 ApaPscSlotParallelRiObj2Alpha 3500;
BA_REL_ "GenSigTimeoutTime" BU_SG_REL_ CGW SG_ 646 ApaPscSlotCrossRiObj1Y 3500;
BA_REL_ "GenSigTimeoutTime" BU_SG_REL_ ADC SG_ 646 ApaPscSlotCrossRiObj1Y 500;
BA_REL_ "GenSigTimeoutTime" BU_SG_REL_ ADC SG_ 646 ApaPscSlotParallelRiObj2X 500;
BA_REL_ "GenSigTimeoutTime" BU_SG_REL_ CGW SG_ 646 ApaPscSlotParallelRiObj2X 3500;
BA_REL_ "GenSigTimeoutTime" BU_SG_REL_ ADC SG_ 646 ApaPscSlotParallelLeObj2X 500;
BA_REL_ "GenSigTimeoutTime" BU_SG_REL_ CGW SG_ 646 ApaPscSlotParallelLeObj2X 3500;
BA_REL_ "GenSigTimeoutTime" BU_SG_REL_ CGW SG_ 646 ApaPocSlotParallelRiObj1X 3500;
BA_REL_ "GenSigTimeoutTime" BU_SG_REL_ ADC SG_ 646 ApaPocSlotParallelRiObj1X 500;
BA_REL_ "GenSigTimeoutTime" BU_SG_REL_ ADC SG_ 646 ApaPocSlotParallelLeObj2Alpha 500;
BA_REL_ "GenSigTimeoutTime" BU_SG_REL_ CGW SG_ 646 ApaPocSlotParallelLeObj2Alpha 3500;
BA_REL_ "GenSigTimeoutTime" BU_SG_REL_ ADC SG_ 646 ApaPocSlotParallelRiObj1Alpha 500;
BA_REL_ "GenSigTimeoutTime" BU_SG_REL_ CGW SG_ 646 ApaPocSlotParallelRiObj1Alpha 3500;
BA_REL_ "GenSigTimeoutTime" BU_SG_REL_ ADC SG_ 646 ApaPscSlotCrossLeObj2Alpha 500;
BA_REL_ "GenSigTimeoutTime" BU_SG_REL_ CGW SG_ 646 ApaPscSlotCrossLeObj2Alpha 3500;
BA_REL_ "GenSigTimeoutTime" BU_SG_REL_ ADC SG_ 646 ApaPscSlotParallelLeObj1X 500;
BA_REL_ "GenSigTimeoutTime" BU_SG_REL_ CGW SG_ 646 ApaPscSlotParallelLeObj1X 3500;
BA_REL_ "GenSigTimeoutTime" BU_SG_REL_ ADC SG_ 646 ApaPscSlotCrossLeObj2Y 500;
BA_REL_ "GenSigTimeoutTime" BU_SG_REL_ CGW SG_ 646 ApaPscSlotCrossLeObj2Y 3500;
BA_REL_ "GenSigTimeoutTime" BU_SG_REL_ ADC SG_ 646 ApaPscSlotCrossRiObj1Alpha 500;
BA_REL_ "GenSigTimeoutTime" BU_SG_REL_ CGW SG_ 646 ApaPscSlotCrossRiObj1Alpha 3500;
BA_REL_ "GenSigTimeoutTime" BU_SG_REL_ ADC SG_ 646 ApaPscSlotCrossRiObj1X 500;
BA_REL_ "GenSigTimeoutTime" BU_SG_REL_ CGW SG_ 646 ApaPscSlotCrossRiObj1X 3500;
BA_REL_ "GenSigTimeoutTime" BU_SG_REL_ CGW SG_ 646 ApaPscSlotParallelLeObj1Y 3500;
BA_REL_ "GenSigTimeoutTime" BU_SG_REL_ ADC SG_ 646 ApaPscSlotParallelLeObj1Y 500;
BA_REL_ "GenSigTimeoutTime" BU_SG_REL_ CGW SG_ 646 ApaPocSlotParallelRiObj1Y 3500;
BA_REL_ "GenSigTimeoutTime" BU_SG_REL_ ADC SG_ 646 ApaPocSlotParallelRiObj1Y 500;
BA_REL_ "GenSigTimeoutTime" BU_SG_REL_ CGW SG_ 646 ApaPocSlotParallelRiObj2Alpha 3500;
BA_REL_ "GenSigTimeoutTime" BU_SG_REL_ ADC SG_ 646 ApaPocSlotParallelRiObj2Alpha 500;
BA_REL_ "GenSigTimeoutTime" BU_SG_REL_ ADC SG_ 646 ApaPscSlotParallelRiObj1X 500;
BA_REL_ "GenSigTimeoutTime" BU_SG_REL_ CGW SG_ 646 ApaPscSlotParallelRiObj1X 3500;
BA_REL_ "GenSigTimeoutTime" BU_SG_REL_ CGW SG_ 646 ApaPscSlotParallelRiObj1Alpha 3500;
BA_REL_ "GenSigTimeoutTime" BU_SG_REL_ ADC SG_ 646 ApaPscSlotParallelRiObj1Alpha 500;
BA_REL_ "GenSigTimeoutTime" BU_SG_REL_ CGW SG_ 646 ApaPocSlotParallelLeObj2X 3500;
BA_REL_ "GenSigTimeoutTime" BU_SG_REL_ ADC SG_ 646 ApaPocSlotParallelLeObj2X 500;
BA_REL_ "GenSigTimeoutTime" BU_SG_REL_ ADC SG_ 646 ApaPscSlotParallelRiObj1Y 500;
BA_REL_ "GenSigTimeoutTime" BU_SG_REL_ CGW SG_ 646 ApaPscSlotParallelRiObj1Y 3500;
BA_REL_ "GenSigTimeoutTime" BU_SG_REL_ ADC SG_ 646 ApaXSlotYObj1Alpha 500;
BA_REL_ "GenSigTimeoutTime" BU_SG_REL_ CGW SG_ 646 ApaXSlotYObj1Alpha 3500;
BA_REL_ "GenSigTimeoutTime" BU_SG_REL_ ADC SG_ 646 ApaPscSlotParallelLeObj1Alpha 500;
BA_REL_ "GenSigTimeoutTime" BU_SG_REL_ CGW SG_ 646 ApaPscSlotParallelLeObj1Alpha 3500;
BA_REL_ "GenSigTimeoutTime" BU_SG_REL_ CGW SG_ 646 ApaPocSlotParallelRiObj2Y 3500;
BA_REL_ "GenSigTimeoutTime" BU_SG_REL_ ADC SG_ 646 ApaPocSlotParallelRiObj2Y 500;
BA_REL_ "GenSigTimeoutTime" BU_SG_REL_ CGW SG_ 646 ApaPscSlotCrossLeObj1Alpha 3500;
BA_REL_ "GenSigTimeoutTime" BU_SG_REL_ ADC SG_ 646 ApaPscSlotCrossLeObj1Alpha 500;
BA_REL_ "GenSigTimeoutTime" BU_SG_REL_ CGW SG_ 646 ApaXSlotYObj2X 3500;
BA_REL_ "GenSigTimeoutTime" BU_SG_REL_ ADC SG_ 646 ApaXSlotYObj2X 500;
BA_REL_ "GenSigTimeoutTime" BU_SG_REL_ CGW SG_ 646 ApaPscSlotCrossLeObj2X 3500;
BA_REL_ "GenSigTimeoutTime" BU_SG_REL_ ADC SG_ 646 ApaPscSlotCrossLeObj2X 500;
BA_REL_ "GenSigTimeoutTime" BU_SG_REL_ CGW SG_ 646 ApaPocSlotParallelRiObj2X 3500;
BA_REL_ "GenSigTimeoutTime" BU_SG_REL_ ADC SG_ 646 ApaPocSlotParallelRiObj2X 500;
BA_REL_ "GenSigTimeoutTime" BU_SG_REL_ ADC SG_ 646 ApaPocSlotParallelLeObj1X 500;
BA_REL_ "GenSigTimeoutTime" BU_SG_REL_ CGW SG_ 646 ApaPocSlotParallelLeObj1X 3500;
BA_REL_ "GenSigTimeoutTime" BU_SG_REL_ ADC SG_ 646 ApaPscSlotCrossLeObj1Y 500;
BA_REL_ "GenSigTimeoutTime" BU_SG_REL_ CGW SG_ 646 ApaPscSlotCrossLeObj1Y 3500;
BA_REL_ "GenSigTimeoutTime" BU_SG_REL_ ADC SG_ 646 ApaPscSlotParallelLeObj2Alpha 500;
BA_REL_ "GenSigTimeoutTime" BU_SG_REL_ CGW SG_ 646 ApaPscSlotParallelLeObj2Alpha 3500;
BA_REL_ "GenSigTimeoutTime" BU_SG_REL_ CGW SG_ 646 ApaPscEnvSlotTyp 500;
BA_REL_ "GenSigTimeoutTime" BU_SG_REL_ ADC SG_ 646 ApaPscEnvSlotTyp 500;
BA_REL_ "GenSigTimeoutTime" BU_SG_REL_ ADC SG_ 646 ApaPscSlotParallelLeObj2Y 500;
BA_REL_ "GenSigTimeoutTime" BU_SG_REL_ CGW SG_ 646 ApaPscSlotParallelLeObj2Y 3500;
BA_REL_ "GenSigTimeoutTime" BU_SG_REL_ CGW SG_ 646 ApaXSlotYObj1X 3500;
BA_REL_ "GenSigTimeoutTime" BU_SG_REL_ ADC SG_ 646 ApaXSlotYObj1X 500;
BA_REL_ "GenSigTimeoutTime" BU_SG_REL_ CGW SG_ 646 ApaPscSlotParallelRiObj2Y 3500;
BA_REL_ "GenSigTimeoutTime" BU_SG_REL_ ADC SG_ 646 ApaPscSlotParallelRiObj2Y 500;
BA_REL_ "GenSigTimeoutTime" BU_SG_REL_ CGW SG_ 646 ApaPscSlotCrossRiObj2X 3500;
BA_REL_ "GenSigTimeoutTime" BU_SG_REL_ ADC SG_ 646 ApaPscSlotCrossRiObj2X 500;
BA_REL_ "GenSigTimeoutTime" BU_SG_REL_ ADC SG_ 646 ApaPocSlotParallelLeObj1Alpha 500;
BA_REL_ "GenSigTimeoutTime" BU_SG_REL_ CGW SG_ 646 ApaPocSlotParallelLeObj1Alpha 3500;
BA_REL_ "GenSigTimeoutTime" BU_SG_REL_ ADC SG_ 646 ApaPscSlotCrossLeObj1X 500;
BA_REL_ "GenSigTimeoutTime" BU_SG_REL_ CGW SG_ 646 ApaPscSlotCrossLeObj1X 3500;
BA_REL_ "GenSigTimeoutTime" BU_SG_REL_ CGW SG_ 646 ApaPocSlotParallelLeObj2Y 3500;
BA_REL_ "GenSigTimeoutTime" BU_SG_REL_ ADC SG_ 646 ApaPocSlotParallelLeObj2Y 500;
BA_REL_ "GenSigTimeoutTime" BU_SG_REL_ ADC SG_ 646 ApaPscSlotCrossRiObj2Y 500;
BA_REL_ "GenSigTimeoutTime" BU_SG_REL_ CGW SG_ 646 ApaPscSlotCrossRiObj2Y 3500;
BA_REL_ "GenSigTimeoutTime" BU_SG_REL_ ADC SG_ 422 ApaPscSlotParallelRi 500;
BA_REL_ "GenSigTimeoutTime" BU_SG_REL_ CGW SG_ 422 ApaPscSlotParallelRi 500;
BA_REL_ "GenSigTimeoutTime" BU_SG_REL_ CGW SG_ 422 UpaSysSts 500;
BA_REL_ "GenSigTimeoutTime" BU_SG_REL_ ADC SG_ 422 UpaSysSts 500;
BA_REL_ "GenSigTimeoutTime" BU_SG_REL_ ADC SG_ 422 ApaPocSlotParallelLe 500;
BA_REL_ "GenSigTimeoutTime" BU_SG_REL_ CGW SG_ 422 ApaPocSlotParallelLe 500;
BA_REL_ "GenSigTimeoutTime" BU_SG_REL_ ADC SG_ 422 UpaSysSrv 500;
BA_REL_ "GenSigTimeoutTime" BU_SG_REL_ CGW SG_ 422 UpaSysSrv 500;
BA_REL_ "GenSigTimeoutTime" BU_SG_REL_ ADC SG_ 422 ApaPocSlotParallelRi 500;
BA_REL_ "GenSigTimeoutTime" BU_SG_REL_ CGW SG_ 422 ApaPocSlotParallelRi 500;
BA_REL_ "GenSigTimeoutTime" BU_SG_REL_ ADC SG_ 422 ApaPscSlotCrossLe 500;
BA_REL_ "GenSigTimeoutTime" BU_SG_REL_ CGW SG_ 422 ApaPscSlotCrossLe 500;
BA_REL_ "GenSigTimeoutTime" BU_SG_REL_ ADC SG_ 422 APA_03_MsgCntr 500;
BA_REL_ "GenSigTimeoutTime" BU_SG_REL_ CGW SG_ 422 APA_03_MsgCntr 150;
BA_REL_ "GenSigTimeoutTime" BU_SG_REL_ CGW SG_ 422 ApaInstruction 500;
BA_REL_ "GenSigTimeoutTime" BU_SG_REL_ ADC SG_ 422 ApaInstruction 500;
BA_REL_ "GenSigTimeoutTime" BU_SG_REL_ CGW SG_ 422 ApaStatus 500;
BA_REL_ "GenSigTimeoutTime" BU_SG_REL_ ADC SG_ 422 ApaStatus 500;
BA_REL_ "GenSigTimeoutTime" BU_SG_REL_ CGW SG_ 422 UpaSysDi 500;
BA_REL_ "GenSigTimeoutTime" BU_SG_REL_ ADC SG_ 422 UpaSysDi 500;
BA_REL_ "GenSigTimeoutTime" BU_SG_REL_ CGW SG_ 422 ApaAbortReason 500;
BA_REL_ "GenSigTimeoutTime" BU_SG_REL_ ADC SG_ 422 ApaAbortReason 500;
BA_REL_ "GenSigTimeoutTime" BU_SG_REL_ ADC SG_ 422 APA_03_CRC 500;
BA_REL_ "GenSigTimeoutTime" BU_SG_REL_ CGW SG_ 422 APA_03_CRC 150;
BA_REL_ "GenSigTimeoutTime" BU_SG_REL_ ADC SG_ 422 ApaPscSlotParallelLe 500;
BA_REL_ "GenSigTimeoutTime" BU_SG_REL_ CGW SG_ 422 ApaPscSlotParallelLe 500;
BA_REL_ "GenSigTimeoutTime" BU_SG_REL_ ADC SG_ 422 ApaPscSlotCrossRi 500;
BA_REL_ "GenSigTimeoutTime" BU_SG_REL_ CGW SG_ 422 ApaPscSlotCrossRi 500;
BA_REL_ "GenSigTimeoutTime" BU_SG_REL_ ADC SG_ 197 APA_02_MsgCntr 150;
BA_REL_ "GenSigTimeoutTime" BU_SG_REL_ CGW SG_ 197 APA_02_MsgCntr 150;
BA_REL_ "GenSigTimeoutTime" BU_SG_REL_ ADC SG_ 197 APA_02_CRC 150;
BA_REL_ "GenSigTimeoutTime" BU_SG_REL_ CGW SG_ 197 APA_02_CRC 150;
BA_REL_ "GenSigTimeoutTime" BU_SG_REL_ CGW SG_ 197 ApaMaxVelocity 150;
BA_REL_ "GenSigTimeoutTime" BU_SG_REL_ ADC SG_ 197 ApaMaxVelocity 150;
BA_REL_ "GenSigTimeoutTime" BU_SG_REL_ ADC SG_ 197 ApaManeuverDst 150;
BA_REL_ "GenSigTimeoutTime" BU_SG_REL_ CGW SG_ 197 ApaManeuverDst 150;
BA_REL_ "GenSigTimeoutTime" BU_SG_REL_ CGW SG_ 196 APA_EPSReqTyp 150;
BA_REL_ "GenSigTimeoutTime" BU_SG_REL_ ADC SG_ 196 APA_EPSReqTyp 150;
BA_REL_ "GenSigTimeoutTime" BU_SG_REL_ CGW SG_ 196 AbsltPinionAgReq 150;
BA_REL_ "GenSigTimeoutTime" BU_SG_REL_ ADC SG_ 196 AbsltPinionAgReq 150;
BA_REL_ "GenSigTimeoutTime" BU_SG_REL_ CGW SG_ 196 APASts 150;
BA_REL_ "GenSigTimeoutTime" BU_SG_REL_ ADC SG_ 196 APASts 150;
BA_REL_ "GenSigTimeoutTime" BU_SG_REL_ ADC SG_ 196 AbsltPinionAgReqValid 150;
BA_REL_ "GenSigTimeoutTime" BU_SG_REL_ CGW SG_ 196 AbsltPinionAgReqValid 150;
BA_REL_ "GenSigTimeoutTime" BU_SG_REL_ CGW SG_ 196 APA_01_CRC 150;
BA_REL_ "GenSigTimeoutTime" BU_SG_REL_ ADC SG_ 196 APA_01_CRC 150;
BA_REL_ "GenSigTimeoutTime" BU_SG_REL_ ADC SG_ 196 APA_01_MsgCntr 150;
BA_REL_ "GenSigTimeoutTime" BU_SG_REL_ CGW SG_ 196 APA_01_MsgCntr 150;
BA_REL_ "GenSigTimeoutTime" BU_SG_REL_ CGW SG_ 556 ADCVoltWakeupReq 150;
BA_REL_ "GenSigTimeoutTime" BU_SG_REL_ RAD_RR SG_ 62 ACM_03_CRC 150;
BA_REL_ "GenSigTimeoutTime" BU_SG_REL_ RAD_FR SG_ 62 ACM_03_CRC 150;
BA_REL_ "GenSigTimeoutTime" BU_SG_REL_ RAD_FL SG_ 62 ACM_03_CRC 150;
BA_REL_ "GenSigTimeoutTime" BU_SG_REL_ RAD_RL SG_ 62 ACM_03_CRC 150;
BA_REL_ "GenSigTimeoutTime" BU_SG_REL_ APA SG_ 62 ACM_03_CRC 150;
BA_REL_ "GenSigTimeoutTime" BU_SG_REL_ RAD_FC SG_ 62 ACM_03_CRC 150;
BA_REL_ "GenSigTimeoutTime" BU_SG_REL_ RAD_RR SG_ 62 LgtAValSts 150;
BA_REL_ "GenSigTimeoutTime" BU_SG_REL_ RAD_FC SG_ 62 LgtAValSts 150;
BA_REL_ "GenSigTimeoutTime" BU_SG_REL_ RAD_FL SG_ 62 LgtAValSts 150;
BA_REL_ "GenSigTimeoutTime" BU_SG_REL_ APA SG_ 62 LgtAValSts 150;
BA_REL_ "GenSigTimeoutTime" BU_SG_REL_ RAD_FR SG_ 62 LgtAValSts 150;
BA_REL_ "GenSigTimeoutTime" BU_SG_REL_ RAD_RL SG_ 62 LgtAValSts 150;
BA_REL_ "GenSigTimeoutTime" BU_SG_REL_ RAD_RL SG_ 62 ACM_03_MsgCntr 150;
BA_REL_ "GenSigTimeoutTime" BU_SG_REL_ RAD_FL SG_ 62 ACM_03_MsgCntr 150;
BA_REL_ "GenSigTimeoutTime" BU_SG_REL_ RAD_FC SG_ 62 ACM_03_MsgCntr 150;
BA_REL_ "GenSigTimeoutTime" BU_SG_REL_ RAD_RR SG_ 62 ACM_03_MsgCntr 150;
BA_REL_ "GenSigTimeoutTime" BU_SG_REL_ RAD_FR SG_ 62 ACM_03_MsgCntr 150;
BA_REL_ "GenSigTimeoutTime" BU_SG_REL_ APA SG_ 62 ACM_03_MsgCntr 150;
BA_REL_ "GenSigTimeoutTime" BU_SG_REL_ RAD_RL SG_ 62 LgtA 150;
BA_REL_ "GenSigTimeoutTime" BU_SG_REL_ APA SG_ 62 LgtA 150;
BA_REL_ "GenSigTimeoutTime" BU_SG_REL_ RAD_FR SG_ 62 LgtA 150;
BA_REL_ "GenSigTimeoutTime" BU_SG_REL_ RAD_FL SG_ 62 LgtA 150;
BA_REL_ "GenSigTimeoutTime" BU_SG_REL_ RAD_RR SG_ 62 LgtA 150;
BA_REL_ "GenSigTimeoutTime" BU_SG_REL_ RAD_FC SG_ 62 LgtA 150;
BA_REL_ "GenSigTimeoutTime" BU_SG_REL_ APA SG_ 61 ACM_02_CRC 150;
BA_REL_ "GenSigTimeoutTime" BU_SG_REL_ RAD_FC SG_ 61 ACM_02_CRC 150;
BA_REL_ "GenSigTimeoutTime" BU_SG_REL_ RAD_FL SG_ 61 ACM_02_CRC 150;
BA_REL_ "GenSigTimeoutTime" BU_SG_REL_ RAD_FR SG_ 61 ACM_02_CRC 150;
BA_REL_ "GenSigTimeoutTime" BU_SG_REL_ RAD_RL SG_ 61 ACM_02_CRC 150;
BA_REL_ "GenSigTimeoutTime" BU_SG_REL_ RAD_RR SG_ 61 ACM_02_CRC 150;
BA_REL_ "GenSigTimeoutTime" BU_SG_REL_ RAD_FC SG_ 61 LatAValSts 150;
BA_REL_ "GenSigTimeoutTime" BU_SG_REL_ RAD_FR SG_ 61 LatAValSts 150;
BA_REL_ "GenSigTimeoutTime" BU_SG_REL_ RAD_RR SG_ 61 LatAValSts 150;
BA_REL_ "GenSigTimeoutTime" BU_SG_REL_ RAD_FL SG_ 61 LatAValSts 150;
BA_REL_ "GenSigTimeoutTime" BU_SG_REL_ RAD_RL SG_ 61 LatAValSts 150;
BA_REL_ "GenSigTimeoutTime" BU_SG_REL_ APA SG_ 61 LatAValSts 150;
BA_REL_ "GenSigTimeoutTime" BU_SG_REL_ RAD_FC SG_ 61 YawRateValSts 150;
BA_REL_ "GenSigTimeoutTime" BU_SG_REL_ APA SG_ 61 YawRateValSts 150;
BA_REL_ "GenSigTimeoutTime" BU_SG_REL_ RAD_FR SG_ 61 YawRateValSts 150;
BA_REL_ "GenSigTimeoutTime" BU_SG_REL_ RAD_FL SG_ 61 YawRateValSts 150;
BA_REL_ "GenSigTimeoutTime" BU_SG_REL_ RAD_RL SG_ 61 YawRateValSts 150;
BA_REL_ "GenSigTimeoutTime" BU_SG_REL_ RAD_RR SG_ 61 YawRateValSts 150;
BA_REL_ "GenSigTimeoutTime" BU_SG_REL_ APA SG_ 61 ACM_02_MsgCntr 150;
BA_REL_ "GenSigTimeoutTime" BU_SG_REL_ RAD_FC SG_ 61 ACM_02_MsgCntr 150;
BA_REL_ "GenSigTimeoutTime" BU_SG_REL_ RAD_RR SG_ 61 ACM_02_MsgCntr 150;
BA_REL_ "GenSigTimeoutTime" BU_SG_REL_ RAD_RL SG_ 61 ACM_02_MsgCntr 150;
BA_REL_ "GenSigTimeoutTime" BU_SG_REL_ RAD_FR SG_ 61 ACM_02_MsgCntr 150;
BA_REL_ "GenSigTimeoutTime" BU_SG_REL_ RAD_FL SG_ 61 ACM_02_MsgCntr 150;
BA_REL_ "GenSigTimeoutTime" BU_SG_REL_ RAD_FL SG_ 61 YawRate 150;
BA_REL_ "GenSigTimeoutTime" BU_SG_REL_ RAD_RR SG_ 61 YawRate 150;
BA_REL_ "GenSigTimeoutTime" BU_SG_REL_ RAD_FC SG_ 61 YawRate 150;
BA_REL_ "GenSigTimeoutTime" BU_SG_REL_ RAD_FR SG_ 61 YawRate 150;
BA_REL_ "GenSigTimeoutTime" BU_SG_REL_ APA SG_ 61 YawRate 150;
BA_REL_ "GenSigTimeoutTime" BU_SG_REL_ RAD_RL SG_ 61 YawRate 150;
BA_REL_ "GenSigTimeoutTime" BU_SG_REL_ RAD_FC SG_ 61 LatA 150;
BA_REL_ "GenSigTimeoutTime" BU_SG_REL_ RAD_FR SG_ 61 LatA 150;
BA_REL_ "GenSigTimeoutTime" BU_SG_REL_ APA SG_ 61 LatA 150;
BA_REL_ "GenSigTimeoutTime" BU_SG_REL_ RAD_FL SG_ 61 LatA 150;
BA_REL_ "GenSigTimeoutTime" BU_SG_REL_ RAD_RR SG_ 61 LatA 150;
BA_REL_ "GenSigTimeoutTime" BU_SG_REL_ RAD_RL SG_ 61 LatA 150;
VAL_ 425 sens05De3Distance_APA 511 "Sna" 510 "NoObject" 509 "PresenceDetection" ;
VAL_ 425 sens08De2Quality_APA 15 "Sna" ;
VAL_ 425 sens03De2Quality_APA 15 "Sna" ;
VAL_ 425 sens12De2Distance_APA 511 "Sna" 510 "NoObject" 509 "PresenceDetection" ;
VAL_ 425 sens01De3Distance_APA 511 "Sna" 510 "NoObject" 509 "PresenceDetection" ;
VAL_ 425 sens02De1Quality_APA 15 "Sna" ;
VAL_ 425 sens07De3Quality_APA 15 "Sna" ;
VAL_ 425 sens05De1Quality_APA 15 "Sna" ;
VAL_ 425 sens10De2Distance_APA 511 "Sna" 510 "NoObject" 509 "PresenceDetection" ;
VAL_ 425 sens08De1Quality_APA 15 "Sna" ;
VAL_ 425 sens06De1Quality_APA 15 "Sna" ;
VAL_ 425 sens10De3Quality_APA 15 "Sna" ;
VAL_ 425 sens12De1Distance_APA 511 "Sna" 510 "NoObject" 509 "PresenceDetection" ;
VAL_ 425 sens11De1Quality_APA 15 "Sna" ;
VAL_ 425 sens11De2Distance_APA 511 "Sna" 510 "NoObject" 509 "PresenceDetection" ;
VAL_ 425 sens03De2Distance_APA 511 "Sna" 510 "NoObject" 509 "PresenceDetection" ;
VAL_ 425 sens12De3Distance_APA 511 "Sna" 510 "NoObject" 509 "PresenceDetection" ;
VAL_ 425 sens09De1Distance_APA 511 "Sna" 510 "NoObject" 509 "PresenceDetection" ;
VAL_ 425 sens04De1Quality_APA 15 "Sna" ;
VAL_ 425 sens01De2Distance_APA 511 "Sna" 510 "NoObject" 509 "PresenceDetection" ;
VAL_ 425 sens07De3Distance_APA 511 "Sna" 510 "NoObject" 509 "PresenceDetection" ;
VAL_ 425 sens07De2Quality_APA 15 "Sna" ;
VAL_ 425 sens04De1Distance_APA 511 "Sna" 510 "NoObject" 509 "PresenceDetection" ;
VAL_ 425 sens04De3Distance_APA 511 "Sna" 510 "NoObject" 509 "PresenceDetection" ;
VAL_ 425 sens04De2Distance_APA 511 "Sna" 510 "NoObject" 509 "PresenceDetection" ;
VAL_ 425 sens08De3Quality_APA 15 "Sna" ;
VAL_ 425 sens07De1Quality_APA 15 "Sna" ;
VAL_ 425 sens10De2Quality_APA 15 "Sna" ;
VAL_ 425 sens01De2Quality_APA 15 "Sna" ;
VAL_ 425 sens09De2Quality_APA 15 "Sna" ;
VAL_ 425 sens06De3Distance_APA 511 "Sna" 510 "NoObject" 509 "PresenceDetection" ;
VAL_ 425 sens09De1Quality_APA 15 "Sna" ;
VAL_ 425 sens06De1Distance_APA 511 "Sna" 510 "NoObject" 509 "PresenceDetection" ;
VAL_ 425 sens07De2Distance_APA 511 "Sna" 510 "NoObject" 509 "PresenceDetection" ;
VAL_ 425 deMsgSensorIdx_APA 10 "Sensor 11 Direct Echoes" 9 "Sensor 10 Direct Echoes" 8 "Sensor 9 Direct Echoes" 7 "Sensor 8 Direct Echoes" 6 "Sensor 7 Direct Echoes" 5 "Sensor 6 Direct Echoes" 4 "Sensor 5 Direct Echoes" 3 "Sensor 4 Direct Echoes" 2 "Sensor 3 Direct Echoes" 1 "Sensor 2 Direct Echoes" 0 "Sensor 1 Direct Echoes" ;
VAL_ 425 sens12De2Quality_APA 15 "Sna" ;
VAL_ 425 sens10De1Quality_APA 15 "Sna" ;
VAL_ 425 sens04De3Quality_APA 15 "Sna" ;
VAL_ 425 sens11De3Quality_APA 15 "Sna" ;
VAL_ 425 sens03De1Quality_APA 15 "Sna" ;
VAL_ 425 sens12De1Quality_APA 15 "Sna" ;
VAL_ 425 sens09De3Quality_APA 15 "Sna" ;
VAL_ 425 sens05De2Quality_APA 15 "Sna" ;
VAL_ 425 sens06De3Quality_APA 15 "Sna" ;
VAL_ 425 sens01De3Quality_APA 15 "Sna" ;
VAL_ 425 sens09De2Distance_APA 511 "Sna" 510 "NoObject" 509 "PresenceDetection" ;
VAL_ 425 sens11De3Distance_APA 511 "Sna" 510 "NoObject" 509 "PresenceDetection" ;
VAL_ 425 sens02De2Distance_APA 511 "Sna" 510 "NoObject" 509 "PresenceDetection" ;
VAL_ 425 sens02De2Quality_APA 15 "Sna" ;
VAL_ 425 sens11De1Distance_APA 511 "Sna" 510 "NoObject" 509 "PresenceDetection" ;
VAL_ 425 sens02De1Distance_APA 511 "Sna" 510 "NoObject" 509 "PresenceDetection" ;
VAL_ 425 sens05De1Distance_APA 511 "Sna" 510 "NoObject" 509 "PresenceDetection" ;
VAL_ 425 sens03De3Quality_APA 15 "Sna" ;
VAL_ 425 sens08De2Distance_APA 511 "Sna" 510 "NoObject" 509 "PresenceDetection" ;
VAL_ 425 sens05De2Distance_APA 511 "Sna" 510 "NoObject" 509 "PresenceDetection" ;
VAL_ 425 sens06De2Distance_APA 511 "Sna" 510 "NoObject" 509 "PresenceDetection" ;
VAL_ 425 sens04De2Quality_APA 15 "Sna" ;
VAL_ 425 sens08De1Distance_APA 511 "Sna" 510 "NoObject" 509 "PresenceDetection" ;
VAL_ 425 sens10De3Distance_APA 511 "Sna" 510 "NoObject" 509 "PresenceDetection" ;
VAL_ 425 sens05De3Quality_APA 15 "Sna" ;
VAL_ 425 sens07De1Distance_APA 511 "Sna" 510 "NoObject" 509 "PresenceDetection" ;
VAL_ 425 sens10De1Distance_APA 511 "Sna" 510 "NoObject" 509 "PresenceDetection" ;
VAL_ 425 sens02De3Quality_APA 15 "Sna" ;
VAL_ 425 sens12De3Quality_APA 15 "Sna" ;
VAL_ 425 sens06De2Quality_APA 15 "Sna" ;
VAL_ 425 sens03De3Distance_APA 511 "Sna" 510 "NoObject" 509 "PresenceDetection" ;
VAL_ 425 sens09De3Distance_APA 511 "Sna" 510 "NoObject" 509 "PresenceDetection" ;
VAL_ 425 sens03De1Distance_APA 511 "Sna" 510 "NoObject" 509 "PresenceDetection" ;
VAL_ 425 sens11De2Quality_APA 15 "Sna" ;
VAL_ 425 sens01De1Quality_APA 15 "Sna" ;
VAL_ 425 sens08De3Distance_APA 511 "Sna" 510 "NoObject" 509 "PresenceDetection" ;
VAL_ 425 sens02De3Distance_APA 511 "Sna" 510 "NoObject" 509 "PresenceDetection" ;
VAL_ 425 sens01De1Distance_APA 511 "Sna" 510 "NoObject" 509 "PresenceDetection" ;
VAL_ 424 Sens06CeRgt3Quality 15 "Sna" ;
VAL_ 424 Sens08CeRgt1Distance 255 "Sna" 254 "NoObject" 253 "PresenceDetection" 252 "SensorFaulted" ;
VAL_ 424 Sens09CeRgt3Distance 255 "Sna" 254 "NoObject" 253 "PresenceDetection" 252 "SensorFaulted" ;
VAL_ 424 Sens06CeRgt1Distance 255 "Sna" 254 "NoObject" 253 "PresenceDetection" 252 "SensorFaulted" ;
VAL_ 424 Sens02CeRgt3Quality 15 "Sna" ;
VAL_ 424 Sens04CeRgt2Quality 15 "Sna" ;
VAL_ 424 Sens05CeRgt2Quality 15 "Sna" ;
VAL_ 424 Sens04CeRgt3Quality 15 "Sna" ;
VAL_ 424 CeRgtMsgSensorIdx 11 "Sensor 12 Cross Echoes" 10 "Sensor 11 Cross Echoes" 9 "Sensor 10 Cross Echoes" 8 "Sensor 9 Cross Echoes" 7 "Sensor 8 Cross Echoes" 6 "Sensor 7 Cross Echoes" 5 "Sensor 6 Cross Echoes" 4 "Sensor 5 Cross Echoes" 3 "Sensor 4 Cross Echoes" 2 "Sensor 3 Cross Echoes" 1 "Sensor 2 Cross Echoes" 0 "Sensor 1 Cross Echoes" ;
VAL_ 424 Sens06CeRgt3Distance 255 "Sna" 254 "NoObject" 253 "PresenceDetection" 252 "SensorFaulted" ;
VAL_ 424 Sens10CeRgt3Distance 255 "Sna" 254 "NoObject" 253 "PresenceDetection" 252 "SensorFaulted" ;
VAL_ 424 Sens11CeRgt1Distance 255 "Sna" 254 "NoObject" 253 "PresenceDetection" 252 "SensorFaulted" ;
VAL_ 424 Sens05CeRgt3Quality 15 "Sna" ;
VAL_ 424 Sens06CeRgt1Quality 15 "Sna" ;
VAL_ 424 Sens11CeRgt1Quality 15 "Sna" ;
VAL_ 424 Sens01CeRgt1Quality 15 "Sna" ;
VAL_ 424 Sens04CeRgt2Distance 255 "Sna" 254 "NoObject" 253 "PresenceDetection" 252 "SensorFaulted" ;
VAL_ 424 Sens04CeRgt1Distance 255 "Sna" 254 "NoObject" 253 "PresenceDetection" 252 "SensorFaulted" ;
VAL_ 424 Sens11CeRgt2Distance 255 "Sna" 254 "NoObject" 253 "PresenceDetection" 252 "SensorFaulted" ;
VAL_ 424 Sens10CeRgt1Distance 255 "Sna" 254 "NoObject" 253 "PresenceDetection" 252 "SensorFaulted" ;
VAL_ 424 Sens12CeRgt3Quality 15 "Sna" ;
VAL_ 424 Sens12CeRgt3Distance 255 "Sna" 254 "NoObject" 253 "PresenceDetection" 252 "SensorFaulted" ;
VAL_ 424 Sens04CeRgt1Quality 15 "Sna" ;
VAL_ 424 Sens08CeRgt2Distance 255 "Sna" 254 "NoObject" 253 "PresenceDetection" 252 "SensorFaulted" ;
VAL_ 424 Sens03CeRgt1Quality 15 "Sna" ;
VAL_ 424 Sens12CeRgt1Distance 255 "Sna" 254 "NoObject" 253 "PresenceDetection" 252 "SensorFaulted" ;
VAL_ 424 Sens02CeRgt2Distance 255 "Sna" 254 "NoObject" 253 "PresenceDetection" 252 "SensorFaulted" ;
VAL_ 424 Sens08CeRgt1Quality 15 "Sna" ;
VAL_ 424 Sens08CeRgt3Distance 255 "Sna" 254 "NoObject" 253 "PresenceDetection" 252 "SensorFaulted" ;
VAL_ 424 Sens08CeRgt2Quality 15 "Sna" ;
VAL_ 424 Sens01CeRgt3Distance 255 "Sna" 254 "NoObject" 253 "PresenceDetection" 252 "SensorFaulted" ;
VAL_ 424 Sens09CeRgt1Distance 255 "Sna" 254 "NoObject" 253 "PresenceDetection" 252 "SensorFaulted" ;
VAL_ 424 Sens07CeRgt2Quality 15 "Sna" ;
VAL_ 424 Sens08CeRgt3Quality 15 "Sna" ;
VAL_ 424 Sens03CeRgt3Distance 255 "Sna" 254 "NoObject" 253 "PresenceDetection" 252 "SensorFaulted" ;
VAL_ 424 Sens05CeRgt1Quality 15 "Sna" ;
VAL_ 424 Sens07CeRgt2Distance 255 "Sna" 254 "NoObject" 253 "PresenceDetection" 252 "SensorFaulted" ;
VAL_ 424 Sens02CeRgt3Distance 255 "Sna" 254 "NoObject" 253 "PresenceDetection" 252 "SensorFaulted" ;
VAL_ 424 Sens02CeRgt1Quality 15 "Sna" ;
VAL_ 424 Sens07CeRgt3Distance 255 "Sna" 254 "NoObject" 253 "PresenceDetection" 252 "SensorFaulted" ;
VAL_ 424 Sens03CeRgt2Quality 15 "Sna" ;
VAL_ 424 Sens09CeRgt2Distance 255 "Sna" 254 "NoObject" 253 "PresenceDetection" 252 "SensorFaulted" ;
VAL_ 424 Sens01CeRgt2Quality 15 "Sna" ;
VAL_ 424 Sens01CeRgt1Distance 255 "Sna" 254 "NoObject" 253 "PresenceDetection" 252 "SensorFaulted" ;
VAL_ 424 Sens05CeRgt3Distance 255 "Sna" 254 "NoObject" 253 "PresenceDetection" 252 "SensorFaulted" ;
VAL_ 424 Sens11CeRgt2Quality 15 "Sna" ;
VAL_ 424 Sens06CeRgt2Quality 15 "Sna" ;
VAL_ 424 Sens10CeRgt3Quality 15 "Sna" ;
VAL_ 424 Sens09CeRgt1Quality 15 "Sna" ;
VAL_ 424 Sens12CeRgt2Distance 255 "Sna" 254 "NoObject" 253 "PresenceDetection" 252 "SensorFaulted" ;
VAL_ 424 Sens11CeRgt3Quality 15 "Sna" ;
VAL_ 424 Sens05CeRgt1Distance 255 "Sna" 254 "NoObject" 253 "PresenceDetection" 252 "SensorFaulted" ;
VAL_ 424 Sens06CeRgt2Distance 255 "Sna" 254 "NoObject" 253 "PresenceDetection" 252 "SensorFaulted" ;
VAL_ 424 Sens01CeRgt2Distance 255 "Sna" 254 "NoObject" 253 "PresenceDetection" 252 "SensorFaulted" ;
VAL_ 424 Sens09CeRgt3Quality 15 "Sna" ;
VAL_ 424 Sens05CeRgt2Distance 255 "Sna" 254 "NoObject" 253 "PresenceDetection" 252 "SensorFaulted" ;
VAL_ 424 Sens07CeRgt1Distance 255 "Sna" 254 "NoObject" 253 "PresenceDetection" 252 "SensorFaulted" ;
VAL_ 424 Sens01CeRgt3Quality 15 "Sna" ;
VAL_ 424 Sens03CeRgt1Distance 255 "Sna" 254 "NoObject" 253 "PresenceDetection" 252 "SensorFaulted" ;
VAL_ 424 Sens02CeRgt2Quality 15 "Sna" ;
VAL_ 424 Sens12CeRgt2Quality 15 "Sna" ;
VAL_ 424 Sens10CeRgt2Quality 15 "Sna" ;
VAL_ 424 Sens10CeRgt2Distance 255 "Sna" 254 "NoObject" 253 "PresenceDetection" 252 "SensorFaulted" ;
VAL_ 424 Sens12CeRgt1Quality 15 "Sna" ;
VAL_ 424 Sens11CeRgt3Distance 255 "Sna" 254 "NoObject" 253 "PresenceDetection" 252 "SensorFaulted" ;
VAL_ 424 Sens02CeRgt1Distance 255 "Sna" 254 "NoObject" 253 "PresenceDetection" 252 "SensorFaulted" ;
VAL_ 424 Sens03CeRgt3Quality 15 "Sna" ;
VAL_ 424 Sens10CeRgt1Quality 15 "Sna" ;
VAL_ 424 Sens09CeRgt2Quality 15 "Sna" ;
VAL_ 424 Sens07CeRgt1Quality 15 "Sna" ;
VAL_ 424 Sens07CeRgt3Quality 15 "Sna" ;
VAL_ 424 Sens04CeRgt3Distance 255 "Sna" 254 "NoObject" 253 "PresenceDetection" 252 "SensorFaulted" ;
VAL_ 424 Sens03CeRgt2Distance 255 "Sna" 254 "NoObject" 253 "PresenceDetection" 252 "SensorFaulted" ;
VAL_ 423 Sens03CeLft3Quality 15 "Sna" ;
VAL_ 423 Sens02CeLft1Distance 255 "Sna" 254 "NoObject" 253 "PresenceDetection" 252 "SensorFaulted" ;
VAL_ 423 Sens01CeLft1Distance 255 "Sna" 254 "NoObject" 253 "PresenceDetection" 252 "SensorFaulted" ;
VAL_ 423 Sens10CeLft1Quality 15 "Sna" ;
VAL_ 423 Sens04CeLft2Distance 255 "Sna" 254 "NoObject" 253 "PresenceDetection" 252 "SensorFaulted" ;
VAL_ 423 Sens05CeLft3Quality 15 "Sna" ;
VAL_ 423 Sens03CeLft2Quality 15 "Sna" ;
VAL_ 423 Sens03CeLft1Quality 15 "Sna" ;
VAL_ 423 Sens12CeLft2Quality 15 "Sna" ;
VAL_ 423 Sens01CeLft2Quality 15 "Sna" ;
VAL_ 423 Sens11CeLft2Quality 15 "Sna" ;
VAL_ 423 Sens05CeLft1Distance 255 "Sna" 254 "NoObject" 253 "PresenceDetection" 252 "SensorFaulted" ;
VAL_ 423 Sens06CeLft2Quality 15 "Sna" ;
VAL_ 423 Sens08CeLft1Distance 255 "Sna" 254 "NoObject" 253 "PresenceDetection" 252 "SensorFaulted" ;
VAL_ 423 Sens03CeLft2Distance 255 "Sna" 254 "NoObject" 253 "PresenceDetection" 252 "SensorFaulted" ;
VAL_ 423 Sens10CeLft1Distance 255 "Sna" 254 "NoObject" 253 "PresenceDetection" 252 "SensorFaulted" ;
VAL_ 423 Sens07CeLft3Distance 255 "Sna" 254 "NoObject" 253 "PresenceDetection" 252 "SensorFaulted" ;
VAL_ 423 Sens10CeLft2Distance 255 "Sna" 254 "NoObject" 253 "PresenceDetection" 252 "SensorFaulted" ;
VAL_ 423 Sens11CeLft3Distance 255 "Sna" 254 "NoObject" 253 "PresenceDetection" 252 "SensorFaulted" ;
VAL_ 423 Sens09CeLft1Distance 255 "Sna" 254 "NoObject" 253 "PresenceDetection" 252 "SensorFaulted" ;
VAL_ 423 Sens02CeLft3Quality 15 "Sna" ;
VAL_ 423 Sens06CeLft1Distance 255 "Sna" 254 "NoObject" 253 "PresenceDetection" 252 "SensorFaulted" ;
VAL_ 423 Sens04CeLft3Distance 255 "Sna" 254 "NoObject" 253 "PresenceDetection" 252 "SensorFaulted" ;
VAL_ 423 Sens08CeLft3Quality 15 "Sna" ;
VAL_ 423 Sens08CeLft2Quality 15 "Sna" ;
VAL_ 423 Sens04CeLft3Quality 15 "Sna" ;
VAL_ 423 Sens07CeLft3Quality 15 "Sna" ;
VAL_ 423 Sens09CeLft2Distance 255 "Sna" 254 "NoObject" 253 "PresenceDetection" 252 "SensorFaulted" ;
VAL_ 423 Sens11CeLft3Quality 15 "Sna" ;
VAL_ 423 Sens10CeLft3Distance 255 "Sna" 254 "NoObject" 253 "PresenceDetection" 252 "SensorFaulted" ;
VAL_ 423 Sens08CeLft2Distance 255 "Sna" 254 "NoObject" 253 "PresenceDetection" 252 "SensorFaulted" ;
VAL_ 423 Sens06CeLft3Quality 15 "Sna" ;
VAL_ 423 Sens09CeLft3Distance 255 "Sna" 254 "NoObject" 253 "PresenceDetection" 252 "SensorFaulted" ;
VAL_ 423 Sens01CeLft1Quality 15 "Sna" ;
VAL_ 423 Sens09CeLft2Quality 15 "Sna" ;
VAL_ 423 Sens10CeLft3Quality 15 "Sna" ;
VAL_ 423 Sens05CeLft2Quality 15 "Sna" ;
VAL_ 423 Sens01CeLft3Quality 15 "Sna" ;
VAL_ 423 Sens06CeLft3Distance 255 "Sna" 254 "NoObject" 253 "PresenceDetection" 252 "SensorFaulted" ;
VAL_ 423 Sens07CeLft2Distance 255 "Sna" 254 "NoObject" 253 "PresenceDetection" 252 "SensorFaulted" ;
VAL_ 423 Sens02CeLft2Quality 15 "Sna" ;
VAL_ 423 Sens07CeLft1Distance 255 "Sna" 254 "NoObject" 253 "PresenceDetection" 252 "SensorFaulted" ;
VAL_ 423 Sens01CeLft2Distance 255 "Sna" 254 "NoObject" 253 "PresenceDetection" 252 "SensorFaulted" ;
VAL_ 423 Sens07CeLft1Quality 15 "Sna" ;
VAL_ 423 Sens12CeLft2Distance 255 "Sna" 254 "NoObject" 253 "PresenceDetection" 252 "SensorFaulted" ;
VAL_ 423 Sens11CeLft2Distance 255 "Sna" 254 "NoObject" 253 "PresenceDetection" 252 "SensorFaulted" ;
VAL_ 423 Sens09CeLft3Quality 15 "Sna" ;
VAL_ 423 Sens05CeLft2Distance 255 "Sna" 254 "NoObject" 253 "PresenceDetection" 252 "SensorFaulted" ;
VAL_ 423 Sens07CeLft2Quality 15 "Sna" ;
VAL_ 423 Sens03CeLft1Distance 255 "Sna" 254 "NoObject" 253 "PresenceDetection" 252 "SensorFaulted" ;
VAL_ 423 Sens03CeLft3Distance 255 "Sna" 254 "NoObject" 253 "PresenceDetection" 252 "SensorFaulted" ;
VAL_ 423 Sens01CeLft3Distance 255 "Sna" 254 "NoObject" 253 "PresenceDetection" 252 "SensorFaulted" ;
VAL_ 423 Sens04CeLft2Quality 15 "Sna" ;
VAL_ 423 Sens12CeLft1Quality 15 "Sna" ;
VAL_ 423 Sens04CeLft1Distance 255 "Sna" 254 "NoObject" 253 "PresenceDetection" 252 "SensorFaulted" ;
VAL_ 423 Sens02CeLft1Quality 15 "Sna" ;
VAL_ 423 Sens12CeLft3Distance 255 "Sna" 254 "NoObject" 253 "PresenceDetection" 252 "SensorFaulted" ;
VAL_ 423 Sens09CeLft1Quality 15 "Sna" ;
VAL_ 423 Sens06CeLft2Distance 255 "Sna" 254 "NoObject" 253 "PresenceDetection" 252 "SensorFaulted" ;
VAL_ 423 Sens11CeLft1Quality 15 "Sna" ;
VAL_ 423 Sens10CeLft2Quality 15 "Sna" ;
VAL_ 423 Sens12CeLft1Distance 255 "Sna" 254 "NoObject" 253 "PresenceDetection" 252 "SensorFaulted" ;
VAL_ 423 Sens11CeLft1Distance 255 "Sna" 254 "NoObject" 253 "PresenceDetection" 252 "SensorFaulted" ;
VAL_ 423 Sens05CeLft1Quality 15 "Sna" ;
VAL_ 423 CeLftMsgSensorIdx 11 "Sensor 12 Cross Echoes" 10 "Sensor 11 Cross Echoes" 9 "Sensor 10 Cross Echoes" 8 "Sensor 9 Cross Echoes" 7 "Sensor 8 Cross Echoes" 6 "Sensor 7 Cross Echoes" 5 "Sensor 6 Cross Echoes" 4 "Sensor 5 Cross Echoes" 3 "Sensor 4 Cross Echoes" 2 "Sensor 3 Cross Echoes" 1 "Sensor 2 Cross Echoes" 0 "Sensor 1 Cross Echoes" ;
VAL_ 423 Sens06CeLft1Quality 15 "Sna" ;
VAL_ 423 Sens02CeLft2Distance 255 "Sna" 254 "NoObject" 253 "PresenceDetection" 252 "SensorFaulted" ;
VAL_ 423 Sens12CeLft3Quality 15 "Sna" ;
VAL_ 423 Sens08CeLft1Quality 15 "Sna" ;
VAL_ 423 Sens04CeLft1Quality 15 "Sna" ;
VAL_ 423 Sens05CeLft3Distance 255 "Sna" 254 "NoObject" 253 "PresenceDetection" 252 "SensorFaulted" ;
VAL_ 423 Sens02CeLft3Distance 255 "Sna" 254 "NoObject" 253 "PresenceDetection" 252 "SensorFaulted" ;
VAL_ 423 Sens08CeLft3Distance 255 "Sna" 254 "NoObject" 253 "PresenceDetection" 252 "SensorFaulted" ;
VAL_ 357 MapObj19P1Y 1023 "Sna" ;
VAL_ 357 MapObj09Problty 7 "Sna" ;
VAL_ 357 MapObj09P1Y 1023 "Sna" ;
VAL_ 357 MapObj09P1X 1023 "Sna" ;
VAL_ 357 MapObj19Problty 7 "Sna" ;
VAL_ 357 MapObj09P2X 1023 "Sna" ;
VAL_ 357 MapObj19P2X 1023 "Sna" ;
VAL_ 357 MapObj19Typ 7 "Sna" 5 "Straight2Corner" 3 "Straight1Corner" 2 "Straight0Corner" 1 "Point" 0 "None" ;
VAL_ 357 MapObj09HeiProblty 7 "Sna" ;
VAL_ 357 MapObj09Hei 3 "Unknown" 2 "Traversable" 1 "High" 0 "Low" ;
VAL_ 357 MapObj09P2Y 1023 "Sna" ;
VAL_ 357 MapObj09Typ 7 "Sna" 5 "Straight2Corner" 3 "Straight1Corner" 2 "Straight0Corner" 1 "Point" 0 "None" ;
VAL_ 357 MapObj19P2Y 1023 "Sna" ;
VAL_ 357 MapObjX9Offs 4 "MAP Object 40" 3 "MAP Object 30" 2 "MAP Object 20" 1 "MAP Object 10" 0 "MAP Object 00" ;
VAL_ 357 MapObj19HeiProblty 7 "Sna" ;
VAL_ 357 MapObj19Hei 3 "Unknown" 2 "Traversable" 1 "High" 0 "Low" ;
VAL_ 357 MapObj19P1X 1023 "Sna" ;
VAL_ 356 MapObj08P1X 1023 "Sna" ;
VAL_ 356 MapObj08P2Y 1023 "Sna" ;
VAL_ 356 MapObj08Hei 3 "Unknown" 2 "Traversable" 1 "High" 0 "Low" ;
VAL_ 356 MapObjX8Offs 4 "MAP Object 40" 3 "MAP Object 30" 2 "MAP Object 20" 1 "MAP Object 10" 0 "MAP Object 00" ;
VAL_ 356 MapObj08HeiProblty 7 "Sna" ;
VAL_ 356 MapObj18Hei 3 "Unknown" 2 "Traversable" 1 "High" 0 "Low" ;
VAL_ 356 MapObj18P2X 1023 "Sna" ;
VAL_ 356 MapObj08P2X 1023 "Sna" ;
VAL_ 356 MapObj08P1Y 1023 "Sna" ;
VAL_ 356 MapObj18HeiProblty 7 "Sna" ;
VAL_ 356 MapObj08Typ 7 "Sna" 5 "Straight2Corner" 3 "Straight1Corner" 2 "Straight0Corner" 1 "Point" 0 "None" ;
VAL_ 356 MapObj08Problty 7 "Sna" ;
VAL_ 356 MapObj18Typ 7 "Sna" 5 "Straight2Corner" 3 "Straight1Corner" 2 "Straight0Corner" 1 "Point" 0 "None" ;
VAL_ 356 MapObj18P1X 1023 "Sna" ;
VAL_ 356 MapObj18Problty 7 "Sna" ;
VAL_ 356 MapObj18P1Y 1023 "Sna" ;
VAL_ 356 MapObj18P2Y 1023 "Sna" ;
VAL_ 355 MapObj17HeiProblty 7 "Sna" ;
VAL_ 355 MapObj17Problty 7 "Sna" ;
VAL_ 355 MapObj07P2X 1023 "Sna" ;
VAL_ 355 MapObj07P1X 1023 "Sna" ;
VAL_ 355 MapObj07P1Y 1023 "Sna" ;
VAL_ 355 MapObj07Problty 7 "Sna" ;
VAL_ 355 MapObj07Typ 7 "Sna" 5 "Straight2Corner" 3 "Straight1Corner" 2 "Straight0Corner" 1 "Point" 0 "None" ;
VAL_ 355 MapObj17Typ 7 "Sna" 5 "Straight2Corner" 3 "Straight1Corner" 2 "Straight0Corner" 1 "Point" 0 "None" ;
VAL_ 355 MapObj07HeiProblty 7 "Sna" ;
VAL_ 355 MapObj07Hei 3 "Unknown" 2 "Traversable" 1 "High" 0 "Low" ;
VAL_ 355 MapObj17P2X 1023 "Sna" ;
VAL_ 355 MapObj17P2Y 1023 "Sna" ;
VAL_ 355 MapObj07P2Y 1023 "Sna" ;
VAL_ 355 MapObjX7Offs 4 "MAP Object 40" 3 "MAP Object 30" 2 "MAP Object 20" 1 "MAP Object 10" 0 "MAP Object 00" ;
VAL_ 355 MapObj17P1Y 1023 "Sna" ;
VAL_ 355 MapObj17P1X 1023 "Sna" ;
VAL_ 355 MapObj17Hei 3 "Unknown" 2 "Traversable" 1 "High" 0 "Low" ;
VAL_ 354 MapObj16P2X 1023 "Sna" ;
VAL_ 354 MapObj06Typ 7 "Sna" 5 "Straight2Corner" 3 "Straight1Corner" 2 "Straight0Corner" 1 "Point" 0 "None" ;
VAL_ 354 MapObj06Hei 3 "Unknown" 2 "Traversable" 1 "High" 0 "Low" ;
VAL_ 354 MapObj16P2Y 1023 "Sna" ;
VAL_ 354 MapObj16Problty 7 "Sna" ;
VAL_ 354 MapObj06P1Y 1023 "Sna" ;
VAL_ 354 MapObj16P1Y 1023 "Sna" ;
VAL_ 354 MapObj06HeiProblty 7 "Sna" ;
VAL_ 354 MapObj16Hei 3 "Unknown" 2 "Traversable" 1 "High" 0 "Low" ;
VAL_ 354 MapObj06Problty 7 "Sna" ;
VAL_ 354 MapObj06P1X 1023 "Sna" ;
VAL_ 354 MapObj16P1X 1023 "Sna" ;
VAL_ 354 MapObj06P2X 1023 "Sna" ;
VAL_ 354 MapObj16Typ 7 "Sna" 5 "Straight2Corner" 3 "Straight1Corner" 2 "Straight0Corner" 1 "Point" 0 "None" ;
VAL_ 354 MapObj16HeiProblty 7 "Sna" ;
VAL_ 354 MapObjX6Offs 4 "MAP Object 40" 3 "MAP Object 30" 2 "MAP Object 20" 1 "MAP Object 10" 0 "MAP Object 00" ;
VAL_ 354 MapObj06P2Y 1023 "Sna" ;
VAL_ 353 MapObjX5Offs 4 "MAP Object 40" 3 "MAP Object 30" 2 "MAP Object 20" 1 "MAP Object 10" 0 "MAP Object 00" ;
VAL_ 353 MapObj15Hei 3 "Unknown" 2 "Traversable" 1 "High" 0 "Low" ;
VAL_ 353 MapObj15Problty 7 "Sna" ;
VAL_ 353 MapObj15Typ 7 "Sna" 5 "Straight2Corner" 3 "Straight1Corner" 2 "Straight0Corner" 1 "Point" 0 "None" ;
VAL_ 353 MapObj15HeiProblty 7 "Sna" ;
VAL_ 353 MapObj15P1Y 1023 "Sna" ;
VAL_ 353 MapObj05P1Y 1023 "Sna" ;
VAL_ 353 MapObj05P1X 1023 "Sna" ;
VAL_ 353 MapObj05Typ 7 "Sna" 5 "Straight2Corner" 3 "Straight1Corner" 2 "Straight0Corner" 1 "Point" 0 "None" ;
VAL_ 353 MapObj05Problty 7 "Sna" ;
VAL_ 353 MapObj05Hei 3 "Unknown" 2 "Traversable" 1 "High" 0 "Low" ;
VAL_ 353 MapObj15P2Y 1023 "Sna" ;
VAL_ 353 MapObj15P2X 1023 "Sna" ;
VAL_ 353 MapObj05P2X 1023 "Sna" ;
VAL_ 353 MapObj15P1X 1023 "Sna" ;
VAL_ 353 MapObj05P2Y 1023 "Sna" ;
VAL_ 353 MapObj05HeiProblty 7 "Sna" ;
VAL_ 352 MapObj14Problty 7 "Sna" ;
VAL_ 352 MapObj04Problty 7 "Sna" ;
VAL_ 352 MapObj04P1Y 1023 "Sna" ;
VAL_ 352 MapObj04Typ 7 "Sna" 5 "Straight2Corner" 3 "Straight1Corner" 2 "Straight0Corner" 1 "Point" 0 "None" ;
VAL_ 352 MapObj14P1Y 1023 "Sna" ;
VAL_ 352 MapObj14Typ 7 "Sna" 5 "Straight2Corner" 3 "Straight1Corner" 2 "Straight0Corner" 1 "Point" 0 "None" ;
VAL_ 352 MapObj04Hei 3 "Unknown" 2 "Traversable" 1 "High" 0 "Low" ;
VAL_ 352 MapObj14P2Y 1023 "Sna" ;
VAL_ 352 MapObj14P1X 1023 "Sna" ;
VAL_ 352 MapObj04P1X 1023 "Sna" ;
VAL_ 352 MapObj14P2X 1023 "Sna" ;
VAL_ 352 MapObjX4Offs 4 "MAP Object 40" 3 "MAP Object 30" 2 "MAP Object 20" 1 "MAP Object 10" 0 "MAP Object 00" ;
VAL_ 352 MapObj14Hei 3 "Unknown" 2 "Traversable" 1 "High" 0 "Low" ;
VAL_ 352 MapObj04P2Y 1023 "Sna" ;
VAL_ 352 MapObj04P2X 1023 "Sna" ;
VAL_ 352 MapObj04HeiProblty 7 "Sna" ;
VAL_ 352 MapObj14HeiProblty 7 "Sna" ;
VAL_ 351 MapObj13P1X 1023 "Sna" ;
VAL_ 351 MapObjX3Offs 4 "MAP Object 40" 3 "MAP Object 30" 2 "MAP Object 20" 1 "MAP Object 10" 0 "MAP Object 00" ;
VAL_ 351 MapObj13P1Y 1023 "Sna" ;
VAL_ 351 MapObj13HeiProblty 7 "Sna" ;
VAL_ 351 MapObj03P2X 1023 "Sna" ;
VAL_ 351 MapObj03P2Y 1023 "Sna" ;
VAL_ 351 MapObj13Problty 7 "Sna" ;
VAL_ 351 MapObj03Problty 7 "Sna" ;
VAL_ 351 MapObj13Hei 3 "Unknown" 2 "Traversable" 1 "High" 0 "Low" ;
VAL_ 351 MapObj03P1Y 1023 "Sna" ;
VAL_ 351 MapObj13Typ 7 "Sna" 5 "Straight2Corner" 3 "Straight1Corner" 2 "Straight0Corner" 1 "Point" 0 "None" ;
VAL_ 351 MapObj03P1X 1023 "Sna" ;
VAL_ 351 MapObj13P2Y 1023 "Sna" ;
VAL_ 351 MapObj03Hei 3 "Unknown" 2 "Traversable" 1 "High" 0 "Low" ;
VAL_ 351 MapObj13P2X 1023 "Sna" ;
VAL_ 351 MapObj03Typ 7 "Sna" 5 "Straight2Corner" 3 "Straight1Corner" 2 "Straight0Corner" 1 "Point" 0 "None" ;
VAL_ 351 MapObj03HeiProblty 7 "Sna" ;
VAL_ 350 MapObj02P2Y 1023 "Sna" ;
VAL_ 350 MapObj02Typ 7 "Sna" 5 "Straight2Corner" 3 "Straight1Corner" 2 "Straight0Corner" 1 "Point" 0 "None" ;
VAL_ 350 MapObj02P2X 1023 "Sna" ;
VAL_ 350 MapObj12P2Y 1023 "Sna" ;
VAL_ 350 MapObj12P2X 1023 "Sna" ;
VAL_ 350 MapObj12Hei 3 "Unknown" 2 "Traversable" 1 "High" 0 "Low" ;
VAL_ 350 MapObj02HeiProblty 7 "Sna" ;
VAL_ 350 MapObj12P1Y 1023 "Sna" ;
VAL_ 350 MapObj12Problty 7 "Sna" ;
VAL_ 350 MapObj02Problty 7 "Sna" ;
VAL_ 350 MapObj12HeiProblty 7 "Sna" ;
VAL_ 350 MapObj02P1Y 1023 "Sna" ;
VAL_ 350 MapObj02Hei 3 "Unknown" 2 "Traversable" 1 "High" 0 "Low" ;
VAL_ 350 MapObj02P1X 1023 "Sna" ;
VAL_ 350 MapObj12P1X 1023 "Sna" ;
VAL_ 350 MapObjX2Offs 4 "MAP Object 40" 3 "MAP Object 30" 2 "MAP Object 20" 1 "MAP Object 10" 0 "MAP Object 00" ;
VAL_ 350 MapObj12Typ 7 "Sna" 5 "Straight2Corner" 3 "Straight1Corner" 2 "Straight0Corner" 1 "Point" 0 "None" ;
VAL_ 349 MapObj01Hei 3 "Unknown" 2 "Traversable" 1 "High" 0 "Low" ;
VAL_ 349 MapObj01P1Y 1023 "Sna" ;
VAL_ 349 MapObj11P1Y 1023 "Sna" ;
VAL_ 349 MapObj01P1X 1023 "Sna" ;
VAL_ 349 MapObj11P2Y 1023 "Sna" ;
VAL_ 349 MapObj11Hei 3 "Unknown" 2 "Traversable" 1 "High" 0 "Low" ;
VAL_ 349 MapObj11P1X 1023 "Sna" ;
VAL_ 349 MapObj11Problty 7 "Sna" ;
VAL_ 349 MapObj01Problty 7 "Sna" ;
VAL_ 349 MapObj11P2X 1023 "Sna" ;
VAL_ 349 MapObj11Typ 7 "Sna" 5 "Straight2Corner" 3 "Straight1Corner" 2 "Straight0Corner" 1 "Point" 0 "None" ;
VAL_ 349 MapObj01HeiProblty 7 "Sna" ;
VAL_ 349 MapObjX1Offs 4 "MAP Object 40" 3 "MAP Object 30" 2 "MAP Object 20" 1 "MAP Object 10" 0 "MAP Object 00" ;
VAL_ 349 MapObj11HeiProblty 7 "Sna" ;
VAL_ 349 MapObj01Typ 7 "Sna" 5 "Straight2Corner" 3 "Straight1Corner" 2 "Straight0Corner" 1 "Point" 0 "None" ;
VAL_ 349 MapObj01P2X 1023 "Sna" ;
VAL_ 349 MapObj01P2Y 1023 "Sna" ;
VAL_ 348 MapObj10P2Y 1023 "Sna" ;
VAL_ 348 MapObj10Problty 7 "Sna" ;
VAL_ 348 MapObj00Problty 7 "Sna" ;
VAL_ 348 MapObj00P2X 1023 "Sna" ;
VAL_ 348 MapObj10Typ 7 "Sna" 5 "Straight2Corner" 3 "Straight1Corner" 2 "Straight0Corner" 1 "Point" 0 "None" ;
VAL_ 348 MapObj00HeiProblty 7 "Sna" ;
VAL_ 348 MapObj10P2X 1023 "Sna" ;
VAL_ 348 MapObj00P1Y 1023 "Sna" ;
VAL_ 348 MapObj10HeiProblty 7 "Sna" ;
VAL_ 348 MapObj00Typ 7 "Sna" 5 "Straight2Corner" 3 "Straight1Corner" 2 "Straight0Corner" 1 "Point" 0 "None" ;
VAL_ 348 MapObj10Hei 3 "Unknown" 2 "Traversable" 1 "High" 0 "Low" ;
VAL_ 348 MapObjX0Offs 4 "MAP Object 40" 3 "MAP Object 30" 2 "MAP Object 20" 1 "MAP Object 10" 0 "MAP Object 00" ;
VAL_ 348 MapObj10P1Y 1023 "Sna" ;
VAL_ 348 MapObj00P2Y 1023 "Sna" ;
VAL_ 348 MapObj10P1X 1023 "Sna" ;
VAL_ 348 MapObj00Hei 3 "Unknown" 2 "Traversable" 1 "High" 0 "Low" ;
VAL_ 348 MapObj00P1X 1023 "Sna" ;
VAL_ 648 ApaPscSlotCrossRiVehY 2047 "Sna" 2046 "NoSpace" ;
VAL_ 648 ApaXSlotYVehX 2047 "Sna" 2046 "NoSpace" ;
VAL_ 648 ApaPocSlotParallelRiVehY 2047 "Sna" 2046 "NoSpace" ;
VAL_ 648 ApaPocSlotParallelLeSizeY 255 "Sna" 254 "NoSpace" ;
VAL_ 648 ApaPscSlotCrossLeVehX 2047 "Sna" 2046 "NoSpace" ;
VAL_ 648 ApaXSlotYSizeX 255 "Sna" 254 "NoSpace" ;
VAL_ 648 ApaPscSlotCrossRiVehPsi 8191 "Sna" 8190 "NoSpace" ;
VAL_ 648 ApaPocSlotParallelRiVehPsi 8191 "Sna" 8190 "NoSpace" ;
VAL_ 648 ApaPocSlotParallelRiSizeX 255 "Sna" 254 "NoSpace" ;
VAL_ 648 ApaPocSlotParallelRiSizeY 255 "Sna" 254 "NoSpace" ;
VAL_ 648 ApaPscSlotCrossRiSizeY 255 "Sna" 254 "NoSpace" ;
VAL_ 648 ApaPscSlotParallelRiVehX 2047 "Sna" 2046 "NoSpace" ;
VAL_ 648 ApaPscSlotParallelLeVehPsi 8191 "Sna" 8190 "NoSpace" ;
VAL_ 648 ApaPocSlotParallelLeVehY 2047 "Sna" 2046 "NoSpace" ;
VAL_ 648 ApaXSlotYSizeY 255 "Sna" 254 "NoSpace" ;
VAL_ 648 ApaXSlotYVehPsi 8191 "Sna" 8190 "NoSpace" ;
VAL_ 648 ApaPscSlotParallelRiSizeX 255 "Sna" 254 "NoSpace" ;
VAL_ 648 ApaPscSlotParallelLeVehY 2047 "Sna" 2046 "NoSpace" ;
VAL_ 648 ApaPscSlotParallelLeSizeX 255 "Sna" 254 "NoSpace" ;
VAL_ 648 ApaPocSlotParallelLeVehPsi 8191 "Sna" 8190 "NoSpace" ;
VAL_ 648 ApaPscSlotParallelRiSizeY 255 "Sna" 254 "NoSpace" ;
VAL_ 648 ApaPocSlotParallelLeSizeX 255 "Sna" 254 "NoSpace" ;
VAL_ 648 ApaPscSlotCrossLeVehPsi 8191 "Sna" 8190 "NoSpace" ;
VAL_ 648 ApaPscSlotCrossRiVehX 2047 "Sna" 2046 "NoSpace" ;
VAL_ 648 ApaPscVehSlotTyp 7 "Sna" 5 "RightPOC" 4 "LeftPOC" 3 "RightCross" 2 "LeftCross" 1 "RightParallel" 0 "LeftParallel" ;
VAL_ 648 ApaPocSlotParallelLeVehX 2047 "Sna" 2046 "NoSpace" ;
VAL_ 648 ApaPscSlotCrossLeSizeX 255 "Sna" 254 "NoSpace" ;
VAL_ 648 ApaPscSlotParallelLeSizeY 255 "Sna" 254 "NoSpace" ;
VAL_ 648 ApaPscSlotParallelLeVehX 2047 "Sna" 2046 "NoSpace" ;
VAL_ 648 ApaPscSlotParallelRiVehPsi 8191 "Sna" 8190 "NoSpace" ;
VAL_ 648 ApaXSlotYVehY 2047 "Sna" 2046 "NoSpace" ;
VAL_ 648 ApaPscSlotParallelRiVehY 2047 "Sna" 2046 "NoSpace" ;
VAL_ 648 ApaPscSlotCrossRiSizeX 255 "Sna" 254 "NoSpace" ;
VAL_ 648 ApaPscSlotCrossLeVehY 2047 "Sna" 2046 "NoSpace" ;
VAL_ 648 ApaPocSlotParallelRiVehX 2047 "Sna" 2046 "NoSpace" ;
VAL_ 648 ApaPscSlotCrossLeSizeY 255 "Sna" 254 "NoSpace" ;
VAL_ 651 ReLeMidRegnDst 255 "Sna" 254 "NoObject" ;
VAL_ 651 ReLeRegnDst 255 "Sna" 254 "NoObject" ;
VAL_ 651 ReSnsrFltSt 3 "Sna" 2 "TemporaryFailure" 1 "PermanentFailure" 0 "NoFailure" ;
VAL_ 651 ReRiMidRegnDst 255 "Sna" 254 "NoObject" ;
VAL_ 651 ReRiRegnDst 255 "Sna" 254 "NoObject" ;
VAL_ 651 ReMidRegnDst 255 "Sna" 254 "NoObject" ;
VAL_ 651 ReSysSts 1 "Enabled" 0 "Disabled" ;
VAL_ 650 FrntRiRegnDst 255 "Sna" 254 "NoObject" ;
VAL_ 650 FrntLeRegnDst 255 "Sna" 254 "NoObject" ;
VAL_ 650 FrntSnsrFltSt 3 "Sna" 2 "TemporaryFailure" 1 "PermanentFailure" 0 "NoFailure" ;
VAL_ 650 FrntMidRegnDst 255 "Sna" 254 "NoObject" ;
VAL_ 650 FrntLeMidRegnDst 255 "Sna" 254 "NoObject" ;
VAL_ 650 FrntRiMidRegnDst 255 "Sna" 254 "NoObject" ;
VAL_ 650 FrntSysSts 1 "Enabled" 0 "Disabled" ;
VAL_ 646 ApaPscSlotCrossRiObj2Alpha 127 "Sna" 126 "NoSpace" ;
VAL_ 646 ApaXSlotYObj1Y 2047 "Sna" 2046 "NoSpace" ;
VAL_ 646 ApaXSlotYObj2Y 2047 "Sna" 2046 "NoSpace" ;
VAL_ 646 ApaXSlotYObj2Alpha 127 "Sna" 126 "NoSpace" ;
VAL_ 646 ApaPocSlotParallelLeObj1Y 2047 "Sna" 2046 "NoSpace" ;
VAL_ 646 ApaPscSlotParallelRiObj2Alpha 127 "Sna" 126 "NoSpace" ;
VAL_ 646 ApaPscSlotCrossRiObj1Y 2047 "Sna" 2046 "NoSpace" ;
VAL_ 646 ApaPscSlotParallelRiObj2X 2047 "Sna" 2046 "NoSpace" ;
VAL_ 646 ApaPscSlotParallelLeObj2X 2047 "Sna" 2046 "NoSpace" ;
VAL_ 646 ApaPocSlotParallelRiObj1X 2047 "Sna" 2046 "NoSpace" ;
VAL_ 646 ApaPocSlotParallelLeObj2Alpha 127 "Sna" 126 "NoSpace" ;
VAL_ 646 ApaPocSlotParallelRiObj1Alpha 127 "Sna" 126 "NoSpace" ;
VAL_ 646 ApaPscSlotCrossLeObj2Alpha 127 "Sna" 126 "NoSpace" ;
VAL_ 646 ApaPscSlotParallelLeObj1X 2047 "Sna" 2046 "NoSpace" ;
VAL_ 646 ApaPscSlotCrossLeObj2Y 2047 "Sna" 2046 "NoSpace" ;
VAL_ 646 ApaPscSlotCrossRiObj1Alpha 127 "Sna" 126 "NoSpace" ;
VAL_ 646 ApaPscSlotCrossRiObj1X 2047 "Sna" 2046 "NoSpace" ;
VAL_ 646 ApaPscSlotParallelLeObj1Y 2047 "Sna" 2046 "NoSpace" ;
VAL_ 646 ApaPocSlotParallelRiObj1Y 2047 "Sna" 2046 "NoSpace" ;
VAL_ 646 ApaPocSlotParallelRiObj2Alpha 127 "Sna" 126 "NoSpace" ;
VAL_ 646 ApaPscSlotParallelRiObj1X 2047 "Sna" 2046 "NoSpace" ;
VAL_ 646 ApaPscSlotParallelRiObj1Alpha 127 "Sna" 126 "NoSpace" ;
VAL_ 646 ApaPocSlotParallelLeObj2X 2047 "Sna" 2046 "NoSpace" ;
VAL_ 646 ApaPscSlotParallelRiObj1Y 2047 "Sna" 2046 "NoSpace" ;
VAL_ 646 ApaXSlotYObj1Alpha 127 "Sna" 126 "NoSpace" ;
VAL_ 646 ApaPscSlotParallelLeObj1Alpha 127 "Sna" 126 "NoSpace" ;
VAL_ 646 ApaPocSlotParallelRiObj2Y 2047 "Sna" 2046 "NoSpace" ;
VAL_ 646 ApaPscSlotCrossLeObj1Alpha 127 "Sna" 126 "NoSpace" ;
VAL_ 646 ApaXSlotYObj2X 2047 "Sna" 2046 "NoSpace" ;
VAL_ 646 ApaPscSlotCrossLeObj2X 2047 "Sna" 2046 "NoSpace" ;
VAL_ 646 ApaPocSlotParallelRiObj2X 2047 "Sna" 2046 "NoSpace" ;
VAL_ 646 ApaPocSlotParallelLeObj1X 2047 "Sna" 2046 "NoSpace" ;
VAL_ 646 ApaPscSlotCrossLeObj1Y 2047 "Sna" 2046 "NoSpace" ;
VAL_ 646 ApaPscSlotParallelLeObj2Alpha 127 "Sna" 126 "NoSpace" ;
VAL_ 646 ApaPscEnvSlotTyp 7 "Sna" 5 "RightPOC" 4 "LeftPOC" 3 "RightCross" 2 "LeftCross" 1 "RightParallel" 0 "LeftParallel" ;
VAL_ 646 ApaPscSlotParallelLeObj2Y 2047 "Sna" 2046 "NoSpace" ;
VAL_ 646 ApaXSlotYObj1X 2047 "Sna" 2046 "NoSpace" ;
VAL_ 646 ApaPscSlotParallelRiObj2Y 2047 "Sna" 2046 "NoSpace" ;
VAL_ 646 ApaPscSlotCrossRiObj2X 2047 "Sna" 2046 "NoSpace" ;
VAL_ 646 ApaPocSlotParallelLeObj1Alpha 127 "Sna" 126 "NoSpace" ;
VAL_ 646 ApaPscSlotCrossLeObj1X 2047 "Sna" 2046 "NoSpace" ;
VAL_ 646 ApaPocSlotParallelLeObj2Y 2047 "Sna" 2046 "NoSpace" ;
VAL_ 646 ApaPscSlotCrossRiObj2Y 2047 "Sna" 2046 "NoSpace" ;
VAL_ 422 ApaPscSlotParallelRi 3 "PSOkPosOk" 2 "PSOk" 1 "PSUnsuitable" 0 "PSNone" ;
VAL_ 422 UpaSysSts 7 "Sna" 2 "Failed" 1 "Active" 0 "Standby" ;
VAL_ 422 ApaPocSlotParallelLe 3 "PSOkPosOk" 2 "PSOk" 1 "PSUnsuitable" 0 "PSNone" ;
VAL_ 422 UpaSysSrv 1 "Service" 0 "NoFailure" ;
VAL_ 422 ApaPocSlotParallelRi 3 "PSOkPosOk" 2 "PSOk" 1 "PSUnsuitable" 0 "PSNone" ;
VAL_ 422 ApaPscSlotCrossLe 3 "PSOkPosOk" 2 "PSOk" 1 "PSUnsuitable" 0 "PSNone" ;
VAL_ 422 ApaInstruction 7 "Sna" 5 "Abort" 4 "GuidanceFinished" 3 "DriveBackward" 2 "DriveForward" 1 "Stop" 0 "NoMessage" ;
VAL_ 422 ApaStatus 15 "Sna" 4 "Abort" 3 "GuidanceActive" 2 "Preguidance" 1 "Search" 0 "Standby" ;
VAL_ 422 UpaSysDi 1 "SystemDisabled" 0 "NoFaulure" ;
VAL_ 422 ApaAbortReason 255 "Sna" 62 "InternalCode31" 61 "InternalCode30" 60 "InternalCode29" 59 "InternalCode28" 58 "InternalCode27" 57 "InternalCode26" 56 "InternalCode25" 55 "InternalCode24" 54 "InternalCode23" 53 "InternalCode22" 52 "InternalCode21" 51 "InternalCode20" 50 "InternalCode19" 49 "InternalCode18" 48 "InternalCode17" 47 "InternalCode16" 46 "InternalCode15" 45 "InternalCode14" 44 "InternalCode13" 43 "InternalCode12" 42 "InternalCode11" 41 "InternalCode10" 40 "InternalCode09" 39 "InternalCode08" 38 "InternalCode07" 37 "InternalCode06" 36 "InternalCode05" 35 "InternalCode04" 34 "InternalCode03" 33 "InternalCode02" 32 "InternalCode01" 8 "SystemDisabled" 7 "ServiceSystem" 6 "ManualAbort" 5 "EPSFaulted" 4 "HandsOnDetected" 3 "DoorOpen" 2 "VehDynIntervention" 1 "VelocityTooHigh" 0 "None" ;
VAL_ 422 ApaPscSlotParallelLe 3 "PSOkPosOk" 2 "PSOk" 1 "PSUnsuitable" 0 "PSNone" ;
VAL_ 422 ApaPscSlotCrossRi 3 "PSOkPosOk" 2 "PSOk" 1 "PSUnsuitable" 0 "PSNone" ;
VAL_ 197 ApaMaxVelocity 63 "Sna" ;
VAL_ 197 ApaManeuverDst 2047 "Sna" ;
VAL_ 196 APA_EPSReqTyp 7 " Reserved" 6 " Reserved" 5 " Reserved" 4 " Reserved" 3 " Active absolute pinion angle request" 2 " Reserved" 1 " Reserved" 0 " No request" ;
VAL_ 196 APASts 15 " Invalid" 5 " - 14 Reserved" 4 " Failed" 3 " Active" 2 " Enabled" 1 " Standby enable" 0 " Disabled" ;
VAL_ 196 AbsltPinionAgReqValid 1 " Invalid" 0 " Valid" ;
VAL_ 556 ADCVoltWakeupReq 3 "Invalid" 2 "Reserved" 1 "Request" 0 "No request(default)" ;
VAL_ 62 LgtAValSts 3 " Initializing" 2 " Reserved" 1 " Invalid" 0 " Normal (Valid)" ;
VAL_ 62 AxAyYrsCalSts 3 "Signal not available" 2 "Reserved" 1 "Calibrated" 0 "Not Calibrated" ;
VAL_ 61 LatAValSts 3 " Initializing" 2 " Reserved" 1 " Invalid" 0 " Normal (Valid)" ;
VAL_ 61 YawRateValSts 3 " Initializing" 2 " Reserved" 1 " Invalid" 0 " Normal (Valid)" ;
